[part 2 of 3: package /CommunicationClusters]
AUTOSAR XML (schema 4-2-2)
package /CommunicationClusters  (continued)
  can cluster ZCUD_CAN1: baudrate=500000, protocol-name=CAN, protocol-version=CAN
    can physical channel ZCUD_CAN1: comm-connectors=ZCUD_CAN1_SRS3
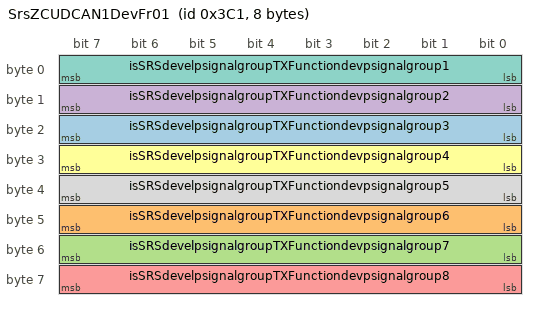
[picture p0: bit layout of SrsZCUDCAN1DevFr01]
      frame SrsZCUDCAN1DevFr01: id 0x3C1, from SRS3, frame-length=8, can-addressing-mode=STANDARD, can-fd-frame-support=false, can-frame-tx-behavior=CAN-20
        pdu SrsZCUDCAN1DevSignalPdu01: length=8, minimum-delay=0.095, transmission-mode-condition{data-filter=data-filter-type=ALWAYS, i-signal-in-i-pdu=igSRSdevelpsignalgroupTX_mtx}, transmission-mode-true-timing=event-controlled-timing=number-of-repetitions=0, unused-bit-pattern=0
          signal isSRSdevelpsignalgroupTXFunctiondevpsignalgroup3: start 23, 8 bit, big-endian, data-type-policy=NETWORK-REPRESENTATION-FROM-COM-SPEC, init-value=0, base-type=UInt8_2, compu-method=UInt8_1, category=VALUE, transfer-property=TRIGGERED  # SRS development signal
          signal isSRSdevelpsignalgroupTXFunctiondevpsignalgroup6: start 47, 8 bit, big-endian, data-type-policy=NETWORK-REPRESENTATION-FROM-COM-SPEC, init-value=0, base-type=UInt8_2, compu-method=UInt8_1, category=VALUE, transfer-property=TRIGGERED  # SRS development signal
          signal isSRSdevelpsignalgroupTXFunctiondevpsignalgroup7: start 55, 8 bit, big-endian, data-type-policy=NETWORK-REPRESENTATION-FROM-COM-SPEC, init-value=0, base-type=UInt8_2, compu-method=UInt8_1, category=VALUE, transfer-property=TRIGGERED  # SRS development signal
          signal isSRSdevelpsignalgroupTXFunctiondevpsignalgroup2: start 15, 8 bit, big-endian, data-type-policy=NETWORK-REPRESENTATION-FROM-COM-SPEC, init-value=0, base-type=UInt8_2, compu-method=UInt8_1, category=VALUE, transfer-property=TRIGGERED  # SRS development signal
          signal isSRSdevelpsignalgroupTXFunctiondevpsignalgroup8: start 63, 8 bit, big-endian, data-type-policy=NETWORK-REPRESENTATION-FROM-COM-SPEC, init-value=0, base-type=UInt8_2, compu-method=UInt8_1, category=VALUE, transfer-property=TRIGGERED  # SRS development signal
          signal isSRSdevelpsignalgroupTXFunctiondevpsignalgroup4: start 31, 8 bit, big-endian, data-type-policy=NETWORK-REPRESENTATION-FROM-COM-SPEC, init-value=0, base-type=UInt8_2, compu-method=UInt8_1, category=VALUE, transfer-property=TRIGGERED  # SRS development signal
          signal isSRSdevelpsignalgroupTXFunctiondevpsignalgroup1: start 7, 8 bit, big-endian, data-type-policy=NETWORK-REPRESENTATION-FROM-COM-SPEC, init-value=0, base-type=UInt8_2, compu-method=UInt8_1, category=VALUE, transfer-property=TRIGGERED  # SRS development signal
          signal isSRSdevelpsignalgroupTXFunctiondevpsignalgroup5: start 39, 8 bit, big-endian, data-type-policy=NETWORK-REPRESENTATION-FROM-COM-SPEC, init-value=0, base-type=UInt8_2, compu-method=UInt8_1, category=VALUE, transfer-property=TRIGGERED  # SRS development signal
          mapping igSRSdevelpsignalgroupTX_mtx: i-signal-group=igSRSdevelpsignalgroupTX, packing-byte-order=big-endian, start-position=7, transfer-property=TRIGGERED
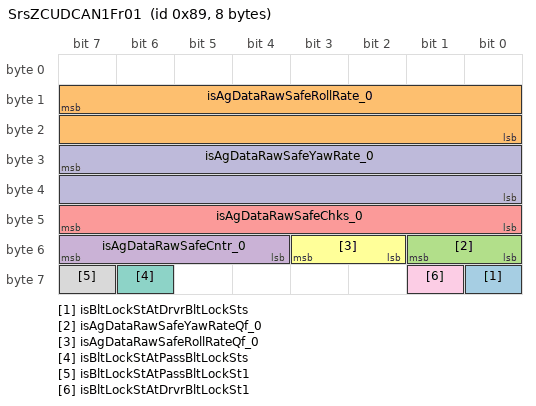
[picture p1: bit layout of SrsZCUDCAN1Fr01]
      frame SrsZCUDCAN1Fr01: id 0x89, from SRS3, frame-length=8, can-addressing-mode=STANDARD, can-fd-frame-support=false, can-frame-tx-behavior=CAN-20
        pdu SrsZCUDCAN1SignalPdu01: length=8, transmission-mode-condition{data-filter=data-filter-type=ALWAYS, i-signal-in-i-pdu=igAgDataRawSafe_0_mtx}, transmission-mode-true-timing=cyclic-timing={time-offset=0.0, time-period=0.01}, unused-bit-pattern=0
          signal isBltLockStAtDrvrBltLockSts: start 56, 1 bit, big-endian, data-type-policy=NETWORK-REPRESENTATION-FROM-COM-SPEC, init-value=0, base-type=DevErrSts2_2, compu-method=DevErrSts2_1, category=VALUE, transfer-property=PENDING  # State of belt lock at driver seating position Belt lock status, OK/NOK
          signal isAgDataRawSafeRollRate_0: start 15, 16 bit, big-endian, data-type-policy=NETWORK-REPRESENTATION-FROM-COM-SPEC, init-value=0, base-type=AgSpd34_2, compu-method=AgSpd34_1, category=VALUE, transfer-property=PENDING  # IMU angular rate data. Roll Rate
          signal isAgDataRawSafeYawRateQf_0: start 49, 2 bit, big-endian, data-type-policy=NETWORK-REPRESENTATION-FROM-COM-SPEC, init-value=1, base-type=Qf1_2, compu-method=Qf1_1, category=VALUE, transfer-property=PENDING  # IMU angular rate data. Quality Factor for Yaw Rate
          signal isAgDataRawSafeCntr_0: start 55, 4 bit, big-endian, data-type-policy=NETWORK-REPRESENTATION-FROM-COM-SPEC, init-value=0, base-type=UInt4_2, compu-method=UInt4_1, category=VALUE, transfer-property=PENDING  # IMU angular rate data. Counter
          signal isAgDataRawSafeChks_0: start 47, 8 bit, big-endian, data-type-policy=NETWORK-REPRESENTATION-FROM-COM-SPEC, init-value=255, base-type=UInt8_2, compu-method=UInt8_1, category=VALUE, transfer-property=PENDING  # IMU angular rate data. Check summa
          signal isAgDataRawSafeRollRateQf_0: start 51, 2 bit, big-endian, data-type-policy=NETWORK-REPRESENTATION-FROM-COM-SPEC, init-value=1, base-type=Qf1_2, compu-method=Qf1_1, category=VALUE, transfer-property=PENDING  # IMU angular rate data. Quality factor for Roll Rate
          signal isBltLockStAtPassBltLockSts: start 62, 1 bit, big-endian, data-type-policy=NETWORK-REPRESENTATION-FROM-COM-SPEC, init-value=0, base-type=DevErrSts2_2, compu-method=DevErrSts2_1, category=VALUE, transfer-property=PENDING  # State of belt lock at passenger seating position Belt lock status, OK/NOK
          signal isBltLockStAtPassBltLockSt1: start 63, 1 bit, big-endian, data-type-policy=NETWORK-REPRESENTATION-FROM-COM-SPEC, init-value=1, base-type=BltLockSt1_2, compu-method=BltLockSt1_1, category=VALUE, transfer-property=PENDING  # State of belt lock at passenger seating position Belt lock state, locked/unlocked
          signal isBltLockStAtDrvrBltLockSt1: start 57, 1 bit, big-endian, data-type-policy=NETWORK-REPRESENTATION-FROM-COM-SPEC, init-value=1, base-type=BltLockSt1_2, compu-method=BltLockSt1_1, category=VALUE, transfer-property=PENDING  # State of belt lock at driver seating position Belt lock state, locked/unlocked
          signal isAgDataRawSafeYawRate_0: start 31, 16 bit, big-endian, data-type-policy=NETWORK-REPRESENTATION-FROM-COM-SPEC, init-value=0, base-type=AgSpd34_2, compu-method=AgSpd34_1, category=VALUE, transfer-property=PENDING  # IMU angular rate data. Yaw Rate
          mapping igBltLockStAtPass_mtx: i-signal-group=igBltLockStAtPass, packing-byte-order=big-endian, start-position=63, transfer-property=PENDING, update-indication-bit-position=6
          mapping igBltLockStAtDrvr_mtx: i-signal-group=igBltLockStAtDrvr, packing-byte-order=big-endian, start-position=57, transfer-property=PENDING, update-indication-bit-position=7
          mapping igAgDataRawSafe_0_mtx: i-signal-group=igAgDataRawSafe_0, packing-byte-order=big-endian, start-position=15, transfer-property=PENDING, update-indication-bit-position=5
      frame SrsZCUDCAN1Fr11: id 0x22F, from SRS3, frame-length=8, can-addressing-mode=STANDARD, can-fd-frame-support=false, can-frame-tx-behavior=CAN-20
        pdu SrsZCUDCAN1SignalPdu11: length=8, transmission-mode-condition{data-filter=data-filter-type=ALWAYS, i-signal-in-i-pdu=isDstTrvldFromSftyBkp_mtx}, transmission-mode-true-timing=cyclic-timing={time-offset=0.0, time-period=0.1}, unused-bit-pattern=0
          signal isPassMidSeatSts: start 7, 2 bit, big-endian, data-type-policy=NETWORK-REPRESENTATION-FROM-COM-SPEC, init-value=0, base-type=PassSeatSts1_2, compu-method=PassSeatSts1_1, transfer-property=PENDING, update-indication-bit-position=5  # Occupation status based on occupant detection sensor at front row middle seat.
          signal isSRSIntVolt: start 39, 8 bit, big-endian, data-type-policy=NETWORK-REPRESENTATION-FROM-COM-SPEC, init-value=0, base-type=U55_1, compu-method=U55_1, transfer-property=PENDING, update-indication-bit-position=28  # SRS internal voltage
          signal isDstTrvldVldFromSftyBkp: start 31, 1 bit, big-endian, data-type-policy=NETWORK-REPRESENTATION-FROM-COM-SPEC, init-value=0, base-type=InvldVld1_2, compu-method=InvldVld1_1, transfer-property=PENDING, update-indication-bit-position=29  # Indication if the transmitted backupvalue is valid or not
          signal isDstTrvldFromSftyBkp: start 4, 21 bit, big-endian, data-type-policy=NETWORK-REPRESENTATION-FROM-COM-SPEC, init-value=0, base-type=Len31_2, compu-method=Len31_1, transfer-property=PENDING, update-indication-bit-position=30  # Saved backupvalue
          signal isNotifForEmgyCall: start 27, 1 bit, big-endian, data-type-policy=NETWORK-REPRESENTATION-FROM-COM-SPEC, init-value=0, base-type=Boolean_2, compu-method=Boolean_1, transfer-property=PENDING, update-indication-bit-position=26  # Information if there is a need for the vehicle to perform an emergency call.
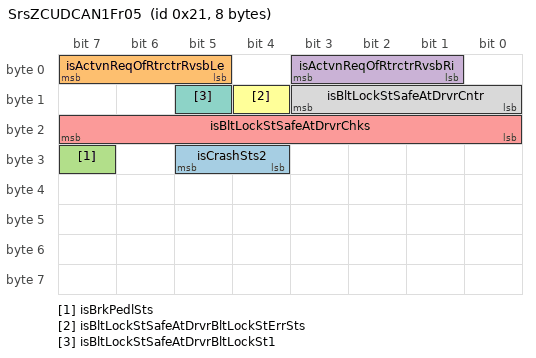
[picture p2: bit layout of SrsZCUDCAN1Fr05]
      frame SrsZCUDCAN1Fr05: id 0x21, from SRS3, frame-length=8, can-addressing-mode=STANDARD, can-fd-frame-support=false, can-frame-tx-behavior=CAN-20
        pdu SrsZCUDCAN1SignalPdu05: length=8, transmission-mode-condition{data-filter=data-filter-type=ALWAYS, i-signal-in-i-pdu=igBltLockStSafeAtDrvr_mtx}, transmission-mode-true-timing=cyclic-timing={time-offset=0.0, time-period=0.01}, unused-bit-pattern=0
          signal isCrashSts2: start 29, 2 bit, big-endian, data-type-policy=NETWORK-REPRESENTATION-FROM-COM-SPEC, init-value=0, base-type=CrashSts4_1, compu-method=CrashSts4_1, transfer-property=TRIGGERED, update-indication-bit-position=30  # Information if a crash or slight crash has been detected by SRS.
          signal isActvnReqOfRtrctrRvsbLe: start 7, 3 bit, big-endian, data-type-policy=NETWORK-REPRESENTATION-FROM-COM-SPEC, init-value=0, base-type=ActvnReqOfRtrctrRvsb1_2, compu-method=ActvnReqOfRtrctrRvsb1_1, transfer-property=PENDING, update-indication-bit-position=4  # Belt pre-tensioning request from the DART/CWS algo in the SRS.
          signal isBrkPedlSts: start 31, 1 bit, big-endian, data-type-policy=NETWORK-REPRESENTATION-FROM-COM-SPEC, init-value=0, base-type=OkNotOk1_2, compu-method=OkNotOk1_1, transfer-property=PENDING, update-indication-bit-position=15  # If the brake pedal decoupling has been activated.
          signal isActvnReqOfRtrctrRvsbRi: start 3, 3 bit, big-endian, data-type-policy=NETWORK-REPRESENTATION-FROM-COM-SPEC, init-value=0, base-type=ActvnReqOfRtrctrRvsb1_2, compu-method=ActvnReqOfRtrctrRvsb1_1, transfer-property=PENDING, update-indication-bit-position=0  # Belt pre-tensioning request from the DART/CWS algo in the SRS.
          signal isBltLockStSafeAtDrvrChks: start 23, 8 bit, big-endian, data-type-policy=NETWORK-REPRESENTATION-FROM-COM-SPEC, init-value=255, base-type=UInt8_2, compu-method=UInt8_1, category=VALUE, transfer-property=PENDING  # Counter for E2E
          signal isBltLockStSafeAtDrvrBltLockStErrSts: start 12, 1 bit, big-endian, data-type-policy=NETWORK-REPRESENTATION-FROM-COM-SPEC, init-value=0, base-type=DevErrSts2_2, compu-method=DevErrSts2_1, category=VALUE, transfer-property=PENDING  # State of belt lock at driver seating position Belt lock status, OK/NOK
          signal isBltLockStSafeAtDrvrBltLockSt1: start 13, 1 bit, big-endian, data-type-policy=NETWORK-REPRESENTATION-FROM-COM-SPEC, init-value=1, base-type=BltLockSt1_2, compu-method=BltLockSt1_1, category=VALUE, transfer-property=PENDING  # State of belt lock at driver seating position Belt lock state, locked/unlocked
          signal isBltLockStSafeAtDrvrCntr: start 11, 4 bit, big-endian, data-type-policy=NETWORK-REPRESENTATION-FROM-COM-SPEC, init-value=0, base-type=UInt4_2, compu-method=UInt4_1, category=VALUE, transfer-property=PENDING  # Checksum for E2E
          mapping igBltLockStSafeAtDrvr_mtx: i-signal-group=igBltLockStSafeAtDrvr, packing-byte-order=big-endian, start-position=13, transfer-property=PENDING, update-indication-bit-position=14
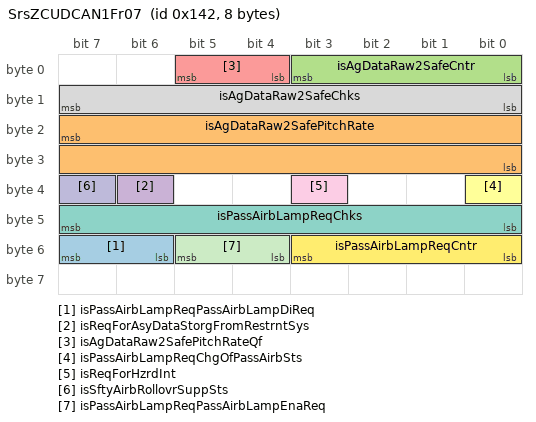
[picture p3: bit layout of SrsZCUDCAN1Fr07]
      frame SrsZCUDCAN1Fr07: id 0x142, from SRS3, frame-length=8, can-addressing-mode=STANDARD, can-fd-frame-support=false, can-frame-tx-behavior=CAN-20
        pdu SrsZCUDCAN1SignalPdu07: length=8, transmission-mode-condition{data-filter=data-filter-type=ALWAYS, i-signal-in-i-pdu=igAgDataRaw2Safe_mtx}, transmission-mode-true-timing=cyclic-timing={time-offset=0.0, time-period=0.03}, unused-bit-pattern=0
          signal isPassAirbLampReqPassAirbLampDiReq: start 55, 2 bit, big-endian, data-type-policy=NETWORK-REPRESENTATION-FROM-COM-SPEC, init-value=2, base-type=PassAirbLampReq_2, compu-method=PassAirbLampReq_1, category=VALUE, transfer-property=PENDING  # Indication request for passenger airbag lamp status. Requested status for PAD lamp
          signal isAgDataRaw2SafePitchRate: start 23, 16 bit, big-endian, data-type-policy=NETWORK-REPRESENTATION-FROM-COM-SPEC, init-value=0, base-type=AgSpd34_2, compu-method=AgSpd34_1, category=VALUE, transfer-property=PENDING  # IMU pitch rate data. Pitch Rate
          signal isAgDataRaw2SafeCntr: start 3, 4 bit, big-endian, data-type-policy=NETWORK-REPRESENTATION-FROM-COM-SPEC, init-value=0, base-type=UInt4_2, compu-method=UInt4_1, category=VALUE, transfer-property=PENDING  # IMU pitch rate data. Counter
          signal isReqForAsyDataStorgFromRestrntSys: start 38, 1 bit, big-endian, data-type-policy=NETWORK-REPRESENTATION-FROM-COM-SPEC, init-value=0, base-type=Boolean_2, compu-method=Boolean_1, transfer-property=PENDING, update-indication-bit-position=37  # ASY Data Storg from restrn system
          signal isAgDataRaw2SafePitchRateQf: start 5, 2 bit, big-endian, data-type-policy=NETWORK-REPRESENTATION-FROM-COM-SPEC, init-value=1, base-type=Qf1_2, compu-method=Qf1_1, category=VALUE, transfer-property=PENDING  # IMU pitch rate data. Quality factor for Pitch Rate
          signal isPassAirbLampReqChgOfPassAirbSts: start 32, 1 bit, big-endian, data-type-policy=NETWORK-REPRESENTATION-FROM-COM-SPEC, init-value=0, base-type=ReqForDisp_2, compu-method=ReqForDisp_1, category=VALUE, transfer-property=PENDING  # Indication request for passenger airbag lamp status. Reqest for indication of passenger airbag status in DIM
          signal isPassAirbLampReqChks: start 47, 8 bit, big-endian, data-type-policy=NETWORK-REPRESENTATION-FROM-COM-SPEC, init-value=255, base-type=UInt8_2, compu-method=UInt8_1, category=VALUE, transfer-property=PENDING  # Indication request for passenger airbag lamp status. Checksum for validity check of PAD and PAE request messages
          signal isAgDataRaw2SafeChks: start 15, 8 bit, big-endian, data-type-policy=NETWORK-REPRESENTATION-FROM-COM-SPEC, init-value=255, base-type=UInt8_2, compu-method=UInt8_1, category=VALUE, transfer-property=PENDING  # IMU pitch rate data. Check sum
          signal isReqForHzrdInt: start 35, 1 bit, big-endian, data-type-policy=NETWORK-REPRESENTATION-FROM-COM-SPEC, init-value=0, base-type=ReqForHzrdInt_1, compu-method=ReqForHzrdInt_1, transfer-property=PENDING, update-indication-bit-position=34  # 0-Lower crash not happen 1-Lower crash happened
          signal isSftyAirbRollovrSuppSts: start 39, 1 bit, big-endian, data-type-policy=NETWORK-REPRESENTATION-FROM-COM-SPEC, init-value=0, base-type=OnOff1_2, compu-method=OnOff1_1, transfer-property=PENDING, update-indication-bit-position=7  # Roll-over deactivation actual state
          signal isPassAirbLampReqPassAirbLampEnaReq: start 53, 2 bit, big-endian, data-type-policy=NETWORK-REPRESENTATION-FROM-COM-SPEC, init-value=2, base-type=PassAirbLampReq_2, compu-method=PassAirbLampReq_1, category=VALUE, transfer-property=PENDING  # Indication request for passenger airbag lamp status. Requested status for PAE Lamp
          signal isPassAirbLampReqCntr: start 51, 4 bit, big-endian, data-type-policy=NETWORK-REPRESENTATION-FROM-COM-SPEC, init-value=0, base-type=UInt4_2, compu-method=UInt4_1, category=VALUE, transfer-property=PENDING  # Indication request for passenger airbag lamp status. Counter for validity check of PAD and PAE request messages
          mapping igAgDataRaw2Safe_mtx: i-signal-group=igAgDataRaw2Safe, packing-byte-order=big-endian, start-position=5, transfer-property=PENDING, update-indication-bit-position=6
          mapping igPassAirbLampReq_mtx: i-signal-group=igPassAirbLampReq, packing-byte-order=big-endian, start-position=32, transfer-property=PENDING, update-indication-bit-position=33
      frame SrsZCUDCAN1VFCVectorFr: id 0x55B, from SRS3, frame-length=8, can-addressing-mode=STANDARD, can-fd-frame-support=false, can-frame-tx-behavior=CAN-20
        pdu SrsZCUDCAN1VFCVectorSignalIPdu: length=8, transmission-mode-condition{data-filter=data-filter-type=ALWAYS, i-signal-in-i-pdu=igVFCVectorSRS_0_mtx}, transmission-mode-true-timing=cyclic-timing={time-offset=0.0, time-period=1.0}, unused-bit-pattern=0
          signal isVFCVectorSRSVFCid56_0: start 58, 1 bit, big-endian, data-type-policy=NETWORK-REPRESENTATION-FROM-COM-SPEC, init-value=0, base-type=VFCOnOff_4, compu-method=VFCOnOff_4, category=VALUE, transfer-property=PENDING  # BackboneFlexray
          signal isVFCVectorSRSVFCid36_0: start 38, 1 bit, big-endian, data-type-policy=NETWORK-REPRESENTATION-FROM-COM-SPEC, init-value=0, base-type=VFCOnOff_4, compu-method=VFCOnOff_4, category=VALUE, transfer-property=PENDING  # Immobilizer
          signal isVFCVectorSRSVFCid53_0: start 55, 1 bit, big-endian, data-type-policy=NETWORK-REPRESENTATION-FROM-COM-SPEC, init-value=0, base-type=VFCOnOff_4, compu-method=VFCOnOff_4, category=VALUE, transfer-property=PENDING  # VisualAssist
          signal isVFCVectorSRSVFCid32_0: start 34, 1 bit, big-endian, data-type-policy=NETWORK-REPRESENTATION-FROM-COM-SPEC, init-value=0, base-type=VFCOnOff_4, compu-method=VFCOnOff_4, category=VALUE, transfer-property=PENDING  # VFC32
          signal isVFCVectorSRSVFCid12_0: start 14, 1 bit, big-endian, data-type-policy=NETWORK-REPRESENTATION-FROM-COM-SPEC, init-value=0, base-type=VFCOnOff_4, compu-method=VFCOnOff_4, category=VALUE, transfer-property=PENDING  # Alarm
          signal isVFCVectorSRSVFCid28_0: start 30, 1 bit, big-endian, data-type-policy=NETWORK-REPRESENTATION-FROM-COM-SPEC, init-value=0, base-type=VFCOnOff_4, compu-method=VFCOnOff_4, category=VALUE, transfer-property=PENDING  # HVEnergyStorage
          signal isVFCVectorSRSVFCid1_0: start 3, 1 bit, big-endian, data-type-policy=NETWORK-REPRESENTATION-FROM-COM-SPEC, init-value=0, base-type=VFCOnOff_4, compu-method=VFCOnOff_4, category=VALUE, transfer-property=PENDING  # ParkingDrivingClimatization
          signal isVFCVectorSRSVFCid37_0: start 39, 1 bit, big-endian, data-type-policy=NETWORK-REPRESENTATION-FROM-COM-SPEC, init-value=0, base-type=VFCOnOff_4, compu-method=VFCOnOff_4, category=VALUE, transfer-property=PENDING  # Windows
          signal isVFCVectorSRSVFCid11_0: start 13, 1 bit, big-endian, data-type-policy=NETWORK-REPRESENTATION-FROM-COM-SPEC, init-value=0, base-type=VFCOnOff_4, compu-method=VFCOnOff_4, category=VALUE, transfer-property=PENDING  # VFC11
          signal isVFCVectorSRSVFCid15_0: start 17, 1 bit, big-endian, data-type-policy=NETWORK-REPRESENTATION-FROM-COM-SPEC, init-value=0, base-type=VFCOnOff_4, compu-method=VFCOnOff_4, category=VALUE, transfer-property=PENDING  # VFC15
          signal isVFCVectorSRSVFCid49_0: start 51, 1 bit, big-endian, data-type-policy=NETWORK-REPRESENTATION-FROM-COM-SPEC, init-value=0, base-type=VFCOnOff_4, compu-method=VFCOnOff_4, category=VALUE, transfer-property=PENDING  # ChargingLVInit
          signal isVFCVectorSRSVFCid42_0: start 44, 1 bit, big-endian, data-type-policy=NETWORK-REPRESENTATION-FROM-COM-SPEC, init-value=0, base-type=VFCOnOff_4, compu-method=VFCOnOff_4, category=VALUE, transfer-property=PENDING  # ChargingHV
          signal isVFCVectorSRSVFCid34_0: start 36, 1 bit, big-endian, data-type-policy=NETWORK-REPRESENTATION-FROM-COM-SPEC, init-value=0, base-type=VFCOnOff_4, compu-method=VFCOnOff_4, category=VALUE, transfer-property=PENDING  # VehicleModeManagement
          signal isVFCVectorSRSVFCid30_0: start 32, 1 bit, big-endian, data-type-policy=NETWORK-REPRESENTATION-FROM-COM-SPEC, init-value=0, base-type=VFCOnOff_4, compu-method=VFCOnOff_4, category=VALUE, transfer-property=PENDING  # TelematicsConnectivity
          signal isVFCVectorSRSVFCid21_0: start 23, 1 bit, big-endian, data-type-policy=NETWORK-REPRESENTATION-FROM-COM-SPEC, init-value=0, base-type=VFCOnOff_4, compu-method=VFCOnOff_4, category=VALUE, transfer-property=PENDING  # PowerClosures
          signal isVFCVectorSRSVFCid26_0: start 28, 1 bit, big-endian, data-type-policy=NETWORK-REPRESENTATION-FROM-COM-SPEC, init-value=0, base-type=VFCOnOff_4, compu-method=VFCOnOff_4, category=VALUE, transfer-property=PENDING  # Brake
          signal isVFCVectorSRSVFCid18_0: start 20, 1 bit, big-endian, data-type-policy=NETWORK-REPRESENTATION-FROM-COM-SPEC, init-value=0, base-type=VFCOnOff_4, compu-method=VFCOnOff_4, category=VALUE, transfer-property=PENDING  # PropulsionStart
          signal isVFCVectorSRSVFCid46_0: start 48, 1 bit, big-endian, data-type-policy=NETWORK-REPRESENTATION-FROM-COM-SPEC, init-value=0, base-type=VFCOnOff_4, compu-method=VFCOnOff_4, category=VALUE, transfer-property=PENDING  # ExteriorLightsHazard
          signal isVFCVectorSRSVFCid55_0: start 57, 1 bit, big-endian, data-type-policy=NETWORK-REPRESENTATION-FROM-COM-SPEC, init-value=0, base-type=VFCOnOff_4, compu-method=VFCOnOff_4, category=VALUE, transfer-property=PENDING  # LifeDetection
          signal isVFCVectorSRSVFCid54_0: start 56, 1 bit, big-endian, data-type-policy=NETWORK-REPRESENTATION-FROM-COM-SPEC, init-value=0, base-type=VFCOnOff_4, compu-method=VFCOnOff_4, category=VALUE, transfer-property=PENDING  # PassiveSafety
          signal isVFCVectorSRSVFCid19_0: start 21, 1 bit, big-endian, data-type-policy=NETWORK-REPRESENTATION-FROM-COM-SPEC, init-value=0, base-type=VFCOnOff_4, compu-method=VFCOnOff_4, category=VALUE, transfer-property=PENDING  # VFC19
          signal isVFCVectorSRSVFCid27_0: start 29, 1 bit, big-endian, data-type-policy=NETWORK-REPRESENTATION-FROM-COM-SPEC, init-value=0, base-type=VFCOnOff_4, compu-method=VFCOnOff_4, category=VALUE, transfer-property=PENDING  # InfotainmentPoll
          signal isVFCVectorSRSVFCid43_0: start 45, 1 bit, big-endian, data-type-policy=NETWORK-REPRESENTATION-FROM-COM-SPEC, init-value=0, base-type=VFCOnOff_4, compu-method=VFCOnOff_4, category=VALUE, transfer-property=PENDING  # BodyPreClimatisation
          signal isVFCVectorSRSVFCid14_0: start 16, 1 bit, big-endian, data-type-policy=NETWORK-REPRESENTATION-FROM-COM-SPEC, init-value=0, base-type=VFCOnOff_4, compu-method=VFCOnOff_4, category=VALUE, transfer-property=PENDING  # InteriorLighting
          signal isVFCVectorSRSVFCid0_0: start 2, 1 bit, big-endian, data-type-policy=NETWORK-REPRESENTATION-FROM-COM-SPEC, init-value=0, base-type=VFCOnOff_4, compu-method=VFCOnOff_4, category=VALUE, transfer-property=PENDING  # SettingsComfort
          signal isVFCVectorSRSVFCid44_0: start 46, 1 bit, big-endian, data-type-policy=NETWORK-REPRESENTATION-FROM-COM-SPEC, init-value=0, base-type=VFCOnOff_4, compu-method=VFCOnOff_4, category=VALUE, transfer-property=PENDING  # Crash
          signal isVFCVectorSRSVFCid61_0: start 63, 1 bit, big-endian, data-type-policy=NETWORK-REPRESENTATION-FROM-COM-SPEC, init-value=0, base-type=VFCOnOff_4, compu-method=VFCOnOff_4, category=VALUE, transfer-property=PENDING  # VFC61
          signal isVFCVectorSRSVFCid3_0: start 5, 1 bit, big-endian, data-type-policy=NETWORK-REPRESENTATION-FROM-COM-SPEC, init-value=0, base-type=VFCOnOff_4, compu-method=VFCOnOff_4, category=VALUE, transfer-property=PENDING  # PowertrainParkingClimatization
          signal isVFCVectorSRSVFCid4_0: start 6, 1 bit, big-endian, data-type-policy=NETWORK-REPRESENTATION-FROM-COM-SPEC, init-value=0, base-type=VFCOnOff_4, compu-method=VFCOnOff_4, category=VALUE, transfer-property=PENDING  # VFC4
          signal isVFCVectorSRSVFCid8_0: start 10, 1 bit, big-endian, data-type-policy=NETWORK-REPRESENTATION-FROM-COM-SPEC, init-value=0, base-type=VFCOnOff_4, compu-method=VFCOnOff_4, category=VALUE, transfer-property=PENDING  # VFC8
          signal isVFCVectorSRSVFCid25_0: start 27, 1 bit, big-endian, data-type-policy=NETWORK-REPRESENTATION-FROM-COM-SPEC, init-value=0, base-type=VFCOnOff_4, compu-method=VFCOnOff_4, category=VALUE, transfer-property=PENDING  # SeatComfortFunctions
          signal isVFCVectorSRSVFCid39_0: start 41, 1 bit, big-endian, data-type-policy=NETWORK-REPRESENTATION-FROM-COM-SPEC, init-value=0, base-type=VFCOnOff_4, compu-method=VFCOnOff_4, category=VALUE, transfer-property=PENDING  # VFC39
          signal isVFCVectorSRSVFCid6_0: start 8, 1 bit, big-endian, data-type-policy=NETWORK-REPRESENTATION-FROM-COM-SPEC, init-value=0, base-type=VFCOnOff_4, compu-method=VFCOnOff_4, category=VALUE, transfer-property=PENDING  # SettingsVehicle
          signal isVFCVectorSRSVFCid23_0: start 25, 1 bit, big-endian, data-type-policy=NETWORK-REPRESENTATION-FROM-COM-SPEC, init-value=0, base-type=VFCOnOff_4, compu-method=VFCOnOff_4, category=VALUE, transfer-property=PENDING  # VFC23
          signal isVFCVectorSRSVFCid24_0: start 26, 1 bit, big-endian, data-type-policy=NETWORK-REPRESENTATION-FROM-COM-SPEC, init-value=0, base-type=VFCOnOff_4, compu-method=VFCOnOff_4, category=VALUE, transfer-property=PENDING  # SettingsProfile
          signal isVFCVectorSRSVFCid57_0: start 59, 1 bit, big-endian, data-type-policy=NETWORK-REPRESENTATION-FROM-COM-SPEC, init-value=0, base-type=VFCOnOff_4, compu-method=VFCOnOff_4, category=VALUE, transfer-property=PENDING  # Functionmarket
          signal isVFCVectorSRSVFCid13_0: start 15, 1 bit, big-endian, data-type-policy=NETWORK-REPRESENTATION-FROM-COM-SPEC, init-value=0, base-type=VFCOnOff_4, compu-method=VFCOnOff_4, category=VALUE, transfer-property=PENDING  # VFC13
          signal isVFCVectorSRSVFCid47_0: start 49, 1 bit, big-endian, data-type-policy=NETWORK-REPRESENTATION-FROM-COM-SPEC, init-value=0, base-type=VFCOnOff_4, compu-method=VFCOnOff_4, category=VALUE, transfer-property=PENDING  # VFC47
          signal isVFCVectorSRSVFCid35_0: start 37, 1 bit, big-endian, data-type-policy=NETWORK-REPRESENTATION-FROM-COM-SPEC, init-value=0, base-type=VFCOnOff_4, compu-method=VFCOnOff_4, category=VALUE, transfer-property=PENDING  # TrailerCaravanFunctions
          signal isVFCVectorSRSVFCid2_0: start 4, 1 bit, big-endian, data-type-policy=NETWORK-REPRESENTATION-FROM-COM-SPEC, init-value=0, base-type=VFCOnOff_4, compu-method=VFCOnOff_4, category=VALUE, transfer-property=PENDING  # PostClimatisation
          signal isVFCVectorSRSVFCid7_0: start 9, 1 bit, big-endian, data-type-policy=NETWORK-REPRESENTATION-FROM-COM-SPEC, init-value=0, base-type=VFCOnOff_4, compu-method=VFCOnOff_4, category=VALUE, transfer-property=PENDING  # VFC7
          signal isVFCVectorSRSVFCid40_0: start 42, 1 bit, big-endian, data-type-policy=NETWORK-REPRESENTATION-FROM-COM-SPEC, init-value=0, base-type=VFCOnOff_4, compu-method=VFCOnOff_4, category=VALUE, transfer-property=PENDING  # VFC40
          signal isVFCVectorSRSVFCid9_0: start 11, 1 bit, big-endian, data-type-policy=NETWORK-REPRESENTATION-FROM-COM-SPEC, init-value=0, base-type=VFCOnOff_4, compu-method=VFCOnOff_4, category=VALUE, transfer-property=PENDING  # IPWakeup
          signal isVFCVectorSRSVFCid60_0: start 62, 1 bit, big-endian, data-type-policy=NETWORK-REPRESENTATION-FROM-COM-SPEC, init-value=0, base-type=VFCOnOff_4, compu-method=VFCOnOff_4, category=VALUE, transfer-property=PENDING  # VFC60
          signal isVFCVectorSRSBlockID_0: start 1, 2 bit, big-endian, data-type-policy=NETWORK-REPRESENTATION-FROM-COM-SPEC, init-value=0, base-type=BlockID_3, compu-method=BlockID_2, category=VALUE, transfer-property=PENDING  # BlockID
          signal isVFCVectorSRSVFCid5_0: start 7, 1 bit, big-endian, data-type-policy=NETWORK-REPRESENTATION-FROM-COM-SPEC, init-value=0, base-type=VFCOnOff_4, compu-method=VFCOnOff_4, category=VALUE, transfer-property=PENDING  # VFC5
          signal isVFCVectorSRSVFCid29_0: start 31, 1 bit, big-endian, data-type-policy=NETWORK-REPRESENTATION-FROM-COM-SPEC, init-value=0, base-type=VFCOnOff_4, compu-method=VFCOnOff_4, category=VALUE, transfer-property=PENDING  # VFC29
          signal isVFCVectorSRSVFCid22_0: start 24, 1 bit, big-endian, data-type-policy=NETWORK-REPRESENTATION-FROM-COM-SPEC, init-value=0, base-type=VFCOnOff_4, compu-method=VFCOnOff_4, category=VALUE, transfer-property=PENDING  # VehicleDriving
          signal isVFCVectorSRSVFCid31_0: start 33, 1 bit, big-endian, data-type-policy=NETWORK-REPRESENTATION-FROM-COM-SPEC, init-value=0, base-type=VFCOnOff_4, compu-method=VFCOnOff_4, category=VALUE, transfer-property=PENDING  # VFC31
          signal isVFCVectorSRSVFCid52_0: start 54, 1 bit, big-endian, data-type-policy=NETWORK-REPRESENTATION-FROM-COM-SPEC, init-value=0, base-type=VFCOnOff_4, compu-method=VFCOnOff_4, category=VALUE, transfer-property=PENDING  # HVBatteryThermalEventWarning
          signal isVFCVectorSRSVFCid38_0: start 40, 1 bit, big-endian, data-type-policy=NETWORK-REPRESENTATION-FROM-COM-SPEC, init-value=0, base-type=VFCOnOff_4, compu-method=VFCOnOff_4, category=VALUE, transfer-property=PENDING  # Visibility
          signal isVFCVectorSRSVFCid41_0: start 43, 1 bit, big-endian, data-type-policy=NETWORK-REPRESENTATION-FROM-COM-SPEC, init-value=0, base-type=VFCOnOff_4, compu-method=VFCOnOff_4, category=VALUE, transfer-property=PENDING  # InfotainmentPush
          signal isVFCVectorSRSVFCid17_0: start 19, 1 bit, big-endian, data-type-policy=NETWORK-REPRESENTATION-FROM-COM-SPEC, init-value=0, base-type=VFCOnOff_4, compu-method=VFCOnOff_4, category=VALUE, transfer-property=PENDING  # RemoteKeyFunctionality
          signal isVFCVectorSRSVFCid33_0: start 35, 1 bit, big-endian, data-type-policy=NETWORK-REPRESENTATION-FROM-COM-SPEC, init-value=0, base-type=VFCOnOff_4, compu-method=VFCOnOff_4, category=VALUE, transfer-property=PENDING  # Diagnostics
          signal isVFCVectorSRSVFCid10_0: start 12, 1 bit, big-endian, data-type-policy=NETWORK-REPRESENTATION-FROM-COM-SPEC, init-value=0, base-type=VFCOnOff_4, compu-method=VFCOnOff_4, category=VALUE, transfer-property=PENDING  # ExteriorLighting
          signal isVFCVectorSRSVFCid45_0: start 47, 1 bit, big-endian, data-type-policy=NETWORK-REPRESENTATION-FROM-COM-SPEC, init-value=0, base-type=VFCOnOff_4, compu-method=VFCOnOff_4, category=VALUE, transfer-property=PENDING  # GlobalShortDuration
          signal isVFCVectorSRSVFCid51_0: start 53, 1 bit, big-endian, data-type-policy=NETWORK-REPRESENTATION-FROM-COM-SPEC, init-value=0, base-type=VFCOnOff_4, compu-method=VFCOnOff_4, category=VALUE, transfer-property=PENDING  # VFC51
          signal isVFCVectorSRSVFCid58_0: start 60, 1 bit, big-endian, data-type-policy=NETWORK-REPRESENTATION-FROM-COM-SPEC, init-value=0, base-type=VFCOnOff_4, compu-method=VFCOnOff_4, category=VALUE, transfer-property=PENDING  # VFC58
          signal isVFCVectorSRSVFCid59_0: start 61, 1 bit, big-endian, data-type-policy=NETWORK-REPRESENTATION-FROM-COM-SPEC, init-value=0, base-type=VFCOnOff_4, compu-method=VFCOnOff_4, category=VALUE, transfer-property=PENDING  # VFC59
          signal isVFCVectorSRSVFCid16_0: start 18, 1 bit, big-endian, data-type-policy=NETWORK-REPRESENTATION-FROM-COM-SPEC, init-value=0, base-type=VFCOnOff_4, compu-method=VFCOnOff_4, category=VALUE, transfer-property=PENDING  # Locking
          signal isVFCVectorSRSVFCid20_0: start 22, 1 bit, big-endian, data-type-policy=NETWORK-REPRESENTATION-FROM-COM-SPEC, init-value=0, base-type=VFCOnOff_4, compu-method=VFCOnOff_4, category=VALUE, transfer-property=PENDING  # VFC20
          signal isVFCVectorSRSVFCid48_0: start 50, 1 bit, big-endian, data-type-policy=NETWORK-REPRESENTATION-FROM-COM-SPEC, init-value=0, base-type=VFCOnOff_4, compu-method=VFCOnOff_4, category=VALUE, transfer-property=PENDING  # DoorOpenWarning
          signal isVFCVectorSRSVFCid50_0: start 52, 1 bit, big-endian, data-type-policy=NETWORK-REPRESENTATION-FROM-COM-SPEC, init-value=0, base-type=VFCOnOff_4, compu-method=VFCOnOff_4, category=VALUE, transfer-property=PENDING  # VFC50
          mapping igVFCVectorSRS_0_mtx: i-signal-group=igVFCVectorSRS_0, packing-byte-order=big-endian, start-position=7, transfer-property=PENDING
      frame SrsZCUDCAN1NMFr01: id 0x51B, from SRS3, frame-length=8, can-addressing-mode=STANDARD, can-fd-frame-support=false, can-frame-tx-behavior=CAN-20
        nm pdu SrsZCUDCAN1NmPdu1: length=8, nm-vote-information=false, unused-bit-pattern=0
          signal isWakeUpReasonsforSRS_0: start 55, 16 bit, big-endian, data-type-policy=NETWORK-REPRESENTATION-FROM-COM-SPEC, init-value=0, base-type=WakeUpReasons_4, compu-method=WakeupReasons_7, transfer-property=PENDING
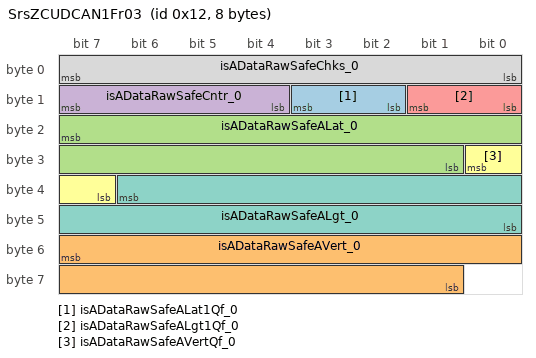
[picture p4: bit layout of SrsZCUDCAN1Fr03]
      frame SrsZCUDCAN1Fr03: id 0x12, from SRS3, frame-length=8, can-addressing-mode=STANDARD, can-fd-frame-support=false, can-frame-tx-behavior=CAN-20
        pdu SrsZCUDCAN1SignalPdu03: length=8, transmission-mode-condition{data-filter=data-filter-type=ALWAYS, i-signal-in-i-pdu=igADataRawSafe_0_mtx}, transmission-mode-true-timing=cyclic-timing={time-offset=0.0, time-period=0.01}, unused-bit-pattern=0
          signal isADataRawSafeALat1Qf_0: start 11, 2 bit, big-endian, data-type-policy=NETWORK-REPRESENTATION-FROM-COM-SPEC, init-value=1, base-type=Qf1_2, compu-method=Qf1_1, category=VALUE, transfer-property=PENDING  # IMU acceleration data Quality factor for Lateral acceleration signal
          signal isADataRawSafeAVert_0: start 55, 15 bit, big-endian, data-type-policy=NETWORK-REPRESENTATION-FROM-COM-SPEC, init-value=1155, base-type=A38_2, compu-method=A38_1, category=VALUE, transfer-property=PENDING  # IMU acceleration data Vertical acceleration
          signal isADataRawSafeALat_0: start 23, 15 bit, big-endian, data-type-policy=NETWORK-REPRESENTATION-FROM-COM-SPEC, init-value=0, base-type=A38_2, compu-method=A38_1, category=VALUE, transfer-property=PENDING  # IMU acceleration data Lateral acceleration
          signal isADataRawSafeCntr_0: start 15, 4 bit, big-endian, data-type-policy=NETWORK-REPRESENTATION-FROM-COM-SPEC, init-value=0, base-type=UInt4_2, compu-method=UInt4_1, category=VALUE, transfer-property=PENDING  # IMU acceleration data Counter
          signal isADataRawSafeALgt1Qf_0: start 9, 2 bit, big-endian, data-type-policy=NETWORK-REPRESENTATION-FROM-COM-SPEC, init-value=1, base-type=Qf1_2, compu-method=Qf1_1, category=VALUE, transfer-property=PENDING  # IMU acceleration data Quality factor for Longitudinal acceleration
          signal isADataRawSafeAVertQf_0: start 24, 2 bit, big-endian, data-type-policy=NETWORK-REPRESENTATION-FROM-COM-SPEC, init-value=1, base-type=Qf1_2, compu-method=Qf1_1, category=VALUE, transfer-property=PENDING  # IMU acceleration data Quality factor for Vertical acceleration
          signal isADataRawSafeALgt_0: start 38, 15 bit, big-endian, data-type-policy=NETWORK-REPRESENTATION-FROM-COM-SPEC, init-value=0, base-type=A38_2, compu-method=A38_1, category=VALUE, transfer-property=PENDING  # IMU acceleration data Longitudinal acceleration
          signal isADataRawSafeChks_0: start 7, 8 bit, big-endian, data-type-policy=NETWORK-REPRESENTATION-FROM-COM-SPEC, init-value=255, base-type=UInt8_2, compu-method=UInt8_1, category=VALUE, transfer-property=PENDING  # IMU acceleration data Check sum
          mapping igADataRawSafe_0_mtx: i-signal-group=igADataRawSafe_0, packing-byte-order=big-endian, start-position=7, transfer-property=PENDING, update-indication-bit-position=56
      frame SrsZCUDCAN1Fr06: id 0x225, from SRS3, frame-length=8, can-addressing-mode=STANDARD, can-fd-frame-support=false, can-frame-tx-behavior=CAN-20
        pdu SrsZCUDCAN1SignalPdu06: length=8, transmission-mode-condition{data-filter=data-filter-type=ALWAYS, i-signal-in-i-pdu=igBltLockStAtPassMid_mtx}, transmission-mode-true-timing=cyclic-timing={time-offset=0.0, time-period=0.25}, unused-bit-pattern=0
          signal isSeatOccptAtRowFrthMid: start 53, 2 bit, big-endian, data-type-policy=NETWORK-REPRESENTATION-FROM-COM-SPEC, init-value=0, base-type=PassSeatSts1_2, compu-method=PassSeatSts1_1, transfer-property=PENDING, update-indication-bit-position=29  # Occupation status based on occupant detection sensor at the 4th middle seat.
          signal isBltLockStAtRowFrthRiBltLockSts: start 45, 1 bit, big-endian, data-type-policy=NETWORK-REPRESENTATION-FROM-COM-SPEC, init-value=1, base-type=DevErrSts2_2, compu-method=DevErrSts2_1, category=VALUE, transfer-property=PENDING  # Belt lock fault status at the 4th row outer right seat. Signal gives out if belt lock is faulty or not.
          signal isSeatOccptAtRowFrthLe: start 55, 2 bit, big-endian, data-type-policy=NETWORK-REPRESENTATION-FROM-COM-SPEC, init-value=0, base-type=PassSeatSts1_2, compu-method=PassSeatSts1_1, transfer-property=PENDING, update-indication-bit-position=30  # Occupation status based on occupant detection sensor at the 4th row outer left seat.
          signal isBltLockStAtRowThrdMidBltLockEquid: start 43, 1 bit, big-endian, data-type-policy=NETWORK-REPRESENTATION-FROM-COM-SPEC, init-value=1, base-type=CptEquid_2, compu-method=CptEquid_1, category=VALUE, transfer-property=PENDING  # State of belt lock at seating position at middle third row If the belt lock is equipped
          signal isBltLockStAtRowThrdMidBltLockSt1: start 42, 1 bit, big-endian, data-type-policy=NETWORK-REPRESENTATION-FROM-COM-SPEC, init-value=0, base-type=BltLockSt1_2, compu-method=BltLockSt1_1, category=VALUE, transfer-property=PENDING  # State of belt lock at seating position at middle third row Belt lock state, locked/unlocked
          signal isBltLockStAtRowFrthMidBltLockSts: start 33, 1 bit, big-endian, data-type-policy=NETWORK-REPRESENTATION-FROM-COM-SPEC, init-value=1, base-type=DevErrSts2_2, compu-method=DevErrSts2_1, category=VALUE, transfer-property=PENDING  # Belt lock fault status at the 4th row middle seat. Signal gives out if belt lock is faulty or not.
          signal isBltLockStAtRowThrdMidBltLockSts: start 41, 1 bit, big-endian, data-type-policy=NETWORK-REPRESENTATION-FROM-COM-SPEC, init-value=1, base-type=DevErrSts2_2, compu-method=DevErrSts2_1, category=VALUE, transfer-property=PENDING  # State of belt lock at seating position at middle third row Belt lock status, OK/NOK
          signal isBltLockStAtRowFrthMidBltLockEquid: start 35, 1 bit, big-endian, data-type-policy=NETWORK-REPRESENTATION-FROM-COM-SPEC, init-value=1, base-type=CptEquid_2, compu-method=CptEquid_1, category=VALUE, transfer-property=PENDING  # Signal gives out if belt lock detection sensor is equipped at the 4th row middle seat.
          signal isBltLockStAtRowFrthMidBltLockSt1: start 34, 1 bit, big-endian, data-type-policy=NETWORK-REPRESENTATION-FROM-COM-SPEC, init-value=0, base-type=BltLockSt1_2, compu-method=BltLockSt1_1, category=VALUE, transfer-property=PENDING  # Belt lock state at 4th row middle seat posiiton. Signal gives out if the belt lock is locked or unlocked.
          signal isBltLockStAtRowFrthRiBltLockSt1: start 46, 1 bit, big-endian, data-type-policy=NETWORK-REPRESENTATION-FROM-COM-SPEC, init-value=0, base-type=BltLockSt1_2, compu-method=BltLockSt1_1, category=VALUE, transfer-property=PENDING  # Belt lock state at 4th row outer right seat posiiton. Signal gives out if the belt lock is locked or unlocked.
          signal isBltLockStAtPassMidBltLockSt1: start 26, 1 bit, big-endian, data-type-policy=NETWORK-REPRESENTATION-FROM-COM-SPEC, init-value=0, base-type=BltLockSt1_2, compu-method=BltLockSt1_1, category=VALUE, transfer-property=PENDING  # Belt lock state at 1st row middle passenger seat position. Signal gives out if the belt lock is locked or unlocked.
          signal isBltLockStAtRowFrthRiBltLockEquid: start 47, 1 bit, big-endian, data-type-policy=NETWORK-REPRESENTATION-FROM-COM-SPEC, init-value=1, base-type=CptEquid_2, compu-method=CptEquid_1, category=VALUE, transfer-property=PENDING  # Signal gives out if belt lock detection sensor is equipped at the 4th row outer right seat.
          signal isSeatOccptAtRowFrthRi: start 51, 2 bit, big-endian, data-type-policy=NETWORK-REPRESENTATION-FROM-COM-SPEC, init-value=0, base-type=PassSeatSts1_2, compu-method=PassSeatSts1_1, transfer-property=PENDING, update-indication-bit-position=28  # Occupation status based on occupant detection sensor at the 4th row outer right seat.
          signal isBltLockStAtPassMidBltLockEquid: start 27, 1 bit, big-endian, data-type-policy=NETWORK-REPRESENTATION-FROM-COM-SPEC, init-value=1, base-type=CptEquid_2, compu-method=CptEquid_1, category=VALUE, transfer-property=PENDING  # Belt lock state at 1st row middle passenger seat position. Signal gives out if the belt lock sensor is equipped or not.
          signal isBltLockStAtRowFrthLeBltLockSt1: start 38, 1 bit, big-endian, data-type-policy=NETWORK-REPRESENTATION-FROM-COM-SPEC, init-value=0, base-type=BltLockSt1_2, compu-method=BltLockSt1_1, category=VALUE, transfer-property=PENDING  # Belt lock state at 4th row outer left seat posiiton. Signal gives out if the belt lock is locked or unlocked.
          signal isBltLockStAtPassMidBltLockSts: start 25, 1 bit, big-endian, data-type-policy=NETWORK-REPRESENTATION-FROM-COM-SPEC, init-value=1, base-type=DevErrSts2_2, compu-method=DevErrSts2_1, category=VALUE, transfer-property=PENDING  # Belt lock state at 1st row middle passenger seat position. Signal gives out if the belt lock is faulty or not.
          signal isSeatOccptAtRowThrdMid: start 63, 2 bit, big-endian, data-type-policy=NETWORK-REPRESENTATION-FROM-COM-SPEC, init-value=0, base-type=PassSeatSts1_2, compu-method=PassSeatSts1_1, transfer-property=PENDING, update-indication-bit-position=58  # Occupant presence status at 3rd row , right position.
          signal isBltLockStAtRowFrthLeBltLockSts: start 37, 1 bit, big-endian, data-type-policy=NETWORK-REPRESENTATION-FROM-COM-SPEC, init-value=1, base-type=DevErrSts2_2, compu-method=DevErrSts2_1, category=VALUE, transfer-property=PENDING  # Belt lock fault status at the 4th row outer left seat. Signal gives out if belt lock is faulty or not.
          signal isBltLockStAtRowFrthLeBltLockEquid: start 39, 1 bit, big-endian, data-type-policy=NETWORK-REPRESENTATION-FROM-COM-SPEC, init-value=1, base-type=CptEquid_2, compu-method=CptEquid_1, category=VALUE, transfer-property=PENDING  # Signal gives out if belt lock detection sensor is equipped at the 4th row outer left seat.
          mapping igBltLockStAtRowFrthRi_mtx: i-signal-group=igBltLockStAtRowFrthRi, packing-byte-order=big-endian, start-position=47, transfer-property=PENDING, update-indication-bit-position=44
          mapping igBltLockStAtRowFrthLe_mtx: i-signal-group=igBltLockStAtRowFrthLe, packing-byte-order=big-endian, start-position=39, transfer-property=PENDING, update-indication-bit-position=36
          mapping igBltLockStAtPassMid_mtx: i-signal-group=igBltLockStAtPassMid, packing-byte-order=big-endian, start-position=27, transfer-property=PENDING, update-indication-bit-position=24
          mapping igBltLockStAtRowThrdMid_mtx: i-signal-group=igBltLockStAtRowThrdMid, packing-byte-order=big-endian, start-position=43, transfer-property=PENDING, update-indication-bit-position=40
          mapping igBltLockStAtRowFrthMid_mtx: i-signal-group=igBltLockStAtRowFrthMid, packing-byte-order=big-endian, start-position=35, transfer-property=PENDING, update-indication-bit-position=32
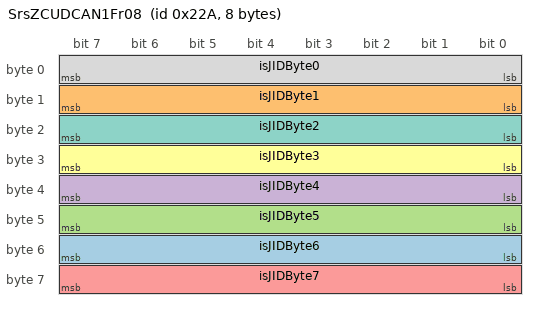
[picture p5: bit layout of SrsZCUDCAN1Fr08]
      frame SrsZCUDCAN1Fr08: id 0x22A, from SRS3, frame-length=8, can-addressing-mode=STANDARD, can-fd-frame-support=false, can-frame-tx-behavior=CAN-20
        pdu SrsZCUDCAN1SignalPdu08: length=8, transmission-mode-condition{data-filter=data-filter-type=ALWAYS, i-signal-in-i-pdu=igJID_mtx}, transmission-mode-true-timing=cyclic-timing={time-offset=0.0, time-period=0.1}, unused-bit-pattern=0
          signal isJIDByte6: start 55, 8 bit, big-endian, data-type-policy=NETWORK-REPRESENTATION-FROM-COM-SPEC, init-value=255, base-type=UInt8_2, compu-method=UInt8_1, category=VALUE, transfer-property=PENDING  # IMU identification number. Byte6
          signal isJIDByte1: start 15, 8 bit, big-endian, data-type-policy=NETWORK-REPRESENTATION-FROM-COM-SPEC, init-value=255, base-type=UInt8_2, compu-method=UInt8_1, category=VALUE, transfer-property=PENDING  # IMU identification number. Byte1
          signal isJIDByte5: start 47, 8 bit, big-endian, data-type-policy=NETWORK-REPRESENTATION-FROM-COM-SPEC, init-value=255, base-type=UInt8_2, compu-method=UInt8_1, category=VALUE, transfer-property=PENDING  # IMU identification number. Byte5
          signal isJIDByte4: start 39, 8 bit, big-endian, data-type-policy=NETWORK-REPRESENTATION-FROM-COM-SPEC, init-value=255, base-type=UInt8_2, compu-method=UInt8_1, category=VALUE, transfer-property=PENDING  # IMU identification number. Byte4
          signal isJIDByte7: start 63, 8 bit, big-endian, data-type-policy=NETWORK-REPRESENTATION-FROM-COM-SPEC, init-value=255, base-type=UInt8_2, compu-method=UInt8_1, category=VALUE, transfer-property=PENDING  # IMU identification number. Byte7
          signal isJIDByte3: start 31, 8 bit, big-endian, data-type-policy=NETWORK-REPRESENTATION-FROM-COM-SPEC, init-value=255, base-type=UInt8_2, compu-method=UInt8_1, category=VALUE, transfer-property=PENDING  # IMU identification number. Byte3
          signal isJIDByte2: start 23, 8 bit, big-endian, data-type-policy=NETWORK-REPRESENTATION-FROM-COM-SPEC, init-value=255, base-type=UInt8_2, compu-method=UInt8_1, category=VALUE, transfer-property=PENDING  # IMU identification number. Byte2
          signal isJIDByte0: start 7, 8 bit, big-endian, data-type-policy=NETWORK-REPRESENTATION-FROM-COM-SPEC, init-value=255, base-type=UInt8_2, compu-method=UInt8_1, category=VALUE, transfer-property=PENDING  # IMU identification number. Byte0
          mapping igJID_mtx: i-signal-group=igJID, packing-byte-order=big-endian, start-position=7, transfer-property=PENDING
      frame SrsZCUDCAN1Fr14: id 0x274, from SRS3, frame-length=8, can-addressing-mode=STANDARD, can-fd-frame-support=false, can-frame-tx-behavior=CAN-20
        pdu SrsZCUDCAN1SignalPdu14: length=8, transmission-mode-condition{data-filter=data-filter-type=ALWAYS, i-signal-in-i-pdu=igSRSResdSig1ToZCUDMSafety_mtx}, transmission-mode-true-timing=cyclic-timing={time-offset=0.0, time-period=0.08}, unused-bit-pattern=0
          signal isSRSResdSig1ToZCUDMSafetyChks: start 39, 8 bit, big-endian, data-type-policy=NETWORK-REPRESENTATION-FROM-COM-SPEC, init-value=0, base-type=UInt8_2, compu-method=UInt8_1, category=VALUE, transfer-property=PENDING
          signal isHVfault: start 42, 1 bit, big-endian, data-type-policy=NETWORK-REPRESENTATION-FROM-COM-SPEC, init-value=0, base-type=Boolean_2, compu-method=Boolean_1, transfer-property=PENDING, update-indication-bit-position=41  # 0: No fault 1: There is one fault qualified at least
          signal isSRSResdSig1ToZCUDMSafetyCntr: start 47, 4 bit, big-endian, data-type-policy=NETWORK-REPRESENTATION-FROM-COM-SPEC, init-value=0, base-type=UInt4_2, compu-method=UInt4_1, category=VALUE, transfer-property=PENDING
          signal isSRSResdSig1ToZCUDMSafetyUInt32: start 7, 32 bit, big-endian, data-type-policy=NETWORK-REPRESENTATION-FROM-COM-SPEC, init-value=0, base-type=UInt32_2, compu-method=UInt32_1, category=VALUE, transfer-property=PENDING
          mapping igSRSResdSig1ToZCUDMSafety_mtx: i-signal-group=igSRSResdSig1ToZCUDMSafety, packing-byte-order=big-endian, start-position=7, transfer-property=PENDING, update-indication-bit-position=43
      frame SrsToZcudZCUDCan1DiagResFr: id 0x639, from SRS3, frame-length=8, can-addressing-mode=STANDARD, can-fd-frame-support=false, can-frame-tx-behavior=CAN-20
        n pdu SrsToZcudZCUDCan1DiagResNpdu: length=8
      frame SrsZCUDCAN1Fr09: id 0x360, from SRS3, frame-length=8, can-addressing-mode=STANDARD, can-fd-frame-support=false, can-frame-tx-behavior=CAN-20
        pdu SrsZCUDCAN1SignalPdu09: length=8, transmission-mode-condition{data-filter=data-filter-type=ALWAYS, i-signal-in-i-pdu=igBltCrashNotif_mtx}, transmission-mode-true-timing=cyclic-timing={time-offset=0.0, time-period=0.35}, unused-bit-pattern=0
          signal isRecOfImpctCrashFrnt: start 16, 1 bit, big-endian, data-type-policy=NETWORK-REPRESENTATION-FROM-COM-SPEC, init-value=0, base-type=Boolean_2, compu-method=Boolean_1, category=BOOLEAN, transfer-property=PENDING  # Crash information, if crash is frontal
          signal isRecOfImpctCrashOffroadD: start 35, 1 bit, big-endian, data-type-policy=NETWORK-REPRESENTATION-FROM-COM-SPEC, init-value=0, base-type=Boolean_2, compu-method=Boolean_1, category=BOOLEAN, transfer-property=PENDING  # Inicdent information, if driving into a ditch has been detected
          signal isRecOfImpctImpctRollAg: start 23, 7 bit, big-endian, data-type-policy=NETWORK-REPRESENTATION-FROM-COM-SPEC, init-value=0, base-type=U8WithRngDeg_1, compu-method=U8WithRngDeg_1, category=VALUE, transfer-property=PENDING  # Crash information, cumulative roll angle
          signal isRecOfImpctVehOri: start 31, 3 bit, big-endian, data-type-policy=NETWORK-REPRESENTATION-FROM-COM-SPEC, init-value=4, base-type=Orntn_2, compu-method=Orntn_1, category=VALUE, transfer-property=PENDING  # Crash information, Vehicle orientation once crash subsides
          signal isRecOfImpctCrashRollovr: start 24, 1 bit, big-endian, data-type-policy=NETWORK-REPRESENTATION-FROM-COM-SPEC, init-value=0, base-type=Boolean_2, compu-method=Boolean_1, category=BOOLEAN, transfer-property=PENDING  # Crash information, if crash is roll-over
          signal isBltCrashNotifDrvr: start 61, 2 bit, big-endian, data-type-policy=NETWORK-REPRESENTATION-FROM-COM-SPEC, init-value=0, base-type=NoYesCrit1_2, compu-method=NoYesCrit1_1, category=VALUE, transfer-property=PENDING  # Status signal for driver belt pyrotechnic activation.
          signal isRecOfImpctCrashOffroadA: start 34, 1 bit, big-endian, data-type-policy=NETWORK-REPRESENTATION-FROM-COM-SPEC, init-value=0, base-type=Boolean_2, compu-method=Boolean_1, category=BOOLEAN, transfer-property=PENDING  # Incident information, if driving off road and becoming airbourne has been detected.
          signal isPedProtnMsgReqForFlt: start 47, 2 bit, big-endian, data-type-policy=NETWORK-REPRESENTATION-FROM-COM-SPEC, init-value=0, base-type=OnOffCrit1_2, compu-method=OnOffCrit1_1, transfer-property=PENDING, update-indication-bit-position=51  # Indication request for pedestrian protection faults.
          signal isRecOfImpctCrashState: start 28, 2 bit, big-endian, data-type-policy=NETWORK-REPRESENTATION-FROM-COM-SPEC, init-value=0, base-type=CrashSt_2, compu-method=CrashSt_1, category=VALUE, transfer-property=PENDING  # Crash information, State of the crash
          signal isPassAirbSts: start 63, 1 bit, big-endian, data-type-policy=NETWORK-REPRESENTATION-FROM-COM-SPEC, init-value=1, base-type=OnOff2_2, compu-method=OnOff2_1, transfer-property=PENDING, update-indication-bit-position=62  # Passenger airbag status, based on PACOS input.
          signal isRecOfImpctCrashRe: start 39, 1 bit, big-endian, data-type-policy=NETWORK-REPRESENTATION-FROM-COM-SPEC, init-value=0, base-type=Boolean_2, compu-method=Boolean_1, category=BOOLEAN, transfer-property=PENDING  # Crash information, if crash is rear
          signal isSafetyCrashFb: start 41, 2 bit, big-endian, data-type-policy=NETWORK-REPRESENTATION-FROM-COM-SPEC, init-value=0, base-type=CrashFb_2, compu-method=CrashFb_1, transfer-property=PENDING, update-indication-bit-position=48  # If brake pedal has been disconnected after a crash it is NOK, else OK after crash.
          signal isRecOfImpctCrashOffroadRT: start 36, 1 bit, big-endian, data-type-policy=NETWORK-REPRESENTATION-FROM-COM-SPEC, init-value=0, base-type=Boolean_2, compu-method=Boolean_1, category=BOOLEAN, transfer-property=PENDING  # Incident information, if driving off the road and into rough terrain has been detected.
          signal isPedProtnMsgReqForImpct: start 53, 1 bit, big-endian, data-type-policy=NETWORK-REPRESENTATION-FROM-COM-SPEC, init-value=0, base-type=OnOff1_2, compu-method=OnOff1_1, transfer-property=PENDING, update-indication-bit-position=52  # Text message request to inform about triggering of the pedestrian protection system.
          signal isRecOfImpctImpctDvx: start 7, 8 bit, big-endian, data-type-policy=NETWORK-REPRESENTATION-FROM-COM-SPEC, init-value=0, base-type=U8Kmph_1, compu-method=U8Kmph_1, category=VALUE, transfer-property=PENDING  # Crash information, change in velocity in x-direction
          signal isBltCrashNotifPass: start 59, 2 bit, big-endian, data-type-policy=NETWORK-REPRESENTATION-FROM-COM-SPEC, init-value=0, base-type=NoYesCrit1_2, compu-method=NoYesCrit1_1, category=VALUE, transfer-property=PENDING  # Status signal for passenger belt pyrotechnic activation.
          signal isRestrntSysMsgReq: start 43, 2 bit, big-endian, data-type-policy=NETWORK-REPRESENTATION-FROM-COM-SPEC, init-value=1, base-type=OnOffCrit1_2, compu-method=OnOffCrit1_1, transfer-property=PENDING, update-indication-bit-position=49  # Text message request for SRS faults.
          signal isRecOfImpctCrashOffroadRTsevere: start 37, 1 bit, big-endian, data-type-policy=NETWORK-REPRESENTATION-FROM-COM-SPEC, init-value=0, base-type=Boolean_2, compu-method=Boolean_1, category=BOOLEAN, transfer-property=PENDING  # Incident information, if driving off road and into severe rough terrain has been detected.
          signal isRecOfImpctCrashSideLe: start 25, 1 bit, big-endian, data-type-policy=NETWORK-REPRESENTATION-FROM-COM-SPEC, init-value=0, base-type=Boolean_2, compu-method=Boolean_1, category=BOOLEAN, transfer-property=PENDING  # Crash information, if crash is left side
          signal isRecOfImpctCrashSideRi: start 26, 1 bit, big-endian, data-type-policy=NETWORK-REPRESENTATION-FROM-COM-SPEC, init-value=0, base-type=Boolean_2, compu-method=Boolean_1, category=BOOLEAN, transfer-property=PENDING  # Crash information, if crash is right side
          signal isRecOfImpctImpctDvy: start 15, 8 bit, big-endian, data-type-policy=NETWORK-REPRESENTATION-FROM-COM-SPEC, init-value=0, base-type=U8Kmph_1, compu-method=U8Kmph_1, category=VALUE, transfer-property=PENDING  # Crash information, change in velocity in y-direction
          signal isRestrntSysLampReq: start 45, 2 bit, big-endian, data-type-policy=NETWORK-REPRESENTATION-FROM-COM-SPEC, init-value=0, base-type=RestrntSysLampReq_2, compu-method=RestrntSysLampReq_1, transfer-property=PENDING, update-indication-bit-position=50  # Indication request for SRS faults.
          signal isRecOfImpctCrashPed: start 38, 1 bit, big-endian, data-type-policy=NETWORK-REPRESENTATION-FROM-COM-SPEC, init-value=0, base-type=Boolean_2, compu-method=Boolean_1, category=BOOLEAN, transfer-property=PENDING  # Incident information, if a pedestrian protection triggering has been made
          mapping igBltCrashNotif_mtx: i-signal-group=igBltCrashNotif, packing-byte-order=big-endian, start-position=61, transfer-property=PENDING, update-indication-bit-position=57
          mapping igRecOfImpct_mtx: i-signal-group=igRecOfImpct, packing-byte-order=big-endian, start-position=7, transfer-property=PENDING, update-indication-bit-position=33
      frame SrsZCUDCAN1Fr15: id 0x230, from SRS3, frame-length=8, can-addressing-mode=STANDARD, can-fd-frame-support=false, can-frame-tx-behavior=CAN-20
        pdu SrsZCUDCAN1SignalIPdu15: length=8, transmission-mode-condition{data-filter=data-filter-type=ALWAYS, i-signal-in-i-pdu=igAgDataCmpQuality_0_mtx}, transmission-mode-true-timing=cyclic-timing={time-offset=0.0, time-period=0.07}, unused-bit-pattern=0
          signal isAgDataCmpQualityYawRateCmpQuality_0: start 23, 8 bit, big-endian, data-type-policy=NETWORK-REPRESENTATION-FROM-COM-SPEC, init-value=0, base-type=UInt8_2, compu-method=UInt8_1, category=VALUE, transfer-property=PENDING  # Quality of offset compensation for yawrate
          signal isAgDataCmpQualityRollRateCmpQuality_0: start 15, 8 bit, big-endian, data-type-policy=NETWORK-REPRESENTATION-FROM-COM-SPEC, init-value=0, base-type=UInt8_2, compu-method=UInt8_1, category=VALUE, transfer-property=PENDING  # Quality of offset compensation for rollrate
          signal isAgDataCmpQualityPitchRateCmpQuality_0: start 7, 8 bit, big-endian, data-type-policy=NETWORK-REPRESENTATION-FROM-COM-SPEC, init-value=0, base-type=UInt8_2, compu-method=UInt8_1, category=VALUE, transfer-property=PENDING  # Quality of offset compensation for pitchrate
          mapping igAgDataCmpQuality_0_mtx: i-signal-group=igAgDataCmpQuality_0, packing-byte-order=big-endian, start-position=7, transfer-property=PENDING, update-indication-bit-position=31
      frame SrsToZcudISO26021ZCUCAN1DiagResFrame11: id 0x7F9, from SRS3, frame-length=8, can-addressing-mode=STANDARD, can-fd-frame-support=false, can-frame-tx-behavior=CAN-20
        n pdu SrsToZcudISO26021ZCUDCan1ResNpdu11: length=8
      frame SrsZCUDCAN1Fr12: id 0x148, from SRS3, frame-length=8, can-addressing-mode=STANDARD, can-fd-frame-support=false, can-frame-tx-behavior=CAN-20
        pdu SrsZCUDCAN1SignalPdu12: length=8, transmission-mode-condition{data-filter=data-filter-type=ALWAYS, i-signal-in-i-pdu=igRecOfImpct2_mtx}, transmission-mode-true-timing=cyclic-timing={time-offset=0.0, time-period=0.03}, unused-bit-pattern=0
          signal isRecOfPostImpctBrkgCfmdCrashOffroadRT: start 33, 2 bit, big-endian, data-type-policy=NETWORK-REPRESENTATION-FROM-COM-SPEC, init-value=1, base-type=PostImpctBrkgNoYes_2, compu-method=PostImpctBrkgNoYes_1, category=VALUE, transfer-property=PENDING  # Rough Terrain
          signal isRecOfPostImpctBrkgCfmdCrashLargeAnimal: start 39, 2 bit, big-endian, data-type-policy=NETWORK-REPRESENTATION-FROM-COM-SPEC, init-value=1, base-type=PostImpctBrkgNoYes_2, compu-method=PostImpctBrkgNoYes_1, category=VALUE, transfer-property=PENDING  # Large Animal
          signal isRecOfPostImpctBrkgCfmdCrashRollovr: start 55, 2 bit, big-endian, data-type-policy=NETWORK-REPRESENTATION-FROM-COM-SPEC, init-value=1, base-type=PostImpctBrkgNoYes_2, compu-method=PostImpctBrkgNoYes_1, category=VALUE, transfer-property=PENDING  # Crash type = rollover
          signal isRecOfPostImpctBrkgCfmdCrashSideRi: start 51, 2 bit, big-endian, data-type-policy=NETWORK-REPRESENTATION-FROM-COM-SPEC, init-value=1, base-type=PostImpctBrkgNoYes_2, compu-method=PostImpctBrkgNoYes_1, category=VALUE, transfer-property=PENDING  # Crash type = right side.
          signal isRecOfPostImpctBrkgCfmdCrashRe: start 41, 2 bit, big-endian, data-type-policy=NETWORK-REPRESENTATION-FROM-COM-SPEC, init-value=1, base-type=PostImpctBrkgNoYes_2, compu-method=PostImpctBrkgNoYes_1, category=VALUE, transfer-property=PENDING  # Crash type = rear
          signal isRecOfImpct2ImpctDvySigned: start 14, 9 bit, big-endian, data-type-policy=NETWORK-REPRESENTATION-FROM-COM-SPEC, init-value=255, base-type=Spd51_1, compu-method=Spd51_1, category=VALUE, transfer-property=PENDING  # Crash information , changed velocity in y direction, data with sign
          signal isRecOfPostImpctBrkgCfmdPostImpctBrkgCfmd: start 49, 2 bit, big-endian, data-type-policy=NETWORK-REPRESENTATION-FROM-COM-SPEC, init-value=1, base-type=PostImpctBrkgNoYes_2, compu-method=PostImpctBrkgNoYes_1, category=VALUE, transfer-property=PENDING  # ASIL-B(D) signal to inform that a crash has occurred.
          signal isRecOfPostImpctBrkgCfmdCrashOffroadD: start 35, 2 bit, big-endian, data-type-policy=NETWORK-REPRESENTATION-FROM-COM-SPEC, init-value=1, base-type=PostImpctBrkgNoYes_2, compu-method=PostImpctBrkgNoYes_1, category=VALUE, transfer-property=PENDING  # Ditch
          signal isRecOfPostImpctBrkgCfmdCrashFrnt: start 25, 2 bit, big-endian, data-type-policy=NETWORK-REPRESENTATION-FROM-COM-SPEC, init-value=1, base-type=PostImpctBrkgNoYes_2, compu-method=PostImpctBrkgNoYes_1, category=VALUE, transfer-property=PENDING  # Crash type = front.
          signal isRecOfPostImpctBrkgCfmdChks: start 63, 8 bit, big-endian, data-type-policy=NETWORK-REPRESENTATION-FROM-COM-SPEC, init-value=255, base-type=UInt8_2, compu-method=UInt8_1, category=VALUE, transfer-property=PENDING  # E2E checksum
          signal isRecOfPostImpctBrkgCfmdCrashPed: start 43, 2 bit, big-endian, data-type-policy=NETWORK-REPRESENTATION-FROM-COM-SPEC, init-value=1, base-type=PostImpctBrkgNoYes_2, compu-method=PostImpctBrkgNoYes_1, category=VALUE, transfer-property=PENDING  # Crash type = pedestrian impact
          signal isRecOfPostImpctBrkgCfmdCrashOffroadA: start 37, 2 bit, big-endian, data-type-policy=NETWORK-REPRESENTATION-FROM-COM-SPEC, init-value=1, base-type=PostImpctBrkgNoYes_2, compu-method=PostImpctBrkgNoYes_1, category=VALUE, transfer-property=PENDING  # Airbourne
          signal isRecOfPostImpctBrkgCfmdCntr: start 29, 4 bit, big-endian, data-type-policy=NETWORK-REPRESENTATION-FROM-COM-SPEC, init-value=0, base-type=UInt4_2, compu-method=UInt4_1, category=VALUE, transfer-property=PENDING  # E2E counter
          signal isRecOfPostImpctBrkgCfmdCrashOz: start 45, 2 bit, big-endian, data-type-policy=NETWORK-REPRESENTATION-FROM-COM-SPEC, init-value=1, base-type=PostImpctBrkgNoYes_2, compu-method=PostImpctBrkgNoYes_1, category=VALUE, transfer-property=PENDING  # Crash type = side offzone (i.e. behind C-pillar or in front of A-pillar.)
          signal isRecOfPostImpctBrkgCfmdCrashOffroadRTsevere: start 47, 2 bit, big-endian, data-type-policy=NETWORK-REPRESENTATION-FROM-COM-SPEC, init-value=1, base-type=PostImpctBrkgNoYes_2, compu-method=PostImpctBrkgNoYes_1, category=VALUE, transfer-property=PENDING  # Rough Terrain, severe
          signal isRecOfPostImpctBrkgCfmdCrashSideLe: start 53, 2 bit, big-endian, data-type-policy=NETWORK-REPRESENTATION-FROM-COM-SPEC, init-value=1, base-type=PostImpctBrkgNoYes_2, compu-method=PostImpctBrkgNoYes_1, category=VALUE, transfer-property=PENDING  # Crash type = left side.
          signal isRecOfImpct2ImpctDvxSigned: start 7, 9 bit, big-endian, data-type-policy=NETWORK-REPRESENTATION-FROM-COM-SPEC, init-value=255, base-type=Spd51_1, compu-method=Spd51_1, category=VALUE, transfer-property=PENDING  # Crash information , changed velocity in x direction , data with sign
          mapping igRecOfImpct2_mtx: i-signal-group=igRecOfImpct2, packing-byte-order=big-endian, start-position=7, transfer-property=PENDING, update-indication-bit-position=21
          mapping igRecOfPostImpctBrkgCfmd_mtx: i-signal-group=igRecOfPostImpctBrkgCfmd, packing-byte-order=big-endian, start-position=29, transfer-property=PENDING, update-indication-bit-position=30
      frame SrsZCUDCAN1Fr10: id 0x70, from SRS3, frame-length=8, can-addressing-mode=STANDARD, can-fd-frame-support=false, can-frame-tx-behavior=CAN-20
        pdu SrsZCUDCAN1SignalPdu10: length=8, transmission-mode-condition{data-filter=data-filter-type=ALWAYS, i-signal-in-i-pdu=igBltLockStAtRowSecLe_mtx}, transmission-mode-true-timing=cyclic-timing={time-offset=0.0, time-period=0.02}, unused-bit-pattern=0
          signal isBltLockStAtRowSecMidBltLockSt1: start 2, 1 bit, big-endian, data-type-policy=NETWORK-REPRESENTATION-FROM-COM-SPEC, init-value=0, base-type=BltLockSt1_2, compu-method=BltLockSt1_1, category=VALUE, transfer-property=PENDING  # State of belt lock at seating position at middle of second row Belt lock state, locked/unlocked
          signal isBltLockStAtRowThrdLeBltLockSts: start 9, 1 bit, big-endian, data-type-policy=NETWORK-REPRESENTATION-FROM-COM-SPEC, init-value=1, base-type=DevErrSts2_2, compu-method=DevErrSts2_1, category=VALUE, transfer-property=PENDING  # State of belt lock at seating position at left of third row Belt lock status, OK/NOK
          signal isBltLockStAtRowThrdLeBltLockEquid: start 11, 1 bit, big-endian, data-type-policy=NETWORK-REPRESENTATION-FROM-COM-SPEC, init-value=1, base-type=CptEquid_2, compu-method=CptEquid_1, category=VALUE, transfer-property=PENDING  # State of belt lock at seating position at left of third row If the belt lock is equipped
          signal isBltLockStAtRowSecLeBltLockEquid: start 7, 1 bit, big-endian, data-type-policy=NETWORK-REPRESENTATION-FROM-COM-SPEC, init-value=1, base-type=CptEquid_2, compu-method=CptEquid_1, category=VALUE, transfer-property=PENDING  # State of belt lock at seating position at left of second row If the belt lock is equipped
          signal isBltLockStAtRowThrdRiBltLockSt1: start 22, 1 bit, big-endian, data-type-policy=NETWORK-REPRESENTATION-FROM-COM-SPEC, init-value=0, base-type=BltLockSt1_2, compu-method=BltLockSt1_1, category=VALUE, transfer-property=PENDING  # State of belt lock at seating position at right of third row Belt lock state, locked/unlocked
          signal isBltLockStAtRowThrdRiBltLockSts: start 21, 1 bit, big-endian, data-type-policy=NETWORK-REPRESENTATION-FROM-COM-SPEC, init-value=1, base-type=DevErrSts2_2, compu-method=DevErrSts2_1, category=VALUE, transfer-property=PENDING  # State of belt lock at seating position at right of third row Belt lock status, OK/NOK
          signal isBltLockStAtRowSecRiBltLockEquid: start 15, 1 bit, big-endian, data-type-policy=NETWORK-REPRESENTATION-FROM-COM-SPEC, init-value=1, base-type=CptEquid_2, compu-method=CptEquid_1, category=VALUE, transfer-property=PENDING  # State of belt lock at seating position at right of second row If the belt lock is equipped
          signal isBltLockStAtRowSecLeBltLockSts: start 5, 1 bit, big-endian, data-type-policy=NETWORK-REPRESENTATION-FROM-COM-SPEC, init-value=1, base-type=DevErrSts2_2, compu-method=DevErrSts2_1, category=VALUE, transfer-property=PENDING  # State of belt lock at seating position at left of second row Belt lock status, OK/NOK
          signal isBltLockStAtRowSecLeBltLockSt1: start 6, 1 bit, big-endian, data-type-policy=NETWORK-REPRESENTATION-FROM-COM-SPEC, init-value=0, base-type=BltLockSt1_2, compu-method=BltLockSt1_1, category=VALUE, transfer-property=PENDING  # State of belt lock at seating position at left of second row Belt lock state, locked/unlocked
          signal isBltLockStAtRowThrdRiBltLockEquid: start 23, 1 bit, big-endian, data-type-policy=NETWORK-REPRESENTATION-FROM-COM-SPEC, init-value=1, base-type=CptEquid_2, compu-method=CptEquid_1, category=VALUE, transfer-property=PENDING  # State of belt lock at seating position at right of third row If the belt lock is equipped
          signal isBltLockStAtRowSecMidBltLockEquid: start 3, 1 bit, big-endian, data-type-policy=NETWORK-REPRESENTATION-FROM-COM-SPEC, init-value=1, base-type=CptEquid_2, compu-method=CptEquid_1, category=VALUE, transfer-property=PENDING  # State of belt lock at seating position at middle of second row If the belt lock is equipped
          signal isRecOfPostImpctBrkgSuspcSuspcPostImpctBrkg: start 43, 2 bit, big-endian, data-type-policy=NETWORK-REPRESENTATION-FROM-COM-SPEC, init-value=1, base-type=PostImpctBrkgNoYes_2, compu-method=PostImpctBrkgNoYes_1, category=VALUE, transfer-property=PENDING  # ASIL-B(D) signal to inform that a crash has occurred.
          signal isBltLockStAtRowSecRiBltLockSts: start 13, 1 bit, big-endian, data-type-policy=NETWORK-REPRESENTATION-FROM-COM-SPEC, init-value=1, base-type=DevErrSts2_2, compu-method=DevErrSts2_1, category=VALUE, transfer-property=PENDING  # State of belt lock at seating position at right of second row Belt lock status, OK/NOK
          signal isBltLockStAtRowSecMidBltLockSts: start 1, 1 bit, big-endian, data-type-policy=NETWORK-REPRESENTATION-FROM-COM-SPEC, init-value=1, base-type=DevErrSts2_2, compu-method=DevErrSts2_1, category=VALUE, transfer-property=PENDING  # State of belt lock at seating position at middle of second row Belt lock status, OK/NOK
          signal isBltLockStAtRowThrdLeBltLockSt1: start 10, 1 bit, big-endian, data-type-policy=NETWORK-REPRESENTATION-FROM-COM-SPEC, init-value=0, base-type=BltLockSt1_2, compu-method=BltLockSt1_1, category=VALUE, transfer-property=PENDING  # State of belt lock at seating position at left of third row Belt lock state, locked/unlocked
          signal isRecOfPostImpctBrkgSuspcCntr: start 47, 4 bit, big-endian, data-type-policy=NETWORK-REPRESENTATION-FROM-COM-SPEC, init-value=0, base-type=UInt4_2, compu-method=UInt4_1, category=VALUE, transfer-property=PENDING  # Signal counter
          signal isRecOfPostImpctBrkgSuspcChks: start 39, 8 bit, big-endian, data-type-policy=NETWORK-REPRESENTATION-FROM-COM-SPEC, init-value=255, base-type=UInt8_2, compu-method=UInt8_1, category=VALUE, transfer-property=PENDING  # Signal checksum
          signal isBltLockStAtRowSecRiBltLockSt1: start 14, 1 bit, big-endian, data-type-policy=NETWORK-REPRESENTATION-FROM-COM-SPEC, init-value=0, base-type=BltLockSt1_2, compu-method=BltLockSt1_1, category=VALUE, transfer-property=PENDING  # State of belt lock at seating position at right of second row Belt lock state, locked/unlocked
          mapping igBltLockStAtRowThrdRi_mtx: i-signal-group=igBltLockStAtRowThrdRi, packing-byte-order=big-endian, start-position=23, transfer-property=PENDING, update-indication-bit-position=20
          mapping igBltLockStAtRowSecMid_mtx: i-signal-group=igBltLockStAtRowSecMid, packing-byte-order=big-endian, start-position=3, transfer-property=PENDING, update-indication-bit-position=0
          mapping igRecOfPostImpctBrkgSuspc_mtx: i-signal-group=igRecOfPostImpctBrkgSuspc, packing-byte-order=big-endian, start-position=39, transfer-property=PENDING, update-indication-bit-position=41
          mapping igBltLockStAtRowSecLe_mtx: i-signal-group=igBltLockStAtRowSecLe, packing-byte-order=big-endian, start-position=7, transfer-property=PENDING, update-indication-bit-position=4
          mapping igBltLockStAtRowThrdLe_mtx: i-signal-group=igBltLockStAtRowThrdLe, packing-byte-order=big-endian, start-position=11, transfer-property=PENDING, update-indication-bit-position=8
          mapping igBltLockStAtRowSecRi_mtx: i-signal-group=igBltLockStAtRowSecRi, packing-byte-order=big-endian, start-position=15, transfer-property=PENDING, update-indication-bit-position=12
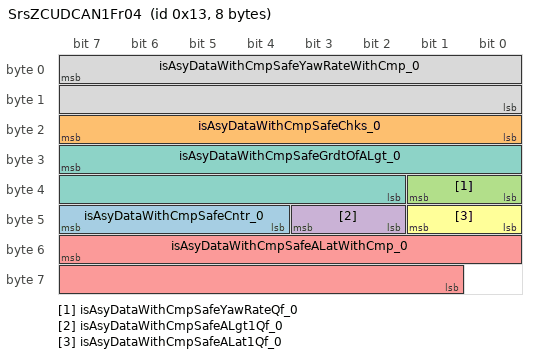
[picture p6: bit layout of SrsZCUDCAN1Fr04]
      frame SrsZCUDCAN1Fr04: id 0x13, from SRS3, frame-length=8, can-addressing-mode=STANDARD, can-fd-frame-support=false, can-frame-tx-behavior=CAN-20
        pdu SrsZCUDCAN1SignalPdu04: length=8, transmission-mode-condition{data-filter=data-filter-type=ALWAYS, i-signal-in-i-pdu=igAsyDataWithCmpSafe_0_mtx}, transmission-mode-true-timing=cyclic-timing={time-offset=0.0, time-period=0.01}, unused-bit-pattern=0
          signal isAsyDataWithCmpSafeCntr_0: start 47, 4 bit, big-endian, data-type-policy=NETWORK-REPRESENTATION-FROM-COM-SPEC, init-value=0, base-type=UInt4_2, compu-method=UInt4_1, category=VALUE, transfer-property=PENDING  # IMU processed special data. Counter
          signal isAsyDataWithCmpSafeChks_0: start 23, 8 bit, big-endian, data-type-policy=NETWORK-REPRESENTATION-FROM-COM-SPEC, init-value=255, base-type=UInt8_2, compu-method=UInt8_1, category=VALUE, transfer-property=PENDING  # IMU processed special data. Check sum
          signal isAsyDataWithCmpSafeYawRateQf_0: start 33, 2 bit, big-endian, data-type-policy=NETWORK-REPRESENTATION-FROM-COM-SPEC, init-value=1, base-type=Qf1_2, compu-method=Qf1_1, category=VALUE, transfer-property=PENDING  # IMU processed special data. Quality Factor for Yaw Rate
          signal isAsyDataWithCmpSafeALgt1Qf_0: start 43, 2 bit, big-endian, data-type-policy=NETWORK-REPRESENTATION-FROM-COM-SPEC, init-value=1, base-type=Qf1_2, compu-method=Qf1_1, category=VALUE, transfer-property=PENDING  # IMU processed special data. Quality factor for Longitudinal acceleration
          signal isAsyDataWithCmpSafeALatWithCmp_0: start 55, 15 bit, big-endian, data-type-policy=NETWORK-REPRESENTATION-FROM-COM-SPEC, init-value=0, base-type=A38_2, compu-method=A38_1, category=VALUE, transfer-property=PENDING  # IMU processed special data. Compensated Lateral acceleration
          signal isAsyDataWithCmpSafeALat1Qf_0: start 41, 2 bit, big-endian, data-type-policy=NETWORK-REPRESENTATION-FROM-COM-SPEC, init-value=1, base-type=Qf1_2, compu-method=Qf1_1, category=VALUE, transfer-property=PENDING  # IMU processed special data. Quality factor for Lateral acceleration signal
          signal isAsyDataWithCmpSafeGrdtOfALgt_0: start 31, 14 bit, big-endian, data-type-policy=NETWORK-REPRESENTATION-FROM-COM-SPEC, init-value=0, base-type=Jerk1_2, compu-method=Jerk1_1, category=VALUE, transfer-property=PENDING  # IMU processed special data. Derivative of Longitudinal acceleration
          signal isAsyDataWithCmpSafeYawRateWithCmp_0: start 7, 16 bit, big-endian, data-type-policy=NETWORK-REPRESENTATION-FROM-COM-SPEC, init-value=0, base-type=AgSpd34_2, compu-method=AgSpd34_1, category=VALUE, transfer-property=PENDING  # IMU processed special data. Compensated Yaw rate
          mapping igAsyDataWithCmpSafe_0_mtx: i-signal-group=igAsyDataWithCmpSafe_0, packing-byte-order=big-endian, start-position=7, transfer-property=PENDING, update-indication-bit-position=56
      frame SrsZCUDCAN1Fr02: id 0x10, from SRS3, frame-length=4, can-addressing-mode=STANDARD, can-fd-frame-support=false, can-frame-tx-behavior=CAN-20
        pdu SrsZCUDCAN1SignalPdu02: length=4, minimum-delay=0.01, transmission-mode-condition{data-filter=data-filter-type=ALWAYS, i-signal-in-i-pdu=igCrashStsSafe_0_mtx}, transmission-mode-true-timing={cyclic-timing={time-offset=0.0, time-period=0.2}, event-controlled-timing=number-of-repetitions=0}, unused-bit-pattern=0
          signal isPassAirbStsChgNotifReq: start 7, 1 bit, big-endian, data-type-policy=NETWORK-REPRESENTATION-FROM-COM-SPEC, init-value=0, base-type=ReqForDisp_2, compu-method=ReqForDisp_1, transfer-property=PENDING, update-indication-bit-position=6  # Request for a popup window notification to promot user to change the passenger airbag status.
          signal isCrashStsSafeCntr_0: start 3, 4 bit, big-endian, data-type-policy=NETWORK-REPRESENTATION-FROM-COM-SPEC, init-value=0, base-type=UInt4_2, compu-method=UInt4_1, category=VALUE, transfer-property=TRIGGERED  # Counter for E2E
          signal isCrashStsSafeSts_0: start 4, 1 bit, big-endian, data-type-policy=NETWORK-REPRESENTATION-FROM-COM-SPEC, init-value=0, base-type=CrashSts2_2, compu-method=CrashSts2_2, category=VALUE, transfer-property=TRIGGERED  # Information if a crash has been detected by SRS.
          signal isCrashStsSafeChks_0: start 15, 8 bit, big-endian, data-type-policy=NETWORK-REPRESENTATION-FROM-COM-SPEC, init-value=255, base-type=UInt8_2, compu-method=UInt8_1, category=VALUE, transfer-property=TRIGGERED  # Checksum for E2E
          mapping igCrashStsSafe_0_mtx: i-signal-group=igCrashStsSafe_0, packing-byte-order=big-endian, start-position=4, transfer-property=TRIGGERED, update-indication-bit-position=5
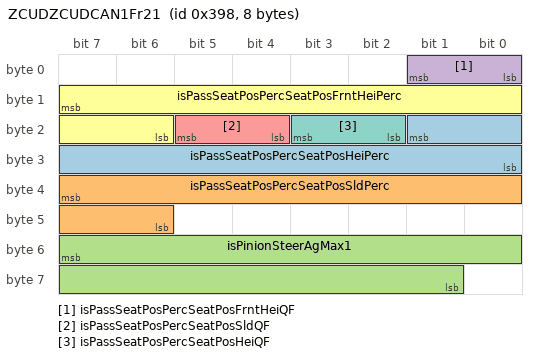
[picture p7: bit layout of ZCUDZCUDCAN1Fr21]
      frame ZCUDZCUDCAN1Fr21: id 0x398, to SRS3, frame-length=8, can-addressing-mode=STANDARD, can-fd-frame-support=false, can-frame-rx-behavior=CAN-20
        pdu ZCUDZCUDCAN1SignalIPDU21: length=8, unused-bit-pattern=0
          signal isPassSeatPosPercSeatPosHeiPerc: start 17, 10 bit, big-endian, data-type-policy=NETWORK-REPRESENTATION-FROM-COM-SPEC, init-value=1000, base-type=Perc9_2, compu-method=Perc9_1, category=VALUE, to SRS3  # Height Position Percentage
          signal isPassSeatPosPercSeatPosSldPerc: start 39, 10 bit, big-endian, data-type-policy=NETWORK-REPRESENTATION-FROM-COM-SPEC, init-value=1000, base-type=Perc9_2, compu-method=Perc9_1, category=VALUE, to SRS3  # Length Position Percentage
          signal isPinionSteerAgMax1: start 55, 15 bit, big-endian, data-type-policy=NETWORK-REPRESENTATION-FROM-COM-SPEC, init-value=0, base-type=Ag4_2, compu-method=Ag4_1, update-indication-bit-position=56, to SRS3  # PinionSteerAgMax1 contains the current maximal pinion angle. Depends on tire size and vehicle type.
          signal isPassSeatPosPercSeatPosFrntHeiQF: start 1, 2 bit, big-endian, data-type-policy=NETWORK-REPRESENTATION-FROM-COM-SPEC, init-value=1, base-type=Qf1_2, compu-method=Qf1_1, category=VALUE, to SRS3  # Front Height Position Quality Factor
          signal isPassSeatPosPercSeatPosSldQF: start 21, 2 bit, big-endian, data-type-policy=NETWORK-REPRESENTATION-FROM-COM-SPEC, init-value=1, base-type=Qf1_2, compu-method=Qf1_1, category=VALUE, to SRS3  # Length Position Quality Factor
          signal isPassSeatPosPercSeatPosFrntHeiPerc: start 15, 10 bit, big-endian, data-type-policy=NETWORK-REPRESENTATION-FROM-COM-SPEC, init-value=1000, base-type=Perc9_2, compu-method=Perc9_1, category=VALUE, to SRS3  # Front Height Position Percentage
          signal isPassSeatPosPercSeatPosHeiQF: start 19, 2 bit, big-endian, data-type-policy=NETWORK-REPRESENTATION-FROM-COM-SPEC, init-value=1, base-type=Qf1_2, compu-method=Qf1_1, category=VALUE, to SRS3  # Height Position Quality Factor
          mapping igPassSeatPosPerc_mrx: i-signal-group=igPassSeatPosPerc, packing-byte-order=big-endian, start-position=1, update-indication-bit-position=2
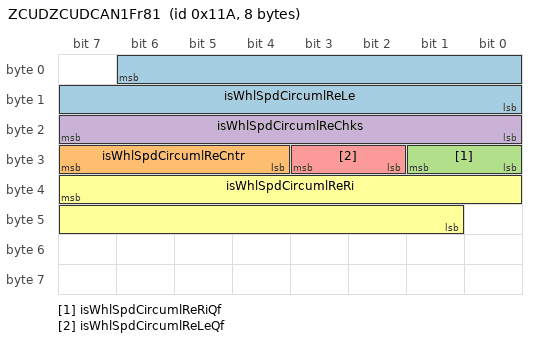
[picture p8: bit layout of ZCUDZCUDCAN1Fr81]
      frame ZCUDZCUDCAN1Fr81: id 0x11A, to SRS3, frame-length=8, can-addressing-mode=STANDARD, can-fd-frame-support=false, can-frame-rx-behavior=CAN-20
        pdu ZCUDZCUDCAN1SignalIPdu81: length=8, unused-bit-pattern=0
          signal isWhlSpdCircumlReLe: start 6, 15 bit, big-endian, data-type-policy=NETWORK-REPRESENTATION-FROM-COM-SPEC, init-value=0, base-type=Spd1_2, compu-method=Spd1_1, category=VALUE, to SRS3  # Individual wheel speed from rear wheel speed sensors. Wheel speed from rear left wheel speed sensor using nominal value of wheel radius.
          signal isWhlSpdCircumlReCntr: start 31, 4 bit, big-endian, data-type-policy=NETWORK-REPRESENTATION-FROM-COM-SPEC, init-value=0, base-type=UInt4_2, compu-method=UInt4_1, category=VALUE, to SRS3  # Individual wheel speed from rear wheel speed sensors. Counter
          signal isWhlSpdCircumlReRiQf: start 25, 2 bit, big-endian, data-type-policy=NETWORK-REPRESENTATION-FROM-COM-SPEC, init-value=1, base-type=GenQf1_2, compu-method=GenQf1_1, category=VALUE, to SRS3  # Individual wheel speed from rear wheel speed sensors. Qf for wheel speed sensor
          signal isWhlSpdCircumlReChks: start 23, 8 bit, big-endian, data-type-policy=NETWORK-REPRESENTATION-FROM-COM-SPEC, init-value=0, base-type=UInt8_2, compu-method=UInt8_1, category=VALUE, to SRS3  # Individual wheel speed from rear wheel speed sensors. Checksum
          signal isWhlSpdCircumlReLeQf: start 27, 2 bit, big-endian, data-type-policy=NETWORK-REPRESENTATION-FROM-COM-SPEC, init-value=1, base-type=GenQf1_2, compu-method=GenQf1_1, category=VALUE, to SRS3  # Individual wheel speed from rear wheel speed sensors. Qf for wheel speed sensor
          signal isWhlSpdCircumlReRi: start 39, 15 bit, big-endian, data-type-policy=NETWORK-REPRESENTATION-FROM-COM-SPEC, init-value=0, base-type=Spd1_2, compu-method=Spd1_1, category=VALUE, to SRS3  # Individual wheel speed from rear wheel speed sensors. Wheel speed from rear right wheel speed sensor using nominal value of wheel radius.
          mapping igWhlSpdCircumlRe_mrx: i-signal-group=igWhlSpdCircumlRe, packing-byte-order=big-endian, start-position=6, update-indication-bit-position=7
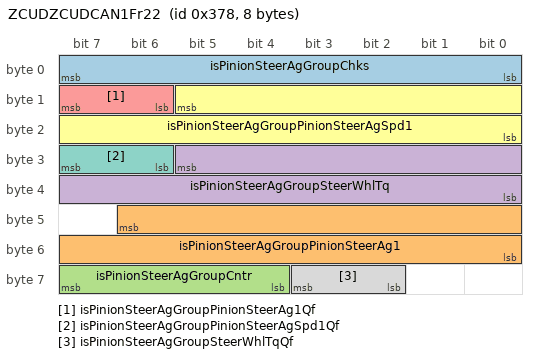
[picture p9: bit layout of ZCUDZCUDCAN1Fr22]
      frame ZCUDZCUDCAN1Fr22: id 0x378, to SRS3, frame-length=8, can-addressing-mode=STANDARD, can-fd-frame-support=false, can-frame-rx-behavior=CAN-20
        pdu ZCUDZCUDCAN1SignalIPDU22: length=8, unused-bit-pattern=0
          signal isPinionSteerAgGroupChks: start 7, 8 bit, big-endian, data-type-policy=NETWORK-REPRESENTATION-FROM-COM-SPEC, init-value=0, base-type=UInt8_2, compu-method=UInt8_1, category=VALUE, to SRS3  # Checksum for PinionSteerAgGroup
          signal isPinionSteerAgGroupPinionSteerAg1: start 46, 15 bit, big-endian, data-type-policy=NETWORK-REPRESENTATION-FROM-COM-SPEC, init-value=0, base-type=Ag4_2, compu-method=Ag4_1, category=VALUE, to SRS3  # Calculated pinion steer angle at the front steering device
          signal isPinionSteerAgGroupCntr: start 63, 4 bit, big-endian, data-type-policy=NETWORK-REPRESENTATION-FROM-COM-SPEC, init-value=0, base-type=UInt4_2, compu-method=UInt4_1, category=VALUE, to SRS3  # Counter for PinionSteerAgGroup
          signal isPinionSteerAgGroupSteerWhlTq: start 29, 14 bit, big-endian, data-type-policy=NETWORK-REPRESENTATION-FROM-COM-SPEC, init-value=0, base-type=Tq1_2, compu-method=Tq1_1, category=VALUE, to SRS3  # Torque on steering wheel
          signal isPinionSteerAgGroupPinionSteerAg1Qf: start 15, 2 bit, big-endian, data-type-policy=NETWORK-REPRESENTATION-FROM-COM-SPEC, init-value=1, base-type=GenQf1_2, compu-method=GenQf1_1, category=VALUE, to SRS3  # Quality factor for PinionSteerAg1
          signal isPinionSteerAgGroupPinionSteerAgSpd1: start 13, 14 bit, big-endian, data-type-policy=NETWORK-REPRESENTATION-FROM-COM-SPEC, init-value=0, base-type=AgSpd1_2, compu-method=AgSpd1_1, category=VALUE, to SRS3  # Calculated pinion steer angle speed at the front steering device
          signal isPinionSteerAgGroupPinionSteerAgSpd1Qf: start 31, 2 bit, big-endian, data-type-policy=NETWORK-REPRESENTATION-FROM-COM-SPEC, init-value=1, base-type=GenQf1_2, compu-method=GenQf1_1, category=VALUE, to SRS3  # Quality factor for PinionSteerAgSpd1
          signal isPinionSteerAgGroupSteerWhlTqQf: start 59, 2 bit, big-endian, data-type-policy=NETWORK-REPRESENTATION-FROM-COM-SPEC, init-value=1, base-type=GenQf1_2, compu-method=GenQf1_1, category=VALUE, to SRS3  # Quality factor for SteerWhlTq
          mapping igPinionSteerAgGroup_mrx: i-signal-group=igPinionSteerAgGroup, packing-byte-order=big-endian, start-position=7, update-indication-bit-position=57
      frame ZCUDZCUDCAN1Fr60: id 0x5B, to SRS3, frame-length=8, can-addressing-mode=STANDARD, can-fd-frame-support=false, can-frame-rx-behavior=CAN-20
        pdu ZCUDZCUDCAN1SignalIPDU60: length=8, unused-bit-pattern=0
          signal isWhlDirRotlReRi: start 57, 2 bit, big-endian, data-type-policy=NETWORK-REPRESENTATION-FROM-COM-SPEC, init-value=0, base-type=WhlRotlDirStd1_2, compu-method=WhlRotlDirStd1_1, category=VALUE, to SRS3  # Rotational direction for the rear individual wheels. Wheel rotation direction of rear right wheel.
          signal isWhlDirRotlReCntr: start 63, 4 bit, big-endian, data-type-policy=NETWORK-REPRESENTATION-FROM-COM-SPEC, init-value=0, base-type=UInt4_2, compu-method=UInt4_1, category=VALUE, to SRS3  # counter
          signal isWhlDirRotlReLe: start 59, 2 bit, big-endian, data-type-policy=NETWORK-REPRESENTATION-FROM-COM-SPEC, init-value=0, base-type=WhlRotlDirStd1_2, compu-method=WhlRotlDirStd1_1, category=VALUE, to SRS3  # Rotational direction for the rear individual wheels. Wheel rotation direction of rear left wheel.
          signal isWhlDirRotlReChks: start 55, 8 bit, big-endian, data-type-policy=NETWORK-REPRESENTATION-FROM-COM-SPEC, init-value=0, base-type=UInt8_2, compu-method=UInt8_1, category=VALUE, to SRS3  # checksum
          mapping igWhlDirRotlRe_mrx: i-signal-group=igWhlDirRotlRe, packing-byte-order=big-endian, start-position=55, update-indication-bit-position=43
      frame ZCUDZCUDCAN1Fr57: id 0x264, to SRS3, frame-length=8, can-addressing-mode=STANDARD, can-fd-frame-support=false, can-frame-rx-behavior=CAN-20
        pdu ZCUDZCUDCAN1SignalIPDU57: length=8, unused-bit-pattern=0
          signal isDrvrStuMonSts: start 20, 4 bit, big-endian, data-type-policy=NETWORK-REPRESENTATION-FROM-COM-SPEC, init-value=0, base-type=UInt4_2, compu-method=UInt4_1, update-indication-bit-position=16, to SRS3  # Driver's body position detection
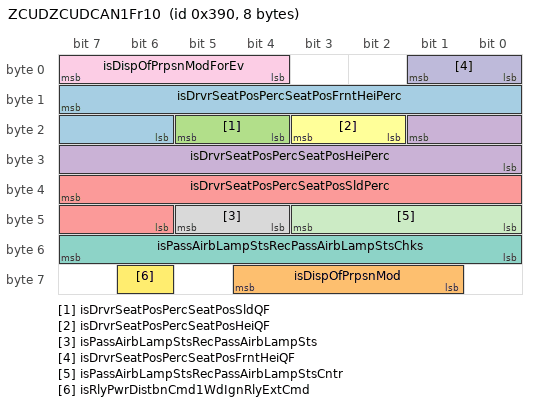
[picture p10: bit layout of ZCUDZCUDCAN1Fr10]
      frame ZCUDZCUDCAN1Fr10: id 0x390, to SRS3, frame-length=8, can-addressing-mode=STANDARD, can-fd-frame-support=false, can-frame-rx-behavior=CAN-20
        pdu ZCUDZCUDCAN1SignalIPDU10: length=8, unused-bit-pattern=0
          signal isDrvrSeatPosPercSeatPosFrntHeiPerc: start 15, 10 bit, big-endian, data-type-policy=NETWORK-REPRESENTATION-FROM-COM-SPEC, init-value=1000, base-type=Perc9_2, compu-method=Perc9_1, category=VALUE, to SRS3  # Front Height Position Percentage
          signal isDispOfPrpsnMod: start 60, 4 bit, big-endian, data-type-policy=NETWORK-REPRESENTATION-FROM-COM-SPEC, init-value=0, base-type=DispOfPrpsnMod4_3, compu-method=DispOfPrpsnMod4_3, update-indication-bit-position=56, to SRS3  # Description: Actual powertrain propulsion mode of the hybrid propulsion system. Usage: For hybrid power flow status display in HMI.
          signal isDrvrSeatPosPercSeatPosSldQF: start 21, 2 bit, big-endian, data-type-policy=NETWORK-REPRESENTATION-FROM-COM-SPEC, init-value=1, base-type=Qf1_2, compu-method=Qf1_1, category=VALUE, to SRS3  # Length Position Quality Factor
          signal isDrvrSeatPosPercSeatPosHeiPerc: start 17, 10 bit, big-endian, data-type-policy=NETWORK-REPRESENTATION-FROM-COM-SPEC, init-value=1000, base-type=Perc9_2, compu-method=Perc9_1, category=VALUE, to SRS3  # Height Position Percentage
          signal isDrvrSeatPosPercSeatPosSldPerc: start 39, 10 bit, big-endian, data-type-policy=NETWORK-REPRESENTATION-FROM-COM-SPEC, init-value=1000, base-type=Perc9_2, compu-method=Perc9_1, category=VALUE, to SRS3  # Length Position Percentage
          signal isDrvrSeatPosPercSeatPosHeiQF: start 19, 2 bit, big-endian, data-type-policy=NETWORK-REPRESENTATION-FROM-COM-SPEC, init-value=1, base-type=Qf1_2, compu-method=Qf1_1, category=VALUE, to SRS3  # Height Position Quality Factor
          signal isPassAirbLampStsRecPassAirbLampStsChks: start 55, 8 bit, big-endian, data-type-policy=NETWORK-REPRESENTATION-FROM-COM-SPEC, init-value=255, base-type=UInt8_2, compu-method=UInt8_1, category=VALUE, to SRS3  # Ones complement of the data and counter in the signal group.
          signal isPassAirbLampStsRecPassAirbLampSts: start 45, 2 bit, big-endian, data-type-policy=NETWORK-REPRESENTATION-FROM-COM-SPEC, init-value=1, base-type=PassAirbLampSts1_2, compu-method=PassAirbLampSts1_1, category=VALUE, to SRS3  # Signals if there is a HW fault, SW fault or signaling fault related to the PAD and PAE indication lamps.
          signal isDispOfPrpsnModForEv: start 7, 4 bit, big-endian, data-type-policy=NETWORK-REPRESENTATION-FROM-COM-SPEC, init-value=0, base-type=DispOfPrpsnModForEv_2, compu-method=DispOfPrpsnModForEv_2, update-indication-bit-position=3, to SRS3  # Actual powertrain propulsion mode of the BEV propulsion system. Usage: For BEV power flow status display in HMI.
          signal isDrvrSeatPosPercSeatPosFrntHeiQF: start 1, 2 bit, big-endian, data-type-policy=NETWORK-REPRESENTATION-FROM-COM-SPEC, init-value=1, base-type=Qf1_2, compu-method=Qf1_1, category=VALUE, to SRS3  # Front Height Position Quality Factor
          signal isPassAirbLampStsRecPassAirbLampStsCntr: start 43, 4 bit, big-endian, data-type-policy=NETWORK-REPRESENTATION-FROM-COM-SPEC, init-value=0, base-type=UInt4_2, compu-method=UInt4_1, category=VALUE, to SRS3  # Counter that increases for each updated (not necessarily changed) value.
          signal isRlyPwrDistbnCmd1WdIgnRlyExtCmd: start 62, 1 bit, big-endian, data-type-policy=NETWORK-REPRESENTATION-FROM-COM-SPEC, init-value=0, base-type=OnOff1_2, compu-method=OnOff1_1, update-indication-bit-position=61, to SRS3  # status of the ignition extended relay
          mapping igDrvrSeatPosPerc_mrx: i-signal-group=igDrvrSeatPosPerc, packing-byte-order=big-endian, start-position=1, update-indication-bit-position=2
          mapping igPassAirbLampStsRec_mrx: i-signal-group=igPassAirbLampStsRec, packing-byte-order=big-endian, start-position=45, update-indication-bit-position=63
      frame ZCUDZCUDCAN1Fr97: id 0x13A, to SRS3, frame-length=8, can-addressing-mode=STANDARD, can-fd-frame-support=false, can-frame-rx-behavior=CAN-20
        pdu ZCUDZCUDCAN1SignalIPdu97: length=8, unused-bit-pattern=0
          signal isEngNSafeEngNChks: start 24, 8 bit, big-endian, data-type-policy=NETWORK-REPRESENTATION-FROM-COM-SPEC, init-value=0, base-type=UInt8_2, compu-method=UInt8_1, category=VALUE, to SRS3  # Engine Speed [rpm] and Engine Speed derivative [rpm/s]
          signal isEngNSafeEngNCntr: start 32, 4 bit, big-endian, data-type-policy=NETWORK-REPRESENTATION-FROM-COM-SPEC, init-value=0, base-type=UInt4_2, compu-method=UInt4_1, category=VALUE, to SRS3  # Engine Speed [rpm] and Engine Speed derivative [rpm/s]
          signal isEngNSafeEngN: start 23, 15 bit, big-endian, data-type-policy=NETWORK-REPRESENTATION-FROM-COM-SPEC, init-value=0, base-type=N30_2, compu-method=N30_1, category=VALUE, to SRS3  # Engine Speed [rpm] and Engine Speed derivative [rpm/s]
          signal isEngNSafeEngNGrdt: start 7, 16 bit, big-endian, data-type-policy=NETWORK-REPRESENTATION-FROM-COM-SPEC, init-value=0, base-type=NGrdt1_2, compu-method=NGrdt1_1, category=VALUE, to SRS3  # Engine Speed [rpm] and Engine Speed derivative [rpm/s]
          mapping igEngNSafe_mrx: i-signal-group=igEngNSafe, packing-byte-order=big-endian, start-position=7, update-indication-bit-position=44
      frame ZCUDZCUDCAN1Fr70: id 0x99, to SRS3, frame-length=8, can-addressing-mode=STANDARD, can-fd-frame-support=false, can-frame-rx-behavior=CAN-20
        pdu ZCUDZCUDCAN1SignalIPDU70: length=8, unused-bit-pattern=0
          signal isSftyAirbRollovrSuppSwt: start 19, 2 bit, big-endian, data-type-policy=NETWORK-REPRESENTATION-FROM-COM-SPEC, init-value=0, base-type=OnOffNoReq_2, compu-method=OnOffNoReq_1, update-indication-bit-position=17, to SRS3  # Aigbag roll over deactivate switch request
          signal isPassAirbNotiConfirm: start 22, 2 bit, big-endian, data-type-policy=NETWORK-REPRESENTATION-FROM-COM-SPEC, init-value=0, base-type=Onoff3_1, compu-method=Onoff3_1, update-indication-bit-position=20, to SRS3  # Passenger airbag message confirmation feedback
      frame ZCUDZCUDCAN1Fr49: id 0x314, to SRS3, frame-length=8, can-addressing-mode=STANDARD, can-fd-frame-support=false, can-frame-rx-behavior=CAN-20
        pdu ZCUDZCUDCAN1SignalIPDU49: length=8, unused-bit-pattern=0
          signal isOverlap: start 47, 8 bit, big-endian, data-type-policy=NETWORK-REPRESENTATION-FROM-COM-SPEC, init-value=100, base-type=PercSign1_2, compu-method=PercSign1_1, update-indication-bit-position=28, to SRS3  # predicted Object Overlap, i.e. the portion of the ego vehicle covered by the collision object, is between 25% and 100%.
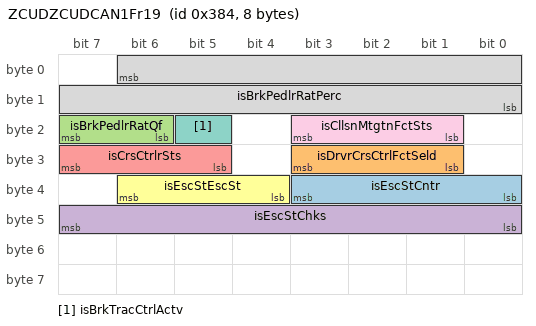
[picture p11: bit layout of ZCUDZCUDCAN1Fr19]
      frame ZCUDZCUDCAN1Fr19: id 0x384, to SRS3, frame-length=8, can-addressing-mode=STANDARD, can-fd-frame-support=false, can-frame-rx-behavior=CAN-20
        pdu ZCUDZCUDCAN1SignalIPDU19: length=8, unused-bit-pattern=0
          signal isEscStCntr: start 35, 4 bit, big-endian, data-type-policy=NETWORK-REPRESENTATION-FROM-COM-SPEC, init-value=0, base-type=UInt4_2, compu-method=UInt4_1, category=VALUE, to SRS3  # Information on activation/ deactivation of Electronic Stability Control (ESC) Counter for Esc state
          signal isDrvrCrsCtrlFctSeld: start 27, 3 bit, big-endian, data-type-policy=NETWORK-REPRESENTATION-FROM-COM-SPEC, init-value=0, base-type=DrvrCrsCtrlFctSeldTyp_5, compu-method=DrvrCrsCtrlFctSeldTyp_4, update-indication-bit-position=24, to SRS3  # select ACC function or CC function.
          signal isBrkPedlrRatQf: start 23, 2 bit, big-endian, data-type-policy=NETWORK-REPRESENTATION-FROM-COM-SPEC, init-value=0, base-type=GenQf1_2, compu-method=GenQf1_1, category=VALUE, to SRS3  # quality factor
          signal isEscStChks: start 47, 8 bit, big-endian, data-type-policy=NETWORK-REPRESENTATION-FROM-COM-SPEC, init-value=0, base-type=UInt8_2, compu-method=UInt8_1, category=VALUE, to SRS3  # Information on activation/ deactivation of Electronic Stability Control (ESC) Checksum for Esc state
          signal isCrsCtrlrSts: start 31, 3 bit, big-endian, data-type-policy=NETWORK-REPRESENTATION-FROM-COM-SPEC, init-value=1, base-type=CrsCtrlrSts1_2, compu-method=CrsCtrlrSts1_1, update-indication-bit-position=28, to SRS3  # The signal indicates the status (or state) of the Cruise Controller; Off, Standby, Actv etc.
          signal isEscStEscSt: start 38, 3 bit, big-endian, data-type-policy=NETWORK-REPRESENTATION-FROM-COM-SPEC, init-value=1, base-type=EscSt1_2, compu-method=EscSt1_1, category=VALUE, to SRS3  # Information on activation/ deactivation of Electronic Stability Control (ESC) Esc state information for Esc ON, Esc OFF or Esc Sport
          signal isBrkTracCtrlActv: start 21, 1 bit, big-endian, data-type-policy=NETWORK-REPRESENTATION-FROM-COM-SPEC, init-value=0, base-type=CtrlSts1_2, compu-method=CtrlSts1_1, update-indication-bit-position=20, to SRS3  # Indicates InCtrl if brake traction control (TC) is active on at least one wheel.
          signal isBrkPedlrRatPerc: start 6, 15 bit, big-endian, data-type-policy=NETWORK-REPRESENTATION-FROM-COM-SPEC, init-value=0, base-type=Perc1_2, compu-method=Perc1_1, category=VALUE, to SRS3  # Brake pedal Ratio in percentage value
          signal isCllsnMtgtnFctSts: start 19, 3 bit, big-endian, data-type-policy=NETWORK-REPRESENTATION-FROM-COM-SPEC, init-value=2, base-type=CllsnMtgtnFctSts_2, compu-method=CllsnMtgtnFctSts_2, update-indication-bit-position=16, to SRS3  # Shows if the AEB function is on or off.
          mapping igBrkPedlrRat_mrx: i-signal-group=igBrkPedlrRat, packing-byte-order=big-endian, start-position=6, update-indication-bit-position=7
          mapping igEscSt_mrx: i-signal-group=igEscSt, packing-byte-order=big-endian, start-position=38, update-indication-bit-position=39
      frame RmlZcudCAN1Frame1: id 0x153, to SRS3, frame-length=8, can-addressing-mode=STANDARD, can-fd-frame-support=false, can-frame-rx-behavior=CAN-20
        pdu RmlZcudCAN1SignalIPdu01: length=8, unused-bit-pattern=0
          signal isStsForRtrctrRvsbLe: start 5, 2 bit, big-endian, data-type-policy=NETWORK-REPRESENTATION-FROM-COM-SPEC, init-value=0, base-type=NotOkOk_2, compu-method=NotOkOk_2, update-indication-bit-position=8, to SRS3  # Belt ready status
          signal isActvnStsOfRtrctrRvsbLe: start 3, 1 bit, big-endian, data-type-policy=NETWORK-REPRESENTATION-FROM-COM-SPEC, init-value=0, base-type=Enumeration1_2, compu-method=Enumeration1_1, update-indication-bit-position=6, to SRS3  # Signals to the SRS (and other nodes) that the belts have triggered.
      frame ZCUDZCUDCAN1Fr25: id 0x24, to SRS3, frame-length=8, can-addressing-mode=STANDARD, can-fd-frame-support=false, can-frame-rx-behavior=CAN-20
        pdu ZCUDZCUDCAN1SignalIPDU25: length=8, unused-bit-pattern=0
          signal isAccrpedlStsChks: start 55, 8 bit, big-endian, data-type-policy=NETWORK-REPRESENTATION-FROM-COM-SPEC, init-value=0, base-type=UInt8_2, compu-method=UInt8_1, category=VALUE, to SRS3  # It should provide acceleration pedal Status signal ( AccrpedlSts ) to predict whether the accelerator pedal has fault or not.1-Fault; 0-NoFault
          signal isAccrpedlStsFltSts: start 59, 1 bit, big-endian, data-type-policy=NETWORK-REPRESENTATION-FROM-COM-SPEC, init-value=0, base-type=Flt_3, compu-method=Flt_3, category=VALUE, to SRS3  # It should provide acceleration pedal Status signal ( AccrpedlSts ) to predict whether the accelerator pedal has fault or not.1-Fault; 0-NoFault
          signal isAccrpedlStsCntr: start 63, 4 bit, big-endian, data-type-policy=NETWORK-REPRESENTATION-FROM-COM-SPEC, init-value=0, base-type=UInt4_2, compu-method=UInt4_1, category=VALUE, to SRS3  # It should provide acceleration pedal Status signal ( AccrpedlSts ) to predict whether the accelerator pedal has fault or not.1-Fault; 0-NoFault
          mapping igAccrpedlSts_mrx: i-signal-group=igAccrpedlSts, packing-byte-order=big-endian, start-position=55, update-indication-bit-position=58
      frame ZCUDZCUDCAN1Fr23: id 0x345, to SRS3, frame-length=8, can-addressing-mode=STANDARD, can-fd-frame-support=false, can-frame-rx-behavior=CAN-20
        pdu ZCUDZCUDCAN1SignalIPDU23: length=8, unused-bit-pattern=0
          signal isAbsCtrlActvCtrlSts1: start 27, 1 bit, big-endian, data-type-policy=NETWORK-REPRESENTATION-FROM-COM-SPEC, init-value=0, base-type=CtrlSts1_2, compu-method=CtrlSts1_1, category=VALUE, to SRS3  # Anti Blocking Systems (ABS) control is active (at least one wheel) 0 = No wheel is in Anti Blocking Systems (ABS) control 1 = At least one wheel is in Anti Blocking Systems (ABS) control
          signal isAbsCtrlActvChks: start 23, 8 bit, big-endian, data-type-policy=NETWORK-REPRESENTATION-FROM-COM-SPEC, init-value=0, base-type=UInt8_2, compu-method=UInt8_1, category=VALUE, to SRS3  # checksum
          signal isAbsSts: start 25, 1 bit, big-endian, data-type-policy=NETWORK-REPRESENTATION-FROM-COM-SPEC, init-value=0, base-type=DevErrSts2_2, compu-method=DevErrSts2_1, update-indication-bit-position=24, to SRS3  # Indicates if the ABS function is temporarily or permantly disabled due to a failure.
          signal isAbsCtrlActvCntr: start 31, 4 bit, big-endian, data-type-policy=NETWORK-REPRESENTATION-FROM-COM-SPEC, init-value=0, base-type=UInt4_2, compu-method=UInt4_1, category=VALUE, to SRS3  # counter
          mapping igAbsCtrlActv_mrx: i-signal-group=igAbsCtrlActv, packing-byte-order=big-endian, start-position=23, update-indication-bit-position=26
      frame ZCUDZCUDCAN1Fr47: id 0x50, to SRS3, frame-length=8, can-addressing-mode=STANDARD, can-fd-frame-support=false, can-frame-rx-behavior=CAN-20
        pdu ZCUDZCUDCAN1SignalIPDU47: length=8, unused-bit-pattern=0
          signal isPreCrashFrontDataChks: start 23, 8 bit, big-endian, data-type-policy=NETWORK-REPRESENTATION-FROM-COM-SPEC, init-value=0, base-type=UInt8_2, compu-method=UInt8_1, category=VALUE, to SRS3  # crc
          signal isPreCrashFrontDataCntr: start 47, 4 bit, big-endian, data-type-policy=NETWORK-REPRESENTATION-FROM-COM-SPEC, init-value=0, base-type=UInt4_2, compu-method=UInt4_1, category=VALUE, to SRS3  # counter
          signal isPreCrashFrontDataClosingVelocity: start 31, 8 bit, big-endian, data-type-policy=NETWORK-REPRESENTATION-FROM-COM-SPEC, init-value=0, base-type=ClosingVelocity_1, compu-method=ClosingVelocity_1, category=VALUE, to SRS3  # collision relative velocity
          signal isPreCrashFrontDataTimeToImpact: start 39, 8 bit, big-endian, data-type-policy=NETWORK-REPRESENTATION-FROM-COM-SPEC, init-value=250, base-type=TimeToImpact_1, compu-method=TimeToImpact_1, category=VALUE, to SRS3  # time to impact
          signal isPreCrashFrontDataOverLap: start 15, 8 bit, big-endian, data-type-policy=NETWORK-REPRESENTATION-FROM-COM-SPEC, init-value=100, base-type=PercSign1_2, compu-method=PercSign1_1, category=VALUE, to SRS3  # overlap
          signal isPreCrashFrontDataObjectClass: start 43, 3 bit, big-endian, data-type-policy=NETWORK-REPRESENTATION-FROM-COM-SPEC, init-value=0, base-type=ObjectClass_2, compu-method=ObjectClass_2, category=VALUE, to SRS3  # object type
          mapping igPreCrashFrontData_mrx: i-signal-group=igPreCrashFrontData, packing-byte-order=big-endian, start-position=15, update-indication-bit-position=40
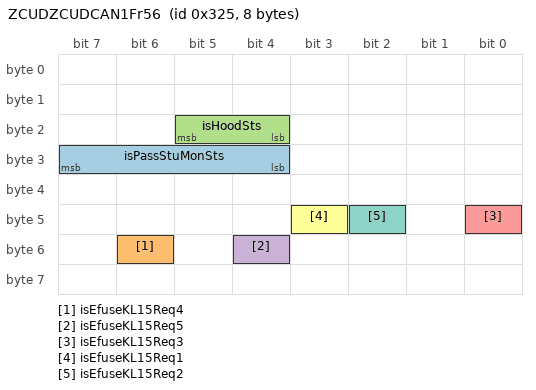
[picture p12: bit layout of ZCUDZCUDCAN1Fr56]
      frame ZCUDZCUDCAN1Fr56: id 0x325, to SRS3, frame-length=8, can-addressing-mode=STANDARD, can-fd-frame-support=false, can-frame-rx-behavior=CAN-20
        pdu ZCUDZCUDCAN1SignalIPDU56: length=8, unused-bit-pattern=0
          signal isPassStuMonSts: start 31, 4 bit, big-endian, data-type-policy=NETWORK-REPRESENTATION-FROM-COM-SPEC, init-value=0, base-type=UInt4_2, compu-method=UInt4_1, update-indication-bit-position=27, to SRS3  # Front passenger body position detection and front and back child seat detection
          signal isEfuseKL15Req4: start 54, 1 bit, big-endian, data-type-policy=NETWORK-REPRESENTATION-FROM-COM-SPEC, init-value=0, base-type=OnOff1_2, compu-method=OnOff1_1, update-indication-bit-position=53, to SRS3  # ON/OFF
          signal isHoodSts: start 21, 2 bit, big-endian, data-type-policy=NETWORK-REPRESENTATION-FROM-COM-SPEC, init-value=0, base-type=DoorSts2_2, compu-method=DoorSts2_1, update-indication-bit-position=19, to SRS3  # HoodSts - Hood Status Ukwn - Unknown status Opend - Opened Clsd - Closed
          signal isEfuseKL15Req5: start 52, 1 bit, big-endian, data-type-policy=NETWORK-REPRESENTATION-FROM-COM-SPEC, init-value=0, base-type=OnOff1_2, compu-method=OnOff1_1, update-indication-bit-position=51, to SRS3  # ON/OFF
          signal isEfuseKL15Req3: start 40, 1 bit, big-endian, data-type-policy=NETWORK-REPRESENTATION-FROM-COM-SPEC, init-value=0, base-type=OnOff1_2, compu-method=OnOff1_1, update-indication-bit-position=55, to SRS3  # ON/OFF
          signal isEfuseKL15Req1: start 43, 1 bit, big-endian, data-type-policy=NETWORK-REPRESENTATION-FROM-COM-SPEC, init-value=0, base-type=OnOff1_2, compu-method=OnOff1_1, update-indication-bit-position=23, to SRS3  # ON/OFF
          signal isEfuseKL15Req2: start 42, 1 bit, big-endian, data-type-policy=NETWORK-REPRESENTATION-FROM-COM-SPEC, init-value=0, base-type=OnOff1_2, compu-method=OnOff1_1, update-indication-bit-position=41, to SRS3  # ON/OFF
      frame ZCUDZCUDCAN1Fr76: id 0x1A3, to SRS3, frame-length=8, can-addressing-mode=STANDARD, can-fd-frame-support=false, can-frame-rx-behavior=CAN-20
        pdu ZCUDZCUDCAN1SignalIPDU76: length=8, unused-bit-pattern=0
          signal isZCUDMResdSig1ToSRSSafetyUInt32: start 7, 32 bit, big-endian, data-type-policy=NETWORK-REPRESENTATION-FROM-COM-SPEC, init-value=0, base-type=UInt32_2, compu-method=UInt32_1, category=VALUE, to SRS3
          signal isZCUDMResdSig1ToSRSSafetyChks: start 39, 8 bit, big-endian, data-type-policy=NETWORK-REPRESENTATION-FROM-COM-SPEC, init-value=0, base-type=UInt8_2, compu-method=UInt8_1, category=VALUE, to SRS3
          signal isZCUDMResdSig1ToSRSSafetyCntr: start 47, 4 bit, big-endian, data-type-policy=NETWORK-REPRESENTATION-FROM-COM-SPEC, init-value=0, base-type=UInt4_2, compu-method=UInt4_1, category=VALUE, to SRS3
          mapping igZCUDMResdSig1ToSRSSafety_mrx: i-signal-group=igZCUDMResdSig1ToSRSSafety, packing-byte-order=big-endian, start-position=7, update-indication-bit-position=43
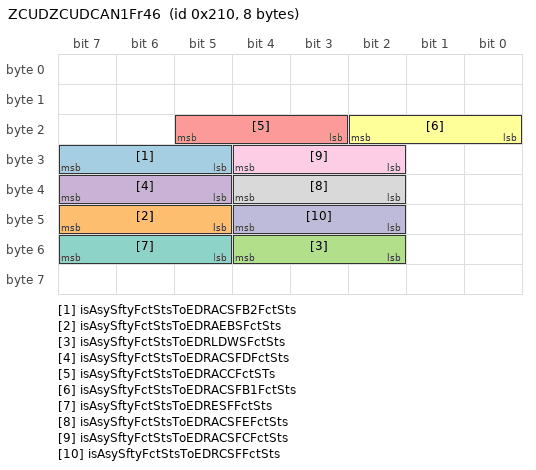
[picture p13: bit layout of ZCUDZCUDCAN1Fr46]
      frame ZCUDZCUDCAN1Fr46: id 0x210, to SRS3, frame-length=8, can-addressing-mode=STANDARD, can-fd-frame-support=false, can-frame-rx-behavior=CAN-20
        pdu ZCUDZCUDCAN1SignalIPDU46: length=8, unused-bit-pattern=0
          signal isAsySftyFctStsToEDRACSFB2FctSts: start 31, 3 bit, big-endian, data-type-policy=NETWORK-REPRESENTATION-FROM-COM-SPEC, init-value=0, base-type=FctSTs_1, compu-method=ACCFctSTs_1, category=VALUE, to SRS3  # The signal indicates the function status of the ACSF B2.
          signal isAsySftyFctStsToEDRAEBSFctSts: start 47, 3 bit, big-endian, data-type-policy=NETWORK-REPRESENTATION-FROM-COM-SPEC, init-value=0, base-type=AEBSFctSts_1, compu-method=AEBSFctSts_1, category=VALUE, to SRS3  # The signal indicates the function status of the AEB and FCW function.
          signal isAsySftyFctStsToEDRLDWSFctSts: start 52, 3 bit, big-endian, data-type-policy=NETWORK-REPRESENTATION-FROM-COM-SPEC, init-value=0, base-type=LDWSFctSts_1, compu-method=LDWSFctSts_1, category=VALUE, to SRS3  # The signal indicates the function status of the LDW function.
          signal isAsySftyFctStsToEDRACSFDFctSts: start 39, 3 bit, big-endian, data-type-policy=NETWORK-REPRESENTATION-FROM-COM-SPEC, init-value=0, base-type=FctSTs_1, compu-method=ACCFctSTs_1, category=VALUE, to SRS3  # The signal indicates the function status of the ACSF D.
          signal isAsySftyFctStsToEDRACCFctSTs: start 21, 3 bit, big-endian, data-type-policy=NETWORK-REPRESENTATION-FROM-COM-SPEC, init-value=0, base-type=FctSTs_1, compu-method=ACCFctSTs_1, category=VALUE, to SRS3  # The signal indicates the function status of the ACC function.
          signal isAsySftyFctStsToEDRACSFB1FctSts: start 18, 3 bit, big-endian, data-type-policy=NETWORK-REPRESENTATION-FROM-COM-SPEC, init-value=0, base-type=FctSTs_1, compu-method=ACCFctSTs_1, category=VALUE, to SRS3  # The signal indicates the function status of the HWA function.
          signal isAsySftyFctStsToEDRESFFctSts: start 55, 3 bit, big-endian, data-type-policy=NETWORK-REPRESENTATION-FROM-COM-SPEC, init-value=0, base-type=FctSTs_1, compu-method=ACCFctSTs_1, category=VALUE, to SRS3  # The signal indicates the function status of the ELKA function.
          signal isAsySftyFctStsToEDRACSFEFctSts: start 36, 3 bit, big-endian, data-type-policy=NETWORK-REPRESENTATION-FROM-COM-SPEC, init-value=0, base-type=FctSTs_1, compu-method=ACCFctSTs_1, category=VALUE, to SRS3  # The signal indicates the function status of the ACSF E.
          signal isAsySftyFctStsToEDRACSFCFctSts: start 28, 3 bit, big-endian, data-type-policy=NETWORK-REPRESENTATION-FROM-COM-SPEC, init-value=0, base-type=FctSTs_1, compu-method=ACCFctSTs_1, category=VALUE, to SRS3  # The signal indicates the function status of the ALCA function.
          signal isAsySftyFctStsToEDRCSFFctSts: start 44, 3 bit, big-endian, data-type-policy=NETWORK-REPRESENTATION-FROM-COM-SPEC, init-value=0, base-type=FctSTs_1, compu-method=ACCFctSTs_1, category=VALUE, to SRS3  # The signal indicates the function status of the LKA function.
          mapping igAsySftyFctStsToEDR_mrx: i-signal-group=igAsySftyFctStsToEDR, packing-byte-order=big-endian, start-position=21, update-indication-bit-position=49
      frame ZCUDZCUDCAN1Fr01: id 0x40, to SRS3, frame-length=8, can-addressing-mode=STANDARD, can-fd-frame-support=false, can-frame-rx-behavior=CAN-20
        pdu ZCUDZCUDCAN1SignalIPDU01: length=8, unused-bit-pattern=0
          signal isDoorDrvrSts: start 55, 2 bit, big-endian, data-type-policy=NETWORK-REPRESENTATION-FROM-COM-SPEC, init-value=0, base-type=DoorSts2_2, compu-method=DoorSts2_1, update-indication-bit-position=53, to SRS3  # DoorDrvrSts - Driver Door Status Ukwn - Unknown status Opend - Opened Clsd - Closed
          signal isDoorLeReSts: start 43, 2 bit, big-endian, data-type-policy=NETWORK-REPRESENTATION-FROM-COM-SPEC, init-value=0, base-type=DoorSts2_2, compu-method=DoorSts2_1, update-indication-bit-position=44, to SRS3  # DoorLeReSts - Left Rear Side Door Status. Ukwn - Unknown status Opend - Opened Clsd - Closed
          signal isVehMtnStCntr: start 6, 4 bit, big-endian, data-type-policy=NETWORK-REPRESENTATION-FROM-COM-SPEC, init-value=0, base-type=UInt4_2, compu-method=UInt4_1, category=VALUE, to SRS3  # Vehicle motion state information based on wheel speed sensors. Provides information about vehicle stand still and vehicle rolling direction. Counter for vehicle motion state
          signal isVehMtnStVehMtnSt: start 2, 3 bit, big-endian, data-type-policy=NETWORK-REPRESENTATION-FROM-COM-SPEC, init-value=0, base-type=VehMtnSt2_2, compu-method=VehMtnSt2_1, category=VALUE, to SRS3  # Vehicle motion state information based on wheel speed sensors. Provides information about vehicle stand still and vehicle rolling direction. Vehicle motion state
          signal isVehMtnStChks: start 15, 8 bit, big-endian, data-type-policy=NETWORK-REPRESENTATION-FROM-COM-SPEC, init-value=0, base-type=UInt8_2, compu-method=UInt8_1, category=VALUE, to SRS3  # Vehicle motion state information based on wheel speed sensors. Provides information about vehicle stand still and vehicle rolling direction. Checksum for vehicle motion state
          mapping igVehMtnSt_mrx: i-signal-group=igVehMtnSt, packing-byte-order=big-endian, start-position=6, update-indication-bit-position=7
      frame ZcudToSrsZCUDCan1DiagReqFr: id 0x739, to SRS3, frame-length=8, can-addressing-mode=STANDARD, can-fd-frame-support=false, can-frame-rx-behavior=CAN-20
        n pdu ZcudToSrsZCUDCan1DiagReqNpdu: length=8
      frame ZCUDZCUDCAN1Fr05: id 0x370, to SRS3, frame-length=8, can-addressing-mode=STANDARD, can-fd-frame-support=false, can-frame-rx-behavior=CAN-20
        pdu ZCUDZCUDCAN1SignalIPDU05: length=8, unused-bit-pattern=0
          signal isCarTiGlb: start 39, 32 bit, big-endian, data-type-policy=NETWORK-REPRESENTATION-FROM-COM-SPEC, init-value=0, base-type=CarTiGlb_2, compu-method=CarTiGlb_1, update-indication-bit-position=13, to SRS3  # Presents a tiime value that shall be used by all ECUs to time-stamp diagnsotic trouble codes (DTC) according to the requirements for Global DTC snapshot data.
      frame ZCUDZCUDCAN1Fr32: id 0x143, to SRS3, frame-length=8, can-addressing-mode=STANDARD, can-fd-frame-support=false, can-frame-rx-behavior=CAN-20
        pdu ZCUDZCUDCAN1SignalIPDU32: length=8, unused-bit-pattern=0
          signal isPosnBriefPosnLgt: start 38, 31 bit, big-endian, data-type-policy=NETWORK-REPRESENTATION-FROM-COM-SPEC, init-value=180, base-type=PosnLgt_2, compu-method=PosnLgt_1, category=VALUE, to SRS3  # Longitude
          signal isPosnBriefPosnLat: start 5, 30 bit, big-endian, data-type-policy=NETWORK-REPRESENTATION-FROM-COM-SPEC, init-value=90, base-type=PosnLat_2, compu-method=PosnLat_1, category=VALUE, to SRS3  # Latitude
          mapping igPosnBrief_mrx: i-signal-group=igPosnBrief, packing-byte-order=big-endian, start-position=5, update-indication-bit-position=6
      frame ZCUDZCUDCAN1Fr29: id 0x83, to SRS3, frame-length=8, can-addressing-mode=STANDARD, can-fd-frame-support=false, can-frame-rx-behavior=CAN-20
        pdu ZCUDZCUDCAN1SignalIPDU29: length=8, unused-bit-pattern=0
          signal isSftyDecelGroupSafeChks: start 39, 8 bit, big-endian, data-type-policy=NETWORK-REPRESENTATION-FROM-COM-SPEC, init-value=0, base-type=UInt8_2, compu-method=UInt8_1, category=VALUE, to SRS3  # crc
          signal isSftyDecelGroupSafeCntr: start 43, 4 bit, big-endian, data-type-policy=NETWORK-REPRESENTATION-FROM-COM-SPEC, init-value=0, base-type=UInt4_2, compu-method=UInt4_1, category=VALUE, to SRS3  # counter
          signal isSftyDecelGroupSafeAsySftyDecelReq: start 31, 8 bit, big-endian, data-type-policy=NETWORK-REPRESENTATION-FROM-COM-SPEC, init-value=0, base-type=Decel_1, compu-method=Decel_1, category=VALUE, to SRS3  # target deceleration
          signal isCllsnFwdWarn: start 15, 3 bit, big-endian, data-type-policy=NETWORK-REPRESENTATION-FROM-COM-SPEC, init-value=0, base-type=CllsnFwdWarnReq_1, compu-method=CllsnFwdWarnReq_1, update-indication-bit-position=12, to SRS3  # indicate the FCW warning and Latent warning activation.
          signal isSftyDecelGroupSafeAsySftyEnaDecel: start 44, 1 bit, big-endian, data-type-policy=NETWORK-REPRESENTATION-FROM-COM-SPEC, init-value=0, base-type=OnOff1_2, compu-method=OnOff1_1, category=VALUE, to SRS3  # brake order
          mapping igSftyDecelGroupSafe_mrx: i-signal-group=igSftyDecelGroupSafe, packing-byte-order=big-endian, start-position=31, update-indication-bit-position=51
      frame ZCUDZCUDCAN1Fr50: id 0x471, to SRS3, frame-length=8, can-addressing-mode=STANDARD, can-fd-frame-support=false, can-frame-rx-behavior=CAN-20
        pdu ZCUDZCUDCAN1SignalIPDU50: length=8, unused-bit-pattern=0
          signal isVehHomePrkgSysSts: start 63, 5 bit, big-endian, data-type-policy=NETWORK-REPRESENTATION-FROM-COM-SPEC, init-value=0, base-type=HomePrkgSysSts1_2, compu-method=HomePrkgSysSts1_2, update-indication-bit-position=58, to SRS3  # Home zone parking system status.
      frame ZCUDZCUDCAN1Fr18: id 0x181, to SRS3, frame-length=8, can-addressing-mode=STANDARD, can-fd-frame-support=false, can-frame-rx-behavior=CAN-20
        pdu ZCUDZCUDCAN1SignalIPDU18: length=8, unused-bit-pattern=0
          signal isEmgyAsscTrigSts: start 53, 2 bit, big-endian, data-type-policy=NETWORK-REPRESENTATION-FROM-COM-SPEC, init-value=0, base-type=AfsStsReq_7, compu-method=AfsStsReq_4, update-indication-bit-position=54, to SRS3  # Defined the signal as: 0: when the eCall without trigget 1: eCall been automatically trigget by SRS 2: eCall been manually trigget by user via SOS button 3: eCall has fault when SRS trigget crash
      frame ZCUDZCUDCAN1Fr26: id 0x32F, to SRS3, frame-length=8, can-addressing-mode=STANDARD, can-fd-frame-support=false, can-frame-rx-behavior=CAN-20
        pdu ZCUDZCUDCAN1SignalIPDU26: length=8, unused-bit-pattern=0
          signal isBrkPedlPsdBrkPedlNotPsdSafe: start 7, 1 bit, big-endian, data-type-policy=NETWORK-REPRESENTATION-FROM-COM-SPEC, init-value=0, base-type=NoYes1_2, compu-method=NoYes1_1, category=VALUE, to SRS3  # Set to 1 if brake pedal is not pressed, otherwise 0
          signal isBrkPedlPsdCntr: start 3, 4 bit, big-endian, data-type-policy=NETWORK-REPRESENTATION-FROM-COM-SPEC, init-value=0, base-type=UInt4_2, compu-method=UInt4_1, category=VALUE, to SRS3  # Counter
          signal isBrkPedlPsdBrkPedlPsd: start 6, 1 bit, big-endian, data-type-policy=NETWORK-REPRESENTATION-FROM-COM-SPEC, init-value=0, base-type=NoYes1_2, compu-method=NoYes1_1, category=VALUE, to SRS3  # Set to 1 if brake pedal is pressed, otherwise 0
          signal isBrkPedlPsdChks: start 15, 8 bit, big-endian, data-type-policy=NETWORK-REPRESENTATION-FROM-COM-SPEC, init-value=0, base-type=UInt8_2, compu-method=UInt8_1, category=VALUE, to SRS3  # Checksum
          signal isBrkPedlPsdQf: start 5, 2 bit, big-endian, data-type-policy=NETWORK-REPRESENTATION-FROM-COM-SPEC, init-value=0, base-type=GenQf1_2, compu-method=GenQf1_1, category=VALUE, to SRS3  # Quality factor
          mapping igBrkPedlPsd_mrx: i-signal-group=igBrkPedlPsd, packing-byte-order=big-endian, start-position=7, update-indication-bit-position=23
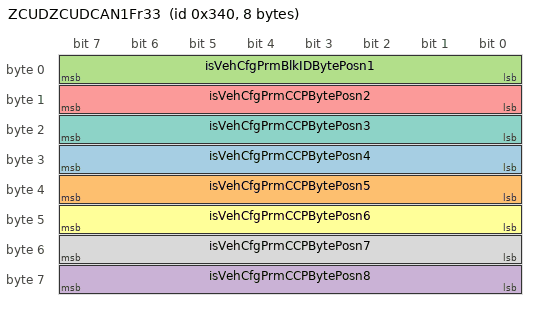
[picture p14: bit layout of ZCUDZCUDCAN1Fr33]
      frame ZCUDZCUDCAN1Fr33: id 0x340, to SRS3, frame-length=8, can-addressing-mode=STANDARD, can-fd-frame-support=false, can-frame-rx-behavior=CAN-20
        pdu ZCUDZCUDCAN1SignalIPDU33: length=8, unused-bit-pattern=0
          signal isVehCfgPrmCCPBytePosn4: start 31, 8 bit, big-endian, data-type-policy=NETWORK-REPRESENTATION-FROM-COM-SPEC, init-value=0, base-type=Nr2_3, compu-method=Nr2_1, category=VALUE, to SRS3  # (BlockID-1)*7 + 3.
          signal isVehCfgPrmCCPBytePosn5: start 39, 8 bit, big-endian, data-type-policy=NETWORK-REPRESENTATION-FROM-COM-SPEC, init-value=0, base-type=Nr2_3, compu-method=Nr2_1, category=VALUE, to SRS3  # (BlockID-1)*7 + 4.
          signal isVehCfgPrmBlkIDBytePosn1: start 7, 8 bit, big-endian, data-type-policy=NETWORK-REPRESENTATION-FROM-COM-SPEC, init-value=0, base-type=Nr2_3, compu-method=Nr2_1, category=VALUE, to SRS3  # signal block counter.
          signal isVehCfgPrmCCPBytePosn8: start 63, 8 bit, big-endian, data-type-policy=NETWORK-REPRESENTATION-FROM-COM-SPEC, init-value=0, base-type=Nr2_3, compu-method=Nr2_1, category=VALUE, to SRS3  # (BlockID-1)*7 + 7.
          signal isVehCfgPrmCCPBytePosn2: start 15, 8 bit, big-endian, data-type-policy=NETWORK-REPRESENTATION-FROM-COM-SPEC, init-value=0, base-type=Nr2_3, compu-method=Nr2_1, category=VALUE, to SRS3  # (BlockID-1)*7 + 1.
          signal isVehCfgPrmCCPBytePosn6: start 47, 8 bit, big-endian, data-type-policy=NETWORK-REPRESENTATION-FROM-COM-SPEC, init-value=0, base-type=Nr2_3, compu-method=Nr2_1, category=VALUE, to SRS3  # (BlockID-1)*7 + 5.
          signal isVehCfgPrmCCPBytePosn3: start 23, 8 bit, big-endian, data-type-policy=NETWORK-REPRESENTATION-FROM-COM-SPEC, init-value=0, base-type=Nr2_3, compu-method=Nr2_1, category=VALUE, to SRS3  # (BlockID-1)*7 + 2.
          signal isVehCfgPrmCCPBytePosn7: start 55, 8 bit, big-endian, data-type-policy=NETWORK-REPRESENTATION-FROM-COM-SPEC, init-value=0, base-type=Nr2_3, compu-method=Nr2_1, category=VALUE, to SRS3  # (BlockID-1)*7 + 6.
          mapping igVehCfgPrm_mrx: i-signal-group=igVehCfgPrm, packing-byte-order=big-endian, start-position=7
      frame ZCUDZCUDCAN1Fr69: id 0x310, to SRS3, frame-length=8, can-addressing-mode=STANDARD, can-fd-frame-support=false, can-frame-rx-behavior=CAN-20
        pdu ZCUDZCUDCAN1SignalIPDU69: length=8, unused-bit-pattern=0
          signal isBkpOfDstTrvld: start 4, 21 bit, big-endian, data-type-policy=NETWORK-REPRESENTATION-FROM-COM-SPEC, init-value=0, base-type=Len31_2, compu-method=Len31_1, update-indication-bit-position=5, to SRS3  # total traveled distance.
      frame ZCUDZCUDCAN1Fr34: id 0x132, to SRS3, frame-length=8, can-addressing-mode=STANDARD, can-fd-frame-support=false, can-frame-rx-behavior=CAN-20
        pdu ZCUDZCUDCAN1SignalIPDU34: length=8, unused-bit-pattern=0
          signal isVehCfgPrmExtCCPBytePosn8: start 63, 8 bit, big-endian, data-type-policy=NETWORK-REPRESENTATION-FROM-COM-SPEC, init-value=0, base-type=Nr2_3, compu-method=Nr2_1, category=VALUE, to SRS3  # CarConfigExtended BytePos8
          signal isVehCfgPrmExtCCPBytePosn4: start 31, 8 bit, big-endian, data-type-policy=NETWORK-REPRESENTATION-FROM-COM-SPEC, init-value=0, base-type=Nr2_3, compu-method=Nr2_1, category=VALUE, to SRS3  # CarConfigExtended BytePos4
          signal isVehCfgPrmExtCCPBytePosn3: start 23, 8 bit, big-endian, data-type-policy=NETWORK-REPRESENTATION-FROM-COM-SPEC, init-value=0, base-type=Nr2_3, compu-method=Nr2_1, category=VALUE, to SRS3  # CarConfigExtended BytePos3
          signal isVehCfgPrmExtCCPBytePosn5: start 39, 8 bit, big-endian, data-type-policy=NETWORK-REPRESENTATION-FROM-COM-SPEC, init-value=0, base-type=Nr2_3, compu-method=Nr2_1, category=VALUE, to SRS3  # CarConfigExtended BytePos5
          signal isVehCfgPrmExtBlkIDBytePosn1: start 7, 8 bit, big-endian, data-type-policy=NETWORK-REPRESENTATION-FROM-COM-SPEC, init-value=0, base-type=Nr2_3, compu-method=Nr2_1, category=VALUE, to SRS3  # CarConfigExtended BlockID
          signal isVehCfgPrmExtCCPBytePosn6: start 47, 8 bit, big-endian, data-type-policy=NETWORK-REPRESENTATION-FROM-COM-SPEC, init-value=0, base-type=Nr2_3, compu-method=Nr2_1, category=VALUE, to SRS3  # CarConfigExtended BytePos6
          signal isVehCfgPrmExtCCPBytePosn7: start 55, 8 bit, big-endian, data-type-policy=NETWORK-REPRESENTATION-FROM-COM-SPEC, init-value=0, base-type=Nr2_3, compu-method=Nr2_1, category=VALUE, to SRS3  # CarConfigExtended BytePos7
          signal isVehCfgPrmExtCCPBytePosn2: start 15, 8 bit, big-endian, data-type-policy=NETWORK-REPRESENTATION-FROM-COM-SPEC, init-value=0, base-type=Nr2_3, compu-method=Nr2_1, category=VALUE, to SRS3  # CarConfigExtended BytePos2
          mapping igVehCfgPrmExt_mrx: i-signal-group=igVehCfgPrmExt, packing-byte-order=big-endian, start-position=7
      frame ZcudToSrsISO26021ZCUDCAN1DiagResFrame11: id 0x7F1, to SRS3, frame-length=8, can-addressing-mode=STANDARD, can-fd-frame-support=false, can-frame-rx-behavior=CAN-20
        n pdu ZcudToSrsISO26021ZCUDCan1ReqNpdu11: length=8
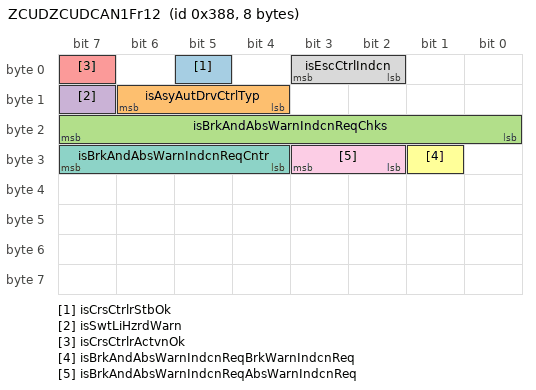
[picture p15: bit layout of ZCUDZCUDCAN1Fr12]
      frame ZCUDZCUDCAN1Fr12: id 0x388, to SRS3, frame-length=8, can-addressing-mode=STANDARD, can-fd-frame-support=false, can-frame-rx-behavior=CAN-20
        pdu ZCUDZCUDCAN1SignalIPDU12: length=8, unused-bit-pattern=0
          signal isCrsCtrlrStbOk: start 5, 1 bit, big-endian, data-type-policy=NETWORK-REPRESENTATION-FROM-COM-SPEC, init-value=0, base-type=OnOff1_2, compu-method=OnOff1_1, update-indication-bit-position=4, to SRS3  # The signal informs if the Cruise Controller can be set to standby or not.
          signal isAsyAutDrvCtrlTyp: start 14, 3 bit, big-endian, data-type-policy=NETWORK-REPRESENTATION-FROM-COM-SPEC, init-value=0, base-type=AsyAutDrvCtrlTyp_4, compu-method=AsyAutDrvCtrlTyp_4, update-indication-bit-position=11, to SRS3  # Indicates if autonomous driving is ACC/TJA/HWA/TJP or only ACC.
          signal isBrkAndAbsWarnIndcnReqChks: start 23, 8 bit, big-endian, data-type-policy=NETWORK-REPRESENTATION-FROM-COM-SPEC, init-value=0, base-type=UInt8_2, compu-method=UInt8_1, category=VALUE, to SRS3  # Request for warning indication to driver in case of brake failure (red warning) or ABS failure (yellow warning) Checksum for Brake and ABS warning indication request
          signal isSwtLiHzrdWarn: start 15, 1 bit, big-endian, data-type-policy=NETWORK-REPRESENTATION-FROM-COM-SPEC, init-value=0, base-type=PsdNotPsd_2, compu-method=PsdNotPsd_1, update-indication-bit-position=0, to SRS3  # Hazard warning light switch signal. 0-not pressed, 1-pressed
          signal isCrsCtrlrActvnOk: start 7, 1 bit, big-endian, data-type-policy=NETWORK-REPRESENTATION-FROM-COM-SPEC, init-value=0, base-type=OnOff1_2, compu-method=OnOff1_1, update-indication-bit-position=6, to SRS3  # The signal informs if Cruise Controller can be activated or not. Primarily used by HMI to know if Cruise Controller activation requests by driver should be ignored or not.
          signal isBrkAndAbsWarnIndcnReqBrkWarnIndcnReq: start 25, 1 bit, big-endian, data-type-policy=NETWORK-REPRESENTATION-FROM-COM-SPEC, init-value=1, base-type=OnOff2_2, compu-method=OnOff2_1, category=VALUE, to SRS3  # Request for warning indication to driver in case of brake failure (red warning) or ABS failure (yellow warning) Brake warning indication request
          signal isBrkAndAbsWarnIndcnReqCntr: start 31, 4 bit, big-endian, data-type-policy=NETWORK-REPRESENTATION-FROM-COM-SPEC, init-value=0, base-type=UInt4_2, compu-method=UInt4_1, category=VALUE, to SRS3  # Request for warning indication to driver in case of brake failure (red warning) or ABS failure (yellow warning) Counter for Brake and ABS warning indication request
          signal isEscCtrlIndcn: start 3, 2 bit, big-endian, data-type-policy=NETWORK-REPRESENTATION-FROM-COM-SPEC, init-value=1, base-type=DevSts1_2, compu-method=DevSts1_1, update-indication-bit-position=1, to SRS3  # Indicates that an Electronic stability control (ESC) controller is active
          signal isBrkAndAbsWarnIndcnReqAbsWarnIndcnReq: start 27, 2 bit, big-endian, data-type-policy=NETWORK-REPRESENTATION-FROM-COM-SPEC, init-value=3, base-type=AbsWarnIndcnReq_2, compu-method=AbsWarnIndcnReq_1, category=VALUE, to SRS3  # Request for warning indication to driver in case of brake failure (red warning) or ABS failure (yellow warning) ABS warning indication request
          mapping igBrkAndAbsWarnIndcnReq_mrx: i-signal-group=igBrkAndAbsWarnIndcnReq, packing-byte-order=big-endian, start-position=23, update-indication-bit-position=24
      frame ZcudToAllFuncZcudCAN1DiagReqFr: id 0x7FF, to SRS3, frame-length=8, can-addressing-mode=STANDARD, can-fd-frame-support=false, can-frame-rx-behavior=CAN-20
        n pdu ZcudToAllFuncZcudCAN1DiagReqNpdu: length=8
      frame ZCUDZCUDCAN1Fr24: id 0x206, to SRS3, frame-length=8, can-addressing-mode=STANDARD, can-fd-frame-support=false, can-frame-rx-behavior=CAN-20
        pdu ZCUDZCUDCAN1SignalIPDU24: length=8, unused-bit-pattern=0
          signal isAccrPedlRatAccrPedlRat: start 6, 15 bit, big-endian, data-type-policy=NETWORK-REPRESENTATION-FROM-COM-SPEC, init-value=0, base-type=Perc1_2, compu-method=Perc1_1, category=VALUE, to SRS3  # Accelerator Pedal Position with adapted 0 point. Value as percentage of fully pressed pedal
          signal isCllsnAidPost: start 44, 1 bit, big-endian, data-type-policy=NETWORK-REPRESENTATION-FROM-COM-SPEC, init-value=0, base-type=OnOff1_2, compu-method=OnOff1_1, update-indication-bit-position=45, to SRS3  # indicate the AEB brake intervention to the driver.
          signal isThrPos: start 39, 8 bit, big-endian, data-type-policy=NETWORK-REPRESENTATION-FROM-COM-SPEC, init-value=0, base-type=Perc2_2, compu-method=Perc2_1, update-indication-bit-position=47, to SRS3  # ECM throttle position (AbsThrottlePosition) on CAN
          signal isAccrPedlRatCntr: start 31, 4 bit, big-endian, data-type-policy=NETWORK-REPRESENTATION-FROM-COM-SPEC, init-value=0, base-type=UInt4_2, compu-method=UInt4_1, category=VALUE, to SRS3  # Accelerator Pedal Position with adapted 0 point. Value as percentage of fully pressed pedal. Counter
          signal isAccrPedlRatChks: start 23, 8 bit, big-endian, data-type-policy=NETWORK-REPRESENTATION-FROM-COM-SPEC, init-value=0, base-type=UInt8_2, compu-method=UInt8_1, category=VALUE, to SRS3  # Accelerator Pedal Position with adapted 0 point. Value as percentage of fully pressed pedal. Checksum
          mapping igAccrPedlRat_mrx: i-signal-group=igAccrPedlRat, packing-byte-order=big-endian, start-position=6, update-indication-bit-position=7
      frame ZCUDZCUDCAN1Fr13: id 0x366, to SRS3, frame-length=8, can-addressing-mode=STANDARD, can-fd-frame-support=false, can-frame-rx-behavior=CAN-20
        pdu ZCUDZCUDCAN1SignalIPDU13: length=8, unused-bit-pattern=0
          signal isRlyPwrDistbnCmd1WdIgnRlyCmd: start 53, 1 bit, big-endian, data-type-policy=NETWORK-REPRESENTATION-FROM-COM-SPEC, init-value=0, base-type=OnOff1_2, compu-method=OnOff1_1, update-indication-bit-position=52, to SRS3  # Ignition relay status
          signal isSumActv: start 47, 1 bit, big-endian, data-type-policy=NETWORK-REPRESENTATION-FROM-COM-SPEC, init-value=0, base-type=Boolean_2, compu-method=Boolean_1, update-indication-bit-position=46, to SRS3  # VMM force all the ECUs into sleep mode during abandon. SUM must inform VMM if it is still running.
          signal isReqForPassAirbIndcnAckd: start 55, 1 bit, big-endian, data-type-policy=NETWORK-REPRESENTATION-FROM-COM-SPEC, init-value=0, base-type=ReqForPassAirbIndcnAckd_2, compu-method=ReqForPassAirbIndcnAckd_1, update-indication-bit-position=54, to SRS3  # info about the acknowledgement
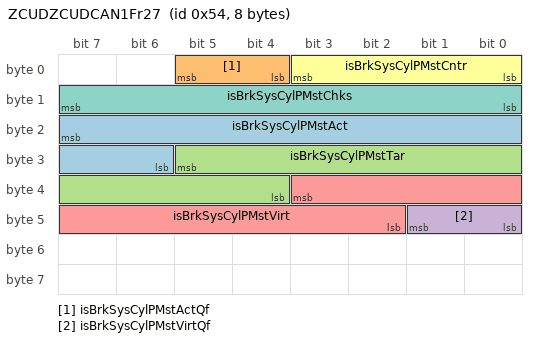
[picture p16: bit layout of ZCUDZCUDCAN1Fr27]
      frame ZCUDZCUDCAN1Fr27: id 0x54, to SRS3, frame-length=8, can-addressing-mode=STANDARD, can-fd-frame-support=false, can-frame-rx-behavior=CAN-20
        pdu ZCUDZCUDCAN1SignalIPDU27: length=8, unused-bit-pattern=0
          signal isBrkSysCylPMstAct: start 23, 10 bit, big-endian, data-type-policy=NETWORK-REPRESENTATION-FROM-COM-SPEC, init-value=100, base-type=P33_2, compu-method=P33_1, category=VALUE, to SRS3  # Brake system master cylinder pressure information Actual pressure, raw value
          signal isBrkSysCylPMstActQf: start 5, 2 bit, big-endian, data-type-policy=NETWORK-REPRESENTATION-FROM-COM-SPEC, init-value=1, base-type=GenQf1_2, compu-method=GenQf1_1, category=VALUE, to SRS3  # Brake system master cylinder pressure information Actual pressure quality factor
          signal isBrkSysCylPMstTar: start 29, 10 bit, big-endian, data-type-policy=NETWORK-REPRESENTATION-FROM-COM-SPEC, init-value=0, base-type=P35_2, compu-method=P35_1, category=VALUE, to SRS3  # Brake system master cylinder pressure information Target pressure
          signal isBrkSysCylPMstVirtQf: start 41, 2 bit, big-endian, data-type-policy=NETWORK-REPRESENTATION-FROM-COM-SPEC, init-value=1, base-type=GenQf1_2, compu-method=GenQf1_1, category=VALUE, to SRS3  # Brake system master cylinder pressure information Virtual pressure quality factor
          signal isBrkSysCylPMstVirt: start 35, 10 bit, big-endian, data-type-policy=NETWORK-REPRESENTATION-FROM-COM-SPEC, init-value=0, base-type=P35_2, compu-method=P35_1, category=VALUE, to SRS3  # Brake system master cylinder pressure information Virtual pressure
          signal isBrkSysCylPMstCntr: start 3, 4 bit, big-endian, data-type-policy=NETWORK-REPRESENTATION-FROM-COM-SPEC, init-value=0, base-type=UInt4_2, compu-method=UInt4_1, category=VALUE, to SRS3  # Brake system master cylinder pressure information Counter
          signal isBrkSysCylPMstChks: start 15, 8 bit, big-endian, data-type-policy=NETWORK-REPRESENTATION-FROM-COM-SPEC, init-value=0, base-type=UInt8_2, compu-method=UInt8_1, category=VALUE, to SRS3  # Brake system master cylinder pressure information Checksum
          mapping igBrkSysCylPMst_mrx: i-signal-group=igBrkSysCylPMst, packing-byte-order=big-endian, start-position=5, update-indication-bit-position=6
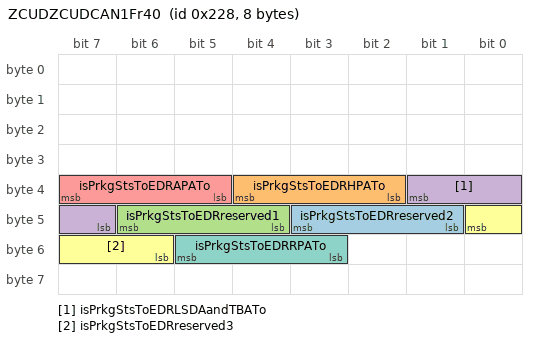
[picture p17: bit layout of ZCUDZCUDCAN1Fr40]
      frame ZCUDZCUDCAN1Fr40: id 0x228, to SRS3, frame-length=8, can-addressing-mode=STANDARD, can-fd-frame-support=false, can-frame-rx-behavior=CAN-20
        pdu ZCUDZCUDCAN1SignalIPDU40: length=8, unused-bit-pattern=0
          signal isPrkgStsToEDRreserved2: start 43, 3 bit, big-endian, data-type-policy=NETWORK-REPRESENTATION-FROM-COM-SPEC, init-value=0, base-type=APATo_1, compu-method=APATo_1, category=VALUE, to SRS3  # reserved2
          signal isPrkgStsToEDRHPATo: start 36, 3 bit, big-endian, data-type-policy=NETWORK-REPRESENTATION-FROM-COM-SPEC, init-value=0, base-type=APATo_1, compu-method=APATo_1, category=VALUE, to SRS3  # HPATo
          signal isPrkgStsToEDRreserved1: start 46, 3 bit, big-endian, data-type-policy=NETWORK-REPRESENTATION-FROM-COM-SPEC, init-value=0, base-type=APATo_1, compu-method=APATo_1, category=VALUE, to SRS3  # reserved1
          signal isPrkgStsToEDRLSDAandTBATo: start 33, 3 bit, big-endian, data-type-policy=NETWORK-REPRESENTATION-FROM-COM-SPEC, init-value=0, base-type=APATo_1, compu-method=APATo_1, category=VALUE, to SRS3  # LSDA&&TBATo
          signal isPrkgStsToEDRAPATo: start 39, 3 bit, big-endian, data-type-policy=NETWORK-REPRESENTATION-FROM-COM-SPEC, init-value=0, base-type=APATo_1, compu-method=APATo_1, category=VALUE, to SRS3  # APATo
          signal isPrkgStsToEDRreserved3: start 40, 3 bit, big-endian, data-type-policy=NETWORK-REPRESENTATION-FROM-COM-SPEC, init-value=0, base-type=APATo_1, compu-method=APATo_1, category=VALUE, to SRS3  # reserved3
          signal isPrkgStsToEDRRPATo: start 53, 3 bit, big-endian, data-type-policy=NETWORK-REPRESENTATION-FROM-COM-SPEC, init-value=0, base-type=APATo_1, compu-method=APATo_1, category=VALUE, to SRS3  # RPATo
          mapping igPrkgStsToEDR_mrx: i-signal-group=igPrkgStsToEDR, packing-byte-order=big-endian, start-position=39, update-indication-bit-position=50
      frame ZCUDZCUDCAN1Fr37: id 0x76, to SRS3, frame-length=8, can-addressing-mode=STANDARD, can-fd-frame-support=false, can-frame-rx-behavior=CAN-20
        pdu ZCUDZCUDCAN1SignalIPDU37: length=8, unused-bit-pattern=0
          signal isVehSpdLgtQf: start 43, 2 bit, big-endian, data-type-policy=NETWORK-REPRESENTATION-FROM-COM-SPEC, init-value=1, base-type=GenQf1_2, compu-method=GenQf1_1, category=VALUE, to SRS3  # Quality factor for vehicle speed as measured by wheel speed sensors and longitudinal acceleration.
          signal isVehSpdLgtCntr: start 47, 4 bit, big-endian, data-type-policy=NETWORK-REPRESENTATION-FROM-COM-SPEC, init-value=0, base-type=UInt4_2, compu-method=UInt4_1, category=VALUE, to SRS3  # Counter
          signal isVehSpdLgtChks: start 39, 8 bit, big-endian, data-type-policy=NETWORK-REPRESENTATION-FROM-COM-SPEC, init-value=0, base-type=UInt8_2, compu-method=UInt8_1, category=VALUE, to SRS3  # Checksum
          signal isVehSpdLgtA: start 22, 15 bit, big-endian, data-type-policy=NETWORK-REPRESENTATION-FROM-COM-SPEC, init-value=0, base-type=Spd1_2, compu-method=Spd1_1, category=VALUE, to SRS3  # Vehicle speed longitudinal based on wheel speed sensors and longitudinal acceleration.
          mapping igVehSpdLgt_mrx: i-signal-group=igVehSpdLgt, packing-byte-order=big-endian, start-position=22, update-indication-bit-position=23
      frame TcmbZCUDCAN1NMFr01: id 0x50B, to SRS3, frame-length=8, can-addressing-mode=STANDARD, can-fd-frame-support=false, can-frame-rx-behavior=CAN-20, rx-identifier-range={lower-can-id=1280, upper-can-id=1343}
        nm pdu TcmbZCUDCAN1NmPdu1: length=8, nm-vote-information=false, unused-bit-pattern=0
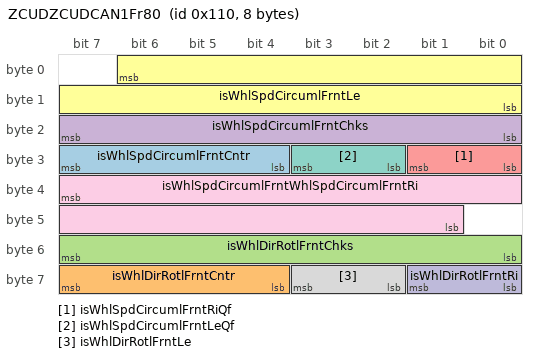
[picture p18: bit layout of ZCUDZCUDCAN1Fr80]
      frame ZCUDZCUDCAN1Fr80: id 0x110, to SRS3, frame-length=8, can-addressing-mode=STANDARD, can-fd-frame-support=false, can-frame-rx-behavior=CAN-20
        pdu ZCUDZCUDCAN1SignalIPdu80: length=8, unused-bit-pattern=0
          signal isWhlSpdCircumlFrntCntr: start 31, 4 bit, big-endian, data-type-policy=NETWORK-REPRESENTATION-FROM-COM-SPEC, init-value=0, base-type=UInt4_2, compu-method=UInt4_1, category=VALUE, to SRS3  # Individual wheel speed from front wheel speed sensors. Counter
          signal isWhlDirRotlFrntCntr: start 63, 4 bit, big-endian, data-type-policy=NETWORK-REPRESENTATION-FROM-COM-SPEC, init-value=0, base-type=UInt4_2, compu-method=UInt4_1, category=VALUE, to SRS3  # counter
          signal isWhlDirRotlFrntChks: start 55, 8 bit, big-endian, data-type-policy=NETWORK-REPRESENTATION-FROM-COM-SPEC, init-value=0, base-type=UInt8_2, compu-method=UInt8_1, category=VALUE, to SRS3  # check sum
          signal isWhlSpdCircumlFrntChks: start 23, 8 bit, big-endian, data-type-policy=NETWORK-REPRESENTATION-FROM-COM-SPEC, init-value=0, base-type=UInt8_2, compu-method=UInt8_1, category=VALUE, to SRS3  # Individual wheel speed from front wheel speed sensors. Checksum
          signal isWhlSpdCircumlFrntRiQf: start 25, 2 bit, big-endian, data-type-policy=NETWORK-REPRESENTATION-FROM-COM-SPEC, init-value=1, base-type=GenQf1_2, compu-method=GenQf1_1, category=VALUE, to SRS3  # Individual wheel speed from front wheel speed sensors. Qf for wheel speed sensor
          signal isWhlSpdCircumlFrntLe: start 6, 15 bit, big-endian, data-type-policy=NETWORK-REPRESENTATION-FROM-COM-SPEC, init-value=0, base-type=Spd1_2, compu-method=Spd1_1, category=VALUE, to SRS3  # Individual wheel speed from front wheel speed sensors. Wheel speed from front left wheel speed sensor using nominal value of wheel radius.
          signal isWhlSpdCircumlFrntLeQf: start 27, 2 bit, big-endian, data-type-policy=NETWORK-REPRESENTATION-FROM-COM-SPEC, init-value=1, base-type=GenQf1_2, compu-method=GenQf1_1, category=VALUE, to SRS3  # Individual wheel speed from front wheel speed sensors. Qf for wheel speed sensor
          signal isWhlDirRotlFrntLe: start 59, 2 bit, big-endian, data-type-policy=NETWORK-REPRESENTATION-FROM-COM-SPEC, init-value=0, base-type=WhlRotlDirStd1_2, compu-method=WhlRotlDirStd1_1, category=VALUE, to SRS3  # Rotational direction for the front individual wheels. Wheel rotation direction of front left wheel.
          signal isWhlSpdCircumlFrntWhlSpdCircumlFrntRi: start 39, 15 bit, big-endian, data-type-policy=NETWORK-REPRESENTATION-FROM-COM-SPEC, init-value=0, base-type=Spd1_2, compu-method=Spd1_1, category=VALUE, to SRS3  # Individual wheel speed from front wheel speed sensors. Wheel speed from front right wheel speed sensor using nominal value of wheel radius
          signal isWhlDirRotlFrntRi: start 57, 2 bit, big-endian, data-type-policy=NETWORK-REPRESENTATION-FROM-COM-SPEC, init-value=0, base-type=WhlRotlDirStd1_2, compu-method=WhlRotlDirStd1_1, category=VALUE, to SRS3  # Rotational direction for the front individual wheels. Wheel rotation direction of front right wheel.
          mapping igWhlSpdCircumlFrnt_mrx: i-signal-group=igWhlSpdCircumlFrnt, packing-byte-order=big-endian, start-position=6, update-indication-bit-position=7
          mapping igWhlDirRotlFrnt_mrx: i-signal-group=igWhlDirRotlFrnt, packing-byte-order=big-endian, start-position=55, update-indication-bit-position=40
      frame ZCUDZCUDCAN1Fr06: id 0x330, to SRS3, frame-length=8, can-addressing-mode=STANDARD, can-fd-frame-support=false, can-frame-rx-behavior=CAN-20
        pdu ZCUDZCUDCAN1SignalIPDU06: length=8, unused-bit-pattern=0
          signal isVehBattUSysUQf: start 47, 2 bit, big-endian, data-type-policy=NETWORK-REPRESENTATION-FROM-COM-SPEC, init-value=1, base-type=GenQf1_2, compu-method=GenQf1_1, category=VALUE, to SRS3  # Present vehicle voltage measured by CEM with QF
          signal isVehBattUSysU: start 39, 8 bit, big-endian, data-type-policy=NETWORK-REPRESENTATION-FROM-COM-SPEC, init-value=0, base-type=U1_2, compu-method=U1_1, category=VALUE, to SRS3  # Vehicle System Voltage At 12V side
          mapping igVehBattU_mrx: i-signal-group=igVehBattU, packing-byte-order=big-endian, start-position=39, update-indication-bit-position=45
      frame RmrZcudCAN1Fr01: id 0x175, to SRS3, frame-length=8, can-addressing-mode=STANDARD, can-fd-frame-support=false, can-frame-rx-behavior=CAN-20
        pdu RmrZcudCAN1SignalIPdu01: length=8, unused-bit-pattern=0
          signal isActvnStsOfRtrctrRvsbRi: start 3, 1 bit, big-endian, data-type-policy=NETWORK-REPRESENTATION-FROM-COM-SPEC, init-value=0, base-type=Enumeration1_2, compu-method=Enumeration1_1, update-indication-bit-position=6, to SRS3  # Signals to the SRS (and other nodes) that the belts have triggered.
          signal isStsForRtrctrRvsbRi: start 5, 2 bit, big-endian, data-type-policy=NETWORK-REPRESENTATION-FROM-COM-SPEC, init-value=1, base-type=NotOkOk_2, compu-method=NotOkOk_2, update-indication-bit-position=8, to SRS3  # Belt ready status
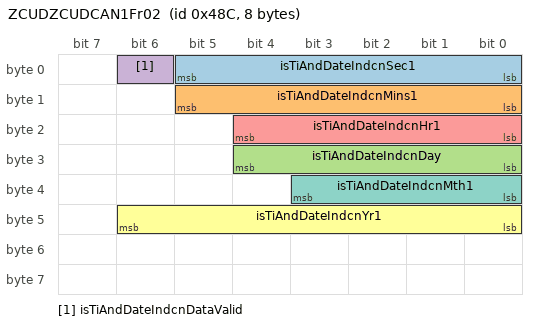
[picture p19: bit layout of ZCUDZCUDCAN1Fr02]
      frame ZCUDZCUDCAN1Fr02: id 0x48C, to SRS3, frame-length=8, can-addressing-mode=STANDARD, can-fd-frame-support=false, can-frame-rx-behavior=CAN-20
        pdu ZCUDZCUDCAN1SignalIPDU02: length=8, unused-bit-pattern=0
          signal isTiAndDateIndcnSec1: start 5, 6 bit, big-endian, data-type-policy=NETWORK-REPRESENTATION-FROM-COM-SPEC, init-value=0, base-type=Sec1_2, compu-method=Sec1_1, category=VALUE, to SRS3  # Current time (Hr, Min and Sec) and date (Year, Months and days) data for indication. See requirement for more information about the signals. Seconds
          signal isTiAndDateIndcnMins1: start 13, 6 bit, big-endian, data-type-policy=NETWORK-REPRESENTATION-FROM-COM-SPEC, init-value=0, base-type=Mins1_2, compu-method=Mins1_1, category=VALUE, to SRS3  # Current time (Hr, Min and Sec) and date (Year, Months and days) data for indication. See requirement for more information about the signals. Minutes
          signal isTiAndDateIndcnDay: start 28, 5 bit, big-endian, data-type-policy=NETWORK-REPRESENTATION-FROM-COM-SPEC, init-value=1, base-type=Day1_2, compu-method=Day1_1, category=VALUE, to SRS3  # Current time (Hr, Min and Sec) and date (Year, Months and days) data for indication. See requirement for more information about the signals. Day
          signal isTiAndDateIndcnDataValid: start 6, 1 bit, big-endian, data-type-policy=NETWORK-REPRESENTATION-FROM-COM-SPEC, init-value=0, base-type=NoYes1_2, compu-method=NoYes1_1, category=VALUE, to SRS3  # Current time (Hr, Min and Sec) and date (Year, Months and days) data for indication. See requirement for more information about the signals. Signal qualifier, No means values should be ignored.
          signal isTiAndDateIndcnHr1: start 20, 5 bit, big-endian, data-type-policy=NETWORK-REPRESENTATION-FROM-COM-SPEC, init-value=0, base-type=Hr1_2, compu-method=Hr1_1, category=VALUE, to SRS3  # Current time (Hr, Min and Sec) and date (Year, Months and days) data for indication. See requirement for more information about the signals. Hour
          signal isTiAndDateIndcnYr1: start 46, 7 bit, big-endian, data-type-policy=NETWORK-REPRESENTATION-FROM-COM-SPEC, init-value=0, base-type=Yr1_2, compu-method=Yr1_1, category=VALUE, to SRS3  # Current time (Hr, Min and Sec) and date (Year, Months and days) data for indication. See requirement for more information about the signals. Year, 0-99
          signal isTiAndDateIndcnMth1: start 35, 4 bit, big-endian, data-type-policy=NETWORK-REPRESENTATION-FROM-COM-SPEC, init-value=1, base-type=Mth1_2, compu-method=Mth1_1, category=VALUE, to SRS3  # Current time (Hr, Min and Sec) and date (Year, Months and days) data for indication. See requirement for more information about the signals. Month, 1-12
          mapping igTiAndDateIndcn_mrx: i-signal-group=igTiAndDateIndcn, packing-byte-order=big-endian, start-position=6, update-indication-bit-position=7
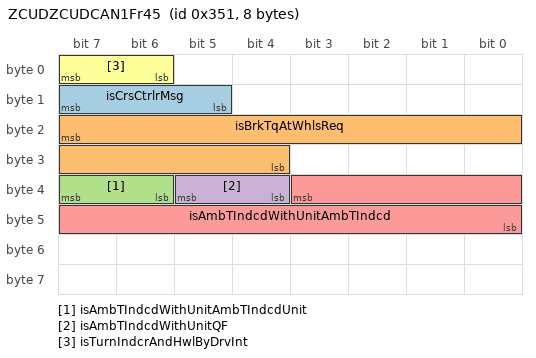
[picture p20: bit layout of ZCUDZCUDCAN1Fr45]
      frame ZCUDZCUDCAN1Fr45: id 0x351, to SRS3, frame-length=8, can-addressing-mode=STANDARD, can-fd-frame-support=false, can-frame-rx-behavior=CAN-20
        pdu ZCUDZCUDCAN1SignalIPDU45: length=8, unused-bit-pattern=0
          signal isCrsCtrlrMsg: start 15, 3 bit, big-endian, data-type-policy=NETWORK-REPRESENTATION-FROM-COM-SPEC, init-value=0, base-type=CrsCtrlrMsg1_2, compu-method=CrsCtrlrMsg1_1, update-indication-bit-position=12, to SRS3  # The signal triggers visual messages in DIM to inform the driver relevant information about the Cruise Controller
          signal isBrkTqAtWhlsReq: start 23, 12 bit, big-endian, data-type-policy=NETWORK-REPRESENTATION-FROM-COM-SPEC, init-value=0, base-type=Tq32_2, compu-method=Tq32_1, update-indication-bit-position=27, to SRS3  # Contains driver requested brake torque and driver support system requested brake torque. The signal is always positive and acts in opposite vehicle motion direction.
          signal isAmbTIndcdWithUnitAmbTIndcdUnit: start 39, 2 bit, big-endian, data-type-policy=NETWORK-REPRESENTATION-FROM-COM-SPEC, init-value=0, base-type=AmbTIndcdUnit_2, compu-method=AmbTIndcdUnit_1, category=VALUE, to SRS3  # Unit of the indicated temperature
          signal isAmbTIndcdWithUnitQF: start 37, 2 bit, big-endian, data-type-policy=NETWORK-REPRESENTATION-FROM-COM-SPEC, init-value=0, base-type=GenQf1_2, compu-method=GenQf1_1, category=VALUE, to SRS3  # QF
          signal isAmbTIndcdWithUnitAmbTIndcd: start 35, 12 bit, big-endian, data-type-policy=NETWORK-REPRESENTATION-FROM-COM-SPEC, init-value=1000, base-type=AmbTIndcd_2, compu-method=AmbTIndcd_1, category=VALUE, to SRS3  # Indicated ambient temperature
          signal isTurnIndcrAndHwlByDrvInt: start 7, 2 bit, big-endian, data-type-policy=NETWORK-REPRESENTATION-FROM-COM-SPEC, init-value=0, base-type=IndcrSts1_2, compu-method=IndcrSts1_1, update-indication-bit-position=5, to SRS3  # Combine turn switch signals and hazard lights signal
          mapping igAmbTIndcdWithUnit_mrx: i-signal-group=igAmbTIndcdWithUnit, packing-byte-order=big-endian, start-position=39, update-indication-bit-position=0
      frame ZCUDZCUDCAN1Fr09: id 0x371, to SRS3, frame-length=8, can-addressing-mode=STANDARD, can-fd-frame-support=false, can-frame-rx-behavior=CAN-20
        pdu ZCUDZCUDCAN1SignalIPDU09: length=8, unused-bit-pattern=0
          signal isEngN2: start 14, 15 bit, big-endian, data-type-policy=NETWORK-REPRESENTATION-FROM-COM-SPEC, init-value=0, base-type=N30_2, compu-method=N30_1, update-indication-bit-position=15, to SRS3  # Engine Speed [rpm]
          signal isCarModCrashSaved: start 7, 1 bit, big-endian, data-type-policy=NETWORK-REPRESENTATION-FROM-COM-SPEC, init-value=0, base-type=NoYes1_2, compu-method=NoYes1_1, update-indication-bit-position=6, to SRS3  # Boolean which states if Car Mode has been written to memory.
          signal isPostImpctBrkgRdy: start 29, 2 bit, big-endian, data-type-policy=NETWORK-REPRESENTATION-FROM-COM-SPEC, init-value=0, base-type=PostImpctBrkgRdy_2, compu-method=PostImpctBrkgRdy_1, update-indication-bit-position=30, to SRS3  # Information regarding if Post Impact Braking support is available from VDDM.
          signal isIsgSpdActSgn: start 39, 16 bit, big-endian, data-type-policy=NETWORK-REPRESENTATION-FROM-COM-SPEC, init-value=20000, base-type=MotSpd_1, compu-method=MotSpd_1, update-indication-bit-position=53, to SRS3  # Actual ISG speed with sign to indicate forward or backward direction
      frame ZCUDZCUDCAN1Fr96: id 0x235, to SRS3, frame-length=8, can-addressing-mode=STANDARD, can-fd-frame-support=false, can-frame-rx-behavior=CAN-20
        pdu ZCUDZCUDCAN1SignalIPdu96: length=8, unused-bit-pattern=0
          signal isBrkFricTqTotAtWhlsActCntr: start 31, 4 bit, big-endian, data-type-policy=NETWORK-REPRESENTATION-FROM-COM-SPEC, init-value=0, base-type=UInt4_2, compu-method=UInt4_1, category=VALUE, to SRS3  # Total actual friction brake toque at all four wheels. Counter
          signal isBrkFricTqTotAtWhlsActBrkFricTqTotAtWhlsAct: start 6, 15 bit, big-endian, data-type-policy=NETWORK-REPRESENTATION-FROM-COM-SPEC, init-value=0, base-type=Tq10_2, compu-method=Tq10_1, category=VALUE, to SRS3  # Total actual friction brake toque at all four wheels.
          signal isBrkFricTqTotAtWhlsActChks: start 23, 8 bit, big-endian, data-type-policy=NETWORK-REPRESENTATION-FROM-COM-SPEC, init-value=0, base-type=UInt8_2, compu-method=UInt8_1, category=VALUE, to SRS3  # Total actual friction brake toque at all four wheels. Checksum
          mapping igBrkFricTqTotAtWhlsAct_mrx: i-signal-group=igBrkFricTqTotAtWhlsAct, packing-byte-order=big-endian, start-position=6, update-indication-bit-position=7
      frame ZCUDZCUDCAN1Fr03: id 0xE0, to SRS3, frame-length=8, can-addressing-mode=STANDARD, can-fd-frame-support=false, can-frame-rx-behavior=CAN-20
        pdu ZCUDZCUDCAN1SignalIPDU03: length=8, unused-bit-pattern=0
          signal isDoorPassSts: start 31, 2 bit, big-endian, data-type-policy=NETWORK-REPRESENTATION-FROM-COM-SPEC, init-value=0, base-type=DoorSts2_2, compu-method=DoorSts2_1, update-indication-bit-position=29, to SRS3  # DoorPassSts - Passenger Door Status Ukwn - Unknown status Opend - Opened Clsd - Closed
          signal isDoorRiReSts: start 13, 2 bit, big-endian, data-type-policy=NETWORK-REPRESENTATION-FROM-COM-SPEC, init-value=0, base-type=DoorSts2_2, compu-method=DoorSts2_1, update-indication-bit-position=14, to SRS3  # DoorRiReSts - Right Rear Side Door Status Ukwn - Unknown status Opend - Opened Clsd - Closed
      frame ETCZCUDCAN1DevFr01: id 0x3C2, to SRS3, frame-length=8, can-addressing-mode=STANDARD, can-fd-frame-support=false, can-frame-rx-behavior=CAN-20
        pdu ETCZCUDCAN1DevSignalPdu01: length=8, unused-bit-pattern=0
          signal isSRSdevelpsignalgroupRXFunctiondevpsignalgroup6: start 47, 8 bit, big-endian, data-type-policy=NETWORK-REPRESENTATION-FROM-COM-SPEC, init-value=0, base-type=UInt8_2, compu-method=UInt8_1, category=VALUE, to SRS3  # SRS development signal
          signal isSRSdevelpsignalgroupRXFunctiondevpsignalgroup4: start 31, 8 bit, big-endian, data-type-policy=NETWORK-REPRESENTATION-FROM-COM-SPEC, init-value=0, base-type=UInt8_2, compu-method=UInt8_1, category=VALUE, to SRS3  # SRS development signal
          signal isSRSdevelpsignalgroupRXFunctiondevpsignalgroup7: start 55, 8 bit, big-endian, data-type-policy=NETWORK-REPRESENTATION-FROM-COM-SPEC, init-value=0, base-type=UInt8_2, compu-method=UInt8_1, category=VALUE, to SRS3  # SRS development signal
          signal isSRSdevelpsignalgroupRXFunctiondevpsignalgroup3: start 23, 8 bit, big-endian, data-type-policy=NETWORK-REPRESENTATION-FROM-COM-SPEC, init-value=0, base-type=UInt8_2, compu-method=UInt8_1, category=VALUE, to SRS3  # SRS development signal
          signal isSRSdevelpsignalgroupRXFunctiondevpsignalgroup2: start 15, 8 bit, big-endian, data-type-policy=NETWORK-REPRESENTATION-FROM-COM-SPEC, init-value=0, base-type=UInt8_2, compu-method=UInt8_1, category=VALUE, to SRS3  # SRS development signal
          signal isSRSdevelpsignalgroupRXFunctiondevpsignalgroup8: start 63, 8 bit, big-endian, data-type-policy=NETWORK-REPRESENTATION-FROM-COM-SPEC, init-value=0, base-type=UInt8_2, compu-method=UInt8_1, category=VALUE, to SRS3  # SRS development signal
          signal isSRSdevelpsignalgroupRXFunctiondevpsignalgroup5: start 39, 8 bit, big-endian, data-type-policy=NETWORK-REPRESENTATION-FROM-COM-SPEC, init-value=0, base-type=UInt8_2, compu-method=UInt8_1, category=VALUE, to SRS3  # SRS development signal
          signal isSRSdevelpsignalgroupRXFunctiondevpsignalgroup1: start 7, 8 bit, big-endian, data-type-policy=NETWORK-REPRESENTATION-FROM-COM-SPEC, init-value=0, base-type=UInt8_2, compu-method=UInt8_1, category=VALUE, to SRS3  # SRS development signal
          mapping igSRSdevelpsignalgroupRX_mrx: i-signal-group=igSRSdevelpsignalgroupRX, packing-byte-order=big-endian, start-position=7
      frame ZCUDZCUDCAN1Fr48: id 0x209, to SRS3, frame-length=8, can-addressing-mode=STANDARD, can-fd-frame-support=false, can-frame-rx-behavior=CAN-20
        pdu ZCUDZCUDCAN1SignalIPDU48: length=8, unused-bit-pattern=0
          signal isWhlMotSysSpdAct: start 7, 16 bit, big-endian, data-type-policy=NETWORK-REPRESENTATION-FROM-COM-SPEC, init-value=20000, base-type=MotSpd_1, compu-method=MotSpd_1, update-indication-bit-position=17, to SRS3  # The actual rotational speed of rear motor
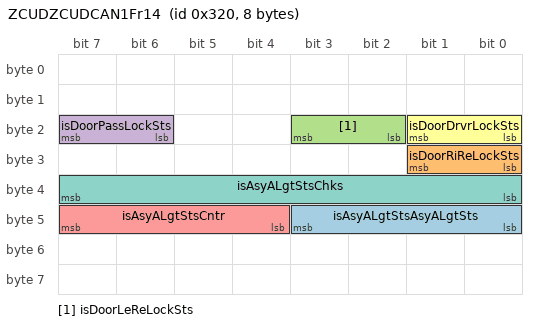
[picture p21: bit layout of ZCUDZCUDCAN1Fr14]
      frame ZCUDZCUDCAN1Fr14: id 0x320, to SRS3, frame-length=8, can-addressing-mode=STANDARD, can-fd-frame-support=false, can-frame-rx-behavior=CAN-20
        pdu ZCUDZCUDCAN1SignalIPDU14: length=8, unused-bit-pattern=0
          signal isAsyALgtStsAsyALgtSts: start 43, 4 bit, big-endian, data-type-policy=NETWORK-REPRESENTATION-FROM-COM-SPEC, init-value=0, base-type=AsyALgtSts_4, compu-method=AsyALgtSts_4, category=VALUE, to SRS3  # The signal indicates the status of the longitudinal control; off, passive, standby, active etc.
          signal isDoorRiReLockSts: start 25, 2 bit, big-endian, data-type-policy=NETWORK-REPRESENTATION-FROM-COM-SPEC, init-value=0, base-type=LockSts2_2, compu-method=LockSts2_1, update-indication-bit-position=61, to SRS3  # DoorRiReLockSts - Right Rear Door Lock Status Lock status LockStsUkwn - Lock Status Unknown Unlckd - Unlocked Lockd - Locked SafeLockd - Safe Locked (Double Locked)
          signal isDoorLeReLockSts: start 19, 2 bit, big-endian, data-type-policy=NETWORK-REPRESENTATION-FROM-COM-SPEC, init-value=0, base-type=LockSts2_2, compu-method=LockSts2_1, update-indication-bit-position=58, to SRS3  # DoorLeReLockSts - Left Rear Door Lock Status Lock status LockStsUkwn - Lock Status Unknown Unlckd - Unlocked Lockd - Locked SafeLockd - Safe Locked (Double Locked)
          signal isDoorPassLockSts: start 23, 2 bit, big-endian, data-type-policy=NETWORK-REPRESENTATION-FROM-COM-SPEC, init-value=0, base-type=LockSts2_2, compu-method=LockSts2_1, update-indication-bit-position=60, to SRS3  # DoorPassLockSts - Passenger Door Lock Status Lock status LockStsUkwn - Lock Status Unknown Unlckd - Unlocked Lockd - Locked SafeLockd - Safe Locked (Double Locked)
          signal isAsyALgtStsCntr: start 47, 4 bit, big-endian, data-type-policy=NETWORK-REPRESENTATION-FROM-COM-SPEC, init-value=0, base-type=UInt4_2, compu-method=UInt4_1, category=VALUE, to SRS3  # counter for E2E
          signal isDoorDrvrLockSts: start 17, 2 bit, big-endian, data-type-policy=NETWORK-REPRESENTATION-FROM-COM-SPEC, init-value=0, base-type=LockSts2_2, compu-method=LockSts2_1, update-indication-bit-position=57, to SRS3  # DoorDrvrLockSts - Driver Door Lock Status Lock status LockStsUkwn - Lock Status Unknown Unlckd - Unlocked Lockd - Locked SafeLockd - Safe Locked (Double Locked)
          signal isAsyALgtStsChks: start 39, 8 bit, big-endian, data-type-policy=NETWORK-REPRESENTATION-FROM-COM-SPEC, init-value=0, base-type=UInt8_2, compu-method=UInt8_1, category=VALUE, to SRS3  # check sum for E2E
          mapping igAsyALgtSts_mrx: i-signal-group=igAsyALgtSts, packing-byte-order=big-endian, start-position=39, update-indication-bit-position=63
      frame ZCUDZCUDCAN1Fr43: id 0x318, to SRS3, frame-length=8, can-addressing-mode=STANDARD, can-fd-frame-support=false, can-frame-rx-behavior=CAN-20
        pdu ZCUDZCUDCAN1SignalIPDU43: length=8, unused-bit-pattern=0
          signal isVehCfgPrmExt2CCPBytePosn6: start 47, 8 bit, big-endian, data-type-policy=NETWORK-REPRESENTATION-FROM-COM-SPEC, init-value=0, base-type=Nr2_3, compu-method=Nr2_1, category=VALUE, to SRS3  # CarConfigExtended2 BytePos6
          signal isVehCfgPrmExt2CCPBytePosn7: start 55, 8 bit, big-endian, data-type-policy=NETWORK-REPRESENTATION-FROM-COM-SPEC, init-value=0, base-type=Nr2_3, compu-method=Nr2_1, category=VALUE, to SRS3  # CarConfigExtended2 BytePos7
          signal isVehCfgPrmExt2BlkIDBytePosn1: start 7, 8 bit, big-endian, data-type-policy=NETWORK-REPRESENTATION-FROM-COM-SPEC, init-value=0, base-type=Nr2_3, compu-method=Nr2_1, category=VALUE, to SRS3  # CarConfigExtended2 BlockID
          signal isVehCfgPrmExt2CCPBytePosn5: start 39, 8 bit, big-endian, data-type-policy=NETWORK-REPRESENTATION-FROM-COM-SPEC, init-value=0, base-type=Nr2_3, compu-method=Nr2_1, category=VALUE, to SRS3  # CarConfigExtended2 BytePos5
          signal isVehCfgPrmExt2CCPBytePosn3: start 23, 8 bit, big-endian, data-type-policy=NETWORK-REPRESENTATION-FROM-COM-SPEC, init-value=0, base-type=Nr2_3, compu-method=Nr2_1, category=VALUE, to SRS3  # CarConfigExtended2 BytePos3
          signal isVehCfgPrmExt2CCPBytePosn2: start 15, 8 bit, big-endian, data-type-policy=NETWORK-REPRESENTATION-FROM-COM-SPEC, init-value=0, base-type=Nr2_3, compu-method=Nr2_1, category=VALUE, to SRS3  # CarConfigExtended2 BytePos2
          signal isVehCfgPrmExt2CCPBytePosn8: start 63, 8 bit, big-endian, data-type-policy=NETWORK-REPRESENTATION-FROM-COM-SPEC, init-value=0, base-type=Nr2_3, compu-method=Nr2_1, category=VALUE, to SRS3  # CarConfigExtended2 BytePos8
          signal isVehCfgPrmExt2CCPBytePosn4: start 31, 8 bit, big-endian, data-type-policy=NETWORK-REPRESENTATION-FROM-COM-SPEC, init-value=0, base-type=Nr2_3, compu-method=Nr2_1, category=VALUE, to SRS3  # CarConfigExtended2 BytePos4
          mapping igVehCfgPrmExt2_mrx: i-signal-group=igVehCfgPrmExt2, packing-byte-order=big-endian, start-position=7
      frame ZCUDZCUDCAN1Fr20: id 0x394, to SRS3, frame-length=8, can-addressing-mode=STANDARD, can-fd-frame-support=false, can-frame-rx-behavior=CAN-20
        pdu ZCUDZCUDCAN1SignalIPDU20: length=8, unused-bit-pattern=0
          signal isLeReTireMsgBattLoSt: start 47, 1 bit, big-endian, data-type-policy=NETWORK-REPRESENTATION-FROM-COM-SPEC, init-value=0, base-type=Normalwarning_2, compu-method=Normalwarning_2, category=VALUE, to SRS3  # battery low status
          signal isLeFrntTireMsgP: start 15, 8 bit, big-endian, data-type-policy=NETWORK-REPRESENTATION-FROM-COM-SPEC, init-value=255, base-type=Kpa8_1, compu-method=Kpa8_1, category=VALUE, to SRS3  # tire temperature
          signal isLeFrntTireMsgMsgOldFlg: start 5, 1 bit, big-endian, data-type-policy=NETWORK-REPRESENTATION-FROM-COM-SPEC, init-value=0, base-type=Normalwarning_2, compu-method=Normalwarning_2, category=VALUE, to SRS3  # message old flag
          signal isLeReTireMsgP: start 55, 8 bit, big-endian, data-type-policy=NETWORK-REPRESENTATION-FROM-COM-SPEC, init-value=255, base-type=Kpa8_1, compu-method=Kpa8_1, category=VALUE, to SRS3  # tire temperature
          signal isLeReTireMsgT: start 63, 8 bit, big-endian, data-type-policy=NETWORK-REPRESENTATION-FROM-COM-SPEC, init-value=255, base-type=T8_1, compu-method=T8_1, category=VALUE, to SRS3  # tire pressure
          signal isLeReTireMsgTireFillgAssiPSts: start 40, 1 bit, big-endian, data-type-policy=NETWORK-REPRESENTATION-FROM-COM-SPEC, init-value=0, base-type=Normalwarning_2, compu-method=Normalwarning_2, category=VALUE, to SRS3  # tire fill status
          signal isLeFrntTireMsgTireFillgAssiPSts: start 0, 1 bit, big-endian, data-type-policy=NETWORK-REPRESENTATION-FROM-COM-SPEC, init-value=0, base-type=Normalwarning_2, compu-method=Normalwarning_2, category=VALUE, to SRS3  # tire fill status
          signal isLeFrntTireMsgPWarnFlg: start 4, 2 bit, big-endian, data-type-policy=NETWORK-REPRESENTATION-FROM-COM-SPEC, init-value=0, base-type=PWarnFlg_2, compu-method=PWarnFlg_2, category=VALUE, to SRS3  # pressure warn flag
          signal isLeReTireMsgFastLoseWarnFlg: start 46, 1 bit, big-endian, data-type-policy=NETWORK-REPRESENTATION-FROM-COM-SPEC, init-value=0, base-type=Normalwarning_2, compu-method=Normalwarning_2, category=VALUE, to SRS3  # fast lost warn flag
          signal isLeReTireMsgMsgOldFlg: start 45, 1 bit, big-endian, data-type-policy=NETWORK-REPRESENTATION-FROM-COM-SPEC, init-value=0, base-type=Normalwarning_2, compu-method=Normalwarning_2, category=VALUE, to SRS3  # message old flag
          signal isLeFrntTireMsgTWarnFlg: start 1, 1 bit, big-endian, data-type-policy=NETWORK-REPRESENTATION-FROM-COM-SPEC, init-value=0, base-type=Normalwarning_2, compu-method=Normalwarning_2, category=VALUE, to SRS3  # temperature warn flag
          signal isLeReTireMsgSysWarnFlg: start 42, 1 bit, big-endian, data-type-policy=NETWORK-REPRESENTATION-FROM-COM-SPEC, init-value=0, base-type=Normalwarning_2, compu-method=Normalwarning_2, category=VALUE, to SRS3  # system warn flag
          signal isLeFrntTireMsgSysWarnFlg: start 2, 1 bit, big-endian, data-type-policy=NETWORK-REPRESENTATION-FROM-COM-SPEC, init-value=0, base-type=Normalwarning_2, compu-method=Normalwarning_2, category=VALUE, to SRS3  # system warn flag
          signal isLeFrntTireMsgFastLoseWarnFlg: start 6, 1 bit, big-endian, data-type-policy=NETWORK-REPRESENTATION-FROM-COM-SPEC, init-value=0, base-type=Normalwarning_2, compu-method=Normalwarning_2, category=VALUE, to SRS3  # fast lost warn flag
          signal isLeFrntTireMsgT: start 23, 8 bit, big-endian, data-type-policy=NETWORK-REPRESENTATION-FROM-COM-SPEC, init-value=255, base-type=T8_1, compu-method=T8_1, category=VALUE, to SRS3  # tire pressure
          signal isLeFrntTireMsgBattLoSt: start 7, 1 bit, big-endian, data-type-policy=NETWORK-REPRESENTATION-FROM-COM-SPEC, init-value=0, base-type=Normalwarning_2, compu-method=Normalwarning_2, category=VALUE, to SRS3  # battery low status
          signal isLeReTireMsgPWarnFlg: start 44, 2 bit, big-endian, data-type-policy=NETWORK-REPRESENTATION-FROM-COM-SPEC, init-value=0, base-type=PWarnFlg_2, compu-method=PWarnFlg_2, category=VALUE, to SRS3  # pressure warn flag
          signal isLeReTireMsgTWarnFlg: start 41, 1 bit, big-endian, data-type-policy=NETWORK-REPRESENTATION-FROM-COM-SPEC, init-value=0, base-type=Normalwarning_2, compu-method=Normalwarning_2, category=VALUE, to SRS3  # temperature warn flag
          mapping igLeFrntTireMsg_mrx: i-signal-group=igLeFrntTireMsg, packing-byte-order=big-endian, start-position=7, update-indication-bit-position=31
          mapping igLeReTireMsg_mrx: i-signal-group=igLeReTireMsg, packing-byte-order=big-endian, start-position=47, update-indication-bit-position=30
      frame ZCUDZCUDCAN1Fr30: id 0x131, to SRS3, frame-length=8, can-addressing-mode=STANDARD, can-fd-frame-support=false, can-frame-rx-behavior=CAN-20
        pdu ZCUDZCUDCAN1SignalIPDU30: length=8, unused-bit-pattern=0
          signal isVehSpdIndcdVeSpdIndcdUnit: start 18, 2 bit, big-endian, data-type-policy=NETWORK-REPRESENTATION-FROM-COM-SPEC, init-value=0, base-type=VehSpdIndcdUnit_2, compu-method=VehSpdIndcdUnit_1, category=VALUE, to SRS3  # Unit for vehicle speed
          signal isEpbStsEpbSts: start 15, 4 bit, big-endian, data-type-policy=NETWORK-REPRESENTATION-FROM-COM-SPEC, init-value=0, base-type=EpbSts_2, compu-method=EpbSts_1, category=VALUE, to SRS3  # Electrical Park Brake system status information Status for the rear wheel park actuator
          signal isEpbStsCntr: start 11, 4 bit, big-endian, data-type-policy=NETWORK-REPRESENTATION-FROM-COM-SPEC, init-value=0, base-type=UInt4_2, compu-method=UInt4_1, category=VALUE, to SRS3  # Electrical Park Brake system status information Counter for EPB status
          signal isEpbStsChks: start 7, 8 bit, big-endian, data-type-policy=NETWORK-REPRESENTATION-FROM-COM-SPEC, init-value=0, base-type=UInt8_2, compu-method=UInt8_1, category=VALUE, to SRS3  # Electrical Park Brake system status information Status for the rear wheel park actuator
          signal isVehSpdIndcdVehSpdIndcd: start 16, 9 bit, big-endian, data-type-policy=NETWORK-REPRESENTATION-FROM-COM-SPEC, init-value=0, base-type=Nr32_2, compu-method=Nr32_1, category=VALUE, to SRS3  # Vehicle speed
          mapping igVehSpdIndcd_mrx: i-signal-group=igVehSpdIndcd, packing-byte-order=big-endian, start-position=18, update-indication-bit-position=19
          mapping igEpbSts_mrx: i-signal-group=igEpbSts, packing-byte-order=big-endian, start-position=7, update-indication-bit-position=50
      frame ZCUDZCUDCAN1Fr31: id 0x78, to SRS3, frame-length=8, can-addressing-mode=STANDARD, can-fd-frame-support=false, can-frame-rx-behavior=CAN-20
        pdu ZCUDZCUDCAN1SignalIPDU31: length=8, unused-bit-pattern=0
          signal isSwtIndcrIndcrTypExtReq: start 5, 2 bit, big-endian, data-type-policy=NETWORK-REPRESENTATION-FROM-COM-SPEC, init-value=0, base-type=IndcrTypExt1_2, compu-method=IndcrTypExt1_1, category=VALUE, to SRS3  # Signal represent status of the turn stalk swich
          signal isGearLvrIndcn: start 54, 3 bit, big-endian, data-type-policy=NETWORK-REPRESENTATION-FROM-COM-SPEC, init-value=7, base-type=GearLvrIndcn2_2, compu-method=GearLvrIndcn2_1, update-indication-bit-position=55, to SRS3  # Gear lever indication (drivetrain position) to the driver. If drivetrain position is not possible to decide signal is set to undefined. Valid for automatic vehicles.
          signal isSwtIndcrIndcrTypExtReqToUpdQf: start 1, 2 bit, big-endian, data-type-policy=NETWORK-REPRESENTATION-FROM-COM-SPEC, init-value=1, base-type=Qf1_2, compu-method=Qf1_1, category=VALUE, to SRS3  # Qf
          signal isSwtIndcrIndcrTypExtReqChks: start 15, 8 bit, big-endian, data-type-policy=NETWORK-REPRESENTATION-FROM-COM-SPEC, init-value=0, base-type=UInt8_2, compu-method=UInt8_1, category=VALUE, to SRS3  # Checksum
          signal isSwtIndcrIndcrTypExtReqCntr: start 3, 2 bit, big-endian, data-type-policy=NETWORK-REPRESENTATION-FROM-COM-SPEC, init-value=0, base-type=UInt2_2, compu-method=UInt2_1, category=VALUE, to SRS3  # Counter
          mapping igSwtIndcr_mrx: i-signal-group=igSwtIndcr, packing-byte-order=big-endian, start-position=5, update-indication-bit-position=6
      frame ZCUDZCUDCAN1Fr11: id 0x39C, to SRS3, frame-length=8, can-addressing-mode=STANDARD, can-fd-frame-support=false, can-frame-rx-behavior=CAN-20
        pdu ZCUDZCUDCAN1SignalIPDU11: length=8, unused-bit-pattern=0
          signal isRiFrntTireMsgTireFillgAssiPSts: start 0, 1 bit, big-endian, data-type-policy=NETWORK-REPRESENTATION-FROM-COM-SPEC, init-value=0, base-type=Normalwarning_2, compu-method=Normalwarning_2, category=VALUE, to SRS3  # tire fill status
          signal isRiFrntTireMsgSysWarnFlg: start 2, 1 bit, big-endian, data-type-policy=NETWORK-REPRESENTATION-FROM-COM-SPEC, init-value=0, base-type=Normalwarning_2, compu-method=Normalwarning_2, category=VALUE, to SRS3  # system warn flag
          signal isRiFrntTireMsgPWarnFlg: start 4, 2 bit, big-endian, data-type-policy=NETWORK-REPRESENTATION-FROM-COM-SPEC, init-value=0, base-type=PWarnFlg_2, compu-method=PWarnFlg_2, category=VALUE, to SRS3  # pressure warn flag
          signal isRiFrntTireMsgMsgOldFlg: start 5, 1 bit, big-endian, data-type-policy=NETWORK-REPRESENTATION-FROM-COM-SPEC, init-value=0, base-type=Normalwarning_2, compu-method=Normalwarning_2, category=VALUE, to SRS3  # message old flag
          signal isRiFrntTireMsgBattLoSt: start 7, 1 bit, big-endian, data-type-policy=NETWORK-REPRESENTATION-FROM-COM-SPEC, init-value=0, base-type=Normalwarning_2, compu-method=Normalwarning_2, category=VALUE, to SRS3  # battery low status
          signal isRiReTireMsgP: start 55, 8 bit, big-endian, data-type-policy=NETWORK-REPRESENTATION-FROM-COM-SPEC, init-value=255, base-type=Kpa8_1, compu-method=Kpa8_1, category=VALUE, to SRS3  # tire temperature
          signal isRiReTireMsgTWarnFlg: start 41, 1 bit, big-endian, data-type-policy=NETWORK-REPRESENTATION-FROM-COM-SPEC, init-value=0, base-type=Normalwarning_2, compu-method=Normalwarning_2, category=VALUE, to SRS3  # temperature warn flag
          signal isRiReTireMsgSysWarnFlg: start 42, 1 bit, big-endian, data-type-policy=NETWORK-REPRESENTATION-FROM-COM-SPEC, init-value=0, base-type=Normalwarning_2, compu-method=Normalwarning_2, category=VALUE, to SRS3  # system warn flag
          signal isRiFrntTireMsgT: start 23, 8 bit, big-endian, data-type-policy=NETWORK-REPRESENTATION-FROM-COM-SPEC, init-value=255, base-type=T8_1, compu-method=T8_1, category=VALUE, to SRS3  # tire pressure
          signal isRiReTireMsgMsgOldFlg: start 45, 1 bit, big-endian, data-type-policy=NETWORK-REPRESENTATION-FROM-COM-SPEC, init-value=0, base-type=Normalwarning_2, compu-method=Normalwarning_2, category=VALUE, to SRS3  # message old flag
          signal isRiFrntTireMsgP: start 15, 8 bit, big-endian, data-type-policy=NETWORK-REPRESENTATION-FROM-COM-SPEC, init-value=255, base-type=Kpa8_1, compu-method=Kpa8_1, category=VALUE, to SRS3  # tire temperature
          signal isRiReTireMsgTireFillgAssiPSts: start 40, 1 bit, big-endian, data-type-policy=NETWORK-REPRESENTATION-FROM-COM-SPEC, init-value=0, base-type=Normalwarning_2, compu-method=Normalwarning_2, category=VALUE, to SRS3  # tire fill status
          signal isRiReTireMsgPWarnFlg: start 44, 2 bit, big-endian, data-type-policy=NETWORK-REPRESENTATION-FROM-COM-SPEC, init-value=0, base-type=PWarnFlg_2, compu-method=PWarnFlg_2, category=VALUE, to SRS3  # pressure warn flag
          signal isRiFrntTireMsgTWarnFlg: start 1, 1 bit, big-endian, data-type-policy=NETWORK-REPRESENTATION-FROM-COM-SPEC, init-value=0, base-type=Normalwarning_2, compu-method=Normalwarning_2, category=VALUE, to SRS3  # temperature warn flag
          signal isRiReTireMsgBattLoSt: start 47, 1 bit, big-endian, data-type-policy=NETWORK-REPRESENTATION-FROM-COM-SPEC, init-value=0, base-type=Normalwarning_2, compu-method=Normalwarning_2, category=VALUE, to SRS3  # battery low status
          signal isRiReTireMsgFastLoseWarnFlg: start 46, 1 bit, big-endian, data-type-policy=NETWORK-REPRESENTATION-FROM-COM-SPEC, init-value=0, base-type=Normalwarning_2, compu-method=Normalwarning_2, category=VALUE, to SRS3  # fast lost warn flag
          signal isRiReTireMsgT: start 63, 8 bit, big-endian, data-type-policy=NETWORK-REPRESENTATION-FROM-COM-SPEC, init-value=255, base-type=T8_1, compu-method=T8_1, category=VALUE, to SRS3  # tire pressure
          signal isRiFrntTireMsgFastLoseWarnFlg: start 6, 1 bit, big-endian, data-type-policy=NETWORK-REPRESENTATION-FROM-COM-SPEC, init-value=0, base-type=Normalwarning_2, compu-method=Normalwarning_2, category=VALUE, to SRS3  # fast lost warn flag
          mapping igRiFrntTireMsg_mrx: i-signal-group=igRiFrntTireMsg, packing-byte-order=big-endian, start-position=7, update-indication-bit-position=31
          mapping igRiReTireMsg_mrx: i-signal-group=igRiReTireMsg, packing-byte-order=big-endian, start-position=47, update-indication-bit-position=30
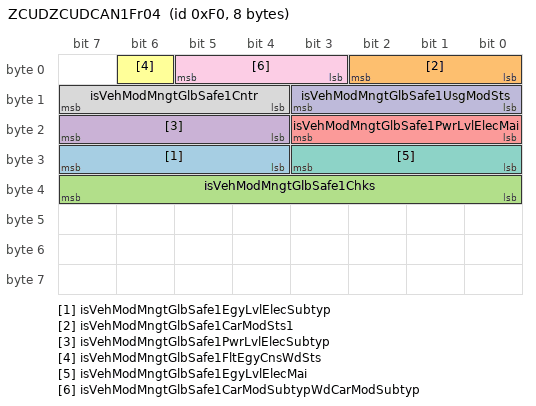
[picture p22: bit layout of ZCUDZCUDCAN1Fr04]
      frame ZCUDZCUDCAN1Fr04: id 0xF0, to SRS3, frame-length=8, can-addressing-mode=STANDARD, can-fd-frame-support=false, can-frame-rx-behavior=CAN-20
        pdu ZCUDZCUDCAN1SignalIPDU04: length=8, unused-bit-pattern=0
          signal isVehModMngtGlbSafe1EgyLvlElecSubtyp: start 31, 4 bit, big-endian, data-type-policy=NETWORK-REPRESENTATION-FROM-COM-SPEC, init-value=0, base-type=UInt4_2, compu-method=UInt4_1, category=VALUE, to SRS3  # Substate of the energy level in the vehicle.
          signal isVehModMngtGlbSafe1CarModSts1: start 2, 3 bit, big-endian, data-type-policy=NETWORK-REPRESENTATION-FROM-COM-SPEC, init-value=0, base-type=CarModSts1_2, compu-method=CarModSts1_1, category=VALUE, to SRS3  # CarMode Status
          signal isVehModMngtGlbSafe1Chks: start 39, 8 bit, big-endian, data-type-policy=NETWORK-REPRESENTATION-FROM-COM-SPEC, init-value=0, base-type=UInt8_2, compu-method=UInt8_1, category=VALUE, to SRS3  # Checksum
          signal isVehModMngtGlbSafe1PwrLvlElecSubtyp: start 23, 4 bit, big-endian, data-type-policy=NETWORK-REPRESENTATION-FROM-COM-SPEC, init-value=0, base-type=UInt4_2, compu-method=UInt4_1, category=VALUE, to SRS3  # Substate of the power level in the vehicle.
          signal isVehModMngtGlbSafe1PwrLvlElecMai: start 19, 4 bit, big-endian, data-type-policy=NETWORK-REPRESENTATION-FROM-COM-SPEC, init-value=0, base-type=UInt4_2, compu-method=UInt4_1, category=VALUE, to SRS3  # Main Power level in the vehicle.
          signal isVehModMngtGlbSafe1FltEgyCnsWdSts: start 6, 1 bit, big-endian, data-type-policy=NETWORK-REPRESENTATION-FROM-COM-SPEC, init-value=0, base-type=FltEgyCns1_2, compu-method=FltEgyCns1_1, category=VALUE, to SRS3  # High quiescent current detected by CEM via BMS.
          signal isVehModMngtGlbSafe1EgyLvlElecMai: start 27, 4 bit, big-endian, data-type-policy=NETWORK-REPRESENTATION-FROM-COM-SPEC, init-value=0, base-type=UInt4_2, compu-method=UInt4_1, category=VALUE, to SRS3  # Main energy level in the vehicle.
          signal isVehModMngtGlbSafe1Cntr: start 15, 4 bit, big-endian, data-type-policy=NETWORK-REPRESENTATION-FROM-COM-SPEC, init-value=0, base-type=UInt4_2, compu-method=UInt4_1, category=VALUE, to SRS3  # Counter
          signal isVehModMngtGlbSafe1CarModSubtypWdCarModSubtyp: start 5, 3 bit, big-endian, data-type-policy=NETWORK-REPRESENTATION-FROM-COM-SPEC, init-value=0, base-type=Nr5_2, compu-method=Nr5_1, category=VALUE, to SRS3  # CarMode substate status
          signal isVehModMngtGlbSafe1UsgModSts: start 11, 4 bit, big-endian, data-type-policy=NETWORK-REPRESENTATION-FROM-COM-SPEC, init-value=1, base-type=UsgModSts1_2, compu-method=UsgModSts1_1, category=VALUE, to SRS3  # UsageMode Status
          mapping igVehModMngtGlbSafe1_mrx: i-signal-group=igVehModMngtGlbSafe1, packing-byte-order=big-endian, start-position=6, update-indication-bit-position=7
      frame ZCUDZCUDCAN1Fr36: id 0x80, to SRS3, frame-length=8, can-addressing-mode=STANDARD, can-fd-frame-support=false, can-frame-rx-behavior=CAN-20
        pdu ZCUDZCUDCAN1SignalIPDU36: length=8, unused-bit-pattern=0
          signal isVinVINSignalPos1: start 15, 8 bit, big-endian, data-type-policy=NETWORK-REPRESENTATION-FROM-COM-SPEC, init-value=0, base-type=Nr2_3, compu-method=Nr2_1, category=VALUE, to SRS3  # VIN byte 1. Used for character 1, 8 and 15.
          signal isVinVINSignalPos7: start 63, 8 bit, big-endian, data-type-policy=NETWORK-REPRESENTATION-FROM-COM-SPEC, init-value=0, base-type=Nr2_3, compu-method=Nr2_1, category=VALUE, to SRS3  # VIN byte 7. Used for character 7 and 14.
          signal isVinVINSignalPos6: start 55, 8 bit, big-endian, data-type-policy=NETWORK-REPRESENTATION-FROM-COM-SPEC, init-value=0, base-type=Nr2_3, compu-method=Nr2_1, category=VALUE, to SRS3  # VIN byte 6. Used for character 6 and 13.
          signal isVinVINSignalPos4: start 39, 8 bit, big-endian, data-type-policy=NETWORK-REPRESENTATION-FROM-COM-SPEC, init-value=0, base-type=Nr2_3, compu-method=Nr2_1, category=VALUE, to SRS3  # VIN byte 4. Used for character 4 and 11.
          signal isVinVINSignalPos5: start 47, 8 bit, big-endian, data-type-policy=NETWORK-REPRESENTATION-FROM-COM-SPEC, init-value=0, base-type=Nr2_3, compu-method=Nr2_1, category=VALUE, to SRS3  # VIN byte 5. Used for character 5 and 12.
          signal isVinVINSignalPos2: start 23, 8 bit, big-endian, data-type-policy=NETWORK-REPRESENTATION-FROM-COM-SPEC, init-value=0, base-type=Nr2_3, compu-method=Nr2_1, category=VALUE, to SRS3  # VIN byte 2. Used for character 2, 9 and 16.
          signal isVinBlockNr: start 7, 8 bit, big-endian, data-type-policy=NETWORK-REPRESENTATION-FROM-COM-SPEC, init-value=0, base-type=Nr2_3, compu-method=Nr2_1, category=VALUE, to SRS3  # VIN number block counter.
          signal isVinVINSignalPos3: start 31, 8 bit, big-endian, data-type-policy=NETWORK-REPRESENTATION-FROM-COM-SPEC, init-value=0, base-type=Nr2_3, compu-method=Nr2_1, category=VALUE, to SRS3  # VIN byte 3. Used for character 3, 10 and 17.
          mapping igVin_mrx: i-signal-group=igVin, packing-byte-order=big-endian, start-position=7
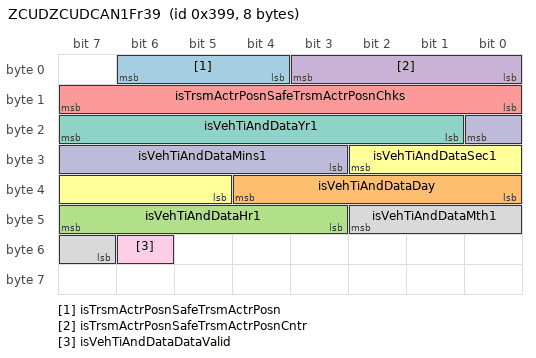
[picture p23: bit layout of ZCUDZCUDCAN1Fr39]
      frame ZCUDZCUDCAN1Fr39: id 0x399, to SRS3, frame-length=8, can-addressing-mode=STANDARD, can-fd-frame-support=false, can-frame-rx-behavior=CAN-20
        pdu ZCUDZCUDCAN1SignalIPDU39: length=8, unused-bit-pattern=0
          signal isTrsmActrPosnSafeTrsmActrPosn: start 6, 3 bit, big-endian, data-type-policy=NETWORK-REPRESENTATION-FROM-COM-SPEC, init-value=7, base-type=TrsmActrPosn1_2, compu-method=TrsmActrPosn1_1, category=VALUE, to SRS3  # Describes the transmission position (P, R, N, D). Can also take intermediate positions (PR, RN, ND). If error are detected on position sensors undefined is set. Transmission measured gear lever position
          signal isVehTiAndDataDay: start 36, 5 bit, big-endian, data-type-policy=NETWORK-REPRESENTATION-FROM-COM-SPEC, init-value=1, base-type=Day1_2, compu-method=Day1_1, category=VALUE, to SRS3  # Vehicle time (Hr, Min and Sec) and date (Year, Months and days) data for indication. See requirement for more information about the signals. Day
          signal isVehTiAndDataHr1: start 47, 5 bit, big-endian, data-type-policy=NETWORK-REPRESENTATION-FROM-COM-SPEC, init-value=0, base-type=Hr1_2, compu-method=Hr1_1, category=VALUE, to SRS3  # Vehicle time (Hr, Min and Sec) and date (Year, Months and days) data for indication. See requirement for more information about the signals. Hour
          signal isTrsmActrPosnSafeTrsmActrPosnCntr: start 3, 4 bit, big-endian, data-type-policy=NETWORK-REPRESENTATION-FROM-COM-SPEC, init-value=0, base-type=UInt4_2, compu-method=UInt4_1, category=VALUE, to SRS3  # Describes the transmission position (P, R, N, D). Can also take intermediate positions (PR, RN, ND). If error are detected on position sensors undefined is set. Transmission measured gear lever position
          signal isTrsmActrPosnSafeTrsmActrPosnChks: start 15, 8 bit, big-endian, data-type-policy=NETWORK-REPRESENTATION-FROM-COM-SPEC, init-value=0, base-type=UInt8_2, compu-method=UInt8_1, category=VALUE, to SRS3  # Describes the transmission position (P, R, N, D). Can also take intermediate positions (PR, RN, ND). If error are detected on position sensors undefined is set. Transmission measured gear lever position
          signal isVehTiAndDataSec1: start 26, 6 bit, big-endian, data-type-policy=NETWORK-REPRESENTATION-FROM-COM-SPEC, init-value=0, base-type=Sec1_2, compu-method=Sec1_1, category=VALUE, to SRS3  # Vehicle time (Hr, Min and Sec) and date (Year, Months and days) data for indication. See requirement for more information about the signals. Seconds
          signal isVehTiAndDataYr1: start 23, 7 bit, big-endian, data-type-policy=NETWORK-REPRESENTATION-FROM-COM-SPEC, init-value=0, base-type=Yr1_2, compu-method=Yr1_1, category=VALUE, to SRS3  # Vehicle time (Hr, Min and Sec) and date (Year, Months and days) data for indication. See requirement for more information about the signals. Year, 0-99
          signal isVehTiAndDataMth1: start 42, 4 bit, big-endian, data-type-policy=NETWORK-REPRESENTATION-FROM-COM-SPEC, init-value=1, base-type=Mth1_2, compu-method=Mth1_1, category=VALUE, to SRS3  # Vehicle time (Hr, Min and Sec) and date (Year, Months and days) data for indication. See requirement for more information about the signals. Month, 1-12
          signal isVehTiAndDataDataValid: start 54, 1 bit, big-endian, data-type-policy=NETWORK-REPRESENTATION-FROM-COM-SPEC, init-value=0, base-type=NoYes1_2, compu-method=NoYes1_1, category=VALUE, to SRS3  # Vehicle time (Hr, Min and Sec) and date (Year, Months and days) data for indication. See requirement for more information about the signals. Signal qualifier, No means values should be ignored.
          signal isVehTiAndDataMins1: start 16, 6 bit, big-endian, data-type-policy=NETWORK-REPRESENTATION-FROM-COM-SPEC, init-value=0, base-type=Mins1_2, compu-method=Mins1_1, category=VALUE, to SRS3  # Vehicle time (Hr, Min and Sec) and date (Year, Months and days) data for indication. See requirement for more information about the signals. Minutes
          mapping igVehTiAndData_mrx: i-signal-group=igVehTiAndData, packing-byte-order=big-endian, start-position=23, update-indication-bit-position=53
          mapping igTrsmActrPosnSafe_mrx: i-signal-group=igTrsmActrPosnSafe, packing-byte-order=big-endian, start-position=6, update-indication-bit-position=7
      pdu triggering PduTrEtcToSrsISO26021DiagDcmIpdu11: pdu=EtcToSrsISO26021DiagDcmIpdu11, to SRS3
      pdu triggering PduTrDhuToSrsDiagDcmIpdu: pdu=DhuToSrsDiagDcmIpdu, to SRS3
      pdu triggering PduTrDhuToAllFuncDiagDcmIpdu: pdu=DhuToAllFuncDiagDcmIpdu, to SRS3
      pdu triggering PduTrSrsToEtcISO26021DiagDcmIpdu11: pdu=SrsToEtcISO26021DiagDcmIpdu11, from SRS3
      pdu triggering PduTrSrsToDhuDiagDcmIpdu: pdu=SrsToDhuDiagDcmIpdu, from SRS3
